VERSION ""

NS_ :

BS_:

BU_: MDC PAS

BO_ 1722 PDCDistance: 20 Vector__XXX
 SG_ PDC_SensorRRSDis : 131|12@0+ (1,0) [0|3276] "cm" Vector__XXX
 SG_ PDC_SensorRRMDis : 107|12@0+ (1,0) [0|3276] "cm" Vector__XXX
 SG_ PDC_SensorRRCDis : 127|12@0+ (1,0) [0|3276] "cm" Vector__XXX
 SG_ PDC_SensorRLSDis : 79|12@0+ (1,0) [0|3276] "cm" Vector__XXX
 SG_ PDC_SensorRLMDis : 103|12@0+ (1,0) [0|3276] "cm" Vector__XXX
 SG_ PDC_SensorRLCDis : 83|12@0+ (1,0) [0|3276] "cm" Vector__XXX
 SG_ PDC_SensorFRSDis : 59|12@0+ (1,0) [0|3276] "cm" Vector__XXX
 SG_ PDC_SensorFRMDis : 35|12@0+ (1,0) [0|3276] "cm" Vector__XXX
 SG_ PDC_SensorFRCDis : 55|12@0+ (1,0) [0|3276] "cm" Vector__XXX
 SG_ PDC_SensorFLSDis : 7|12@0+ (1,0) [0|3276] "cm" Vector__XXX
 SG_ PDC_SensorFLMDis : 31|12@0+ (1,0) [0|3276] "cm" Vector__XXX
 SG_ PDC_SensorFLCDis : 11|12@0+ (1,0) [0|3276] "cm" Vector__XXX

BO_ 1617 PDC: 12 Vector__XXX
 SG_ PDC_RRSSectorWarning : 85|3@0+ (1,0) [0|7] "" Vector__XXX
 SG_ PDC_RRMSectorWarning : 42|3@0+ (1,0) [0|7] "" Vector__XXX
 SG_ PDC_RRCSectorWarning : 45|3@0+ (1,0) [0|7] "" Vector__XXX
 SG_ PDC_RMSSectorWarning : 82|3@0+ (1,0) [0|7] "" Vector__XXX
 SG_ PDC_RLSSectorWarning : 74|3@0+ (1,0) [0|7] "" Vector__XXX
 SG_ PDC_RLMSectorWarning : 37|3@0+ (1,0) [0|7] "" Vector__XXX
 SG_ PDC_RLCSectorWarning : 34|3@0+ (1,0) [0|7] "" Vector__XXX
 SG_ PDC_RearObjNearDis : 51|12@0+ (1,0) [0|3276] "cm" Vector__XXX
 SG_ PDC_LMSSectorWarning : 69|3@0+ (1,0) [0|7] "" Vector__XXX
 SG_ PDC_FRSSectorWarning : 77|3@0+ (1,0) [0|7] "" Vector__XXX
 SG_ PDC_FrontObjNearDis : 19|12@0+ (1,0) [0|3276] "cm" Vector__XXX
 SG_ PDC_FRMSectorWarning : 10|3@0+ (1,0) [0|7] "" Vector__XXX
 SG_ PDC_FRCSectorWarning : 13|3@0+ (1,0) [0|7] "" Vector__XXX
 SG_ PDC_FLSSectorWarning : 66|3@0+ (1,0) [0|7] "" Vector__XXX
 SG_ PDC_FLMSectorWarning : 5|3@0+ (1,0) [0|7] "" Vector__XXX
 SG_ PDC_FLCSectorWarning : 2|3@0+ (1,0) [0|7] "" Vector__XXX

BO_ 1616 SensorInfo_RawDis: 48 Vector__XXX
 SG_ SensorRRS_RawDis_1 : 275|12@0+ (1,0) [0|3276] "cm" Vector__XXX
 SG_ SensorRRM_RawDis_1 : 251|12@0+ (1,0) [0|3276] "cm" Vector__XXX
 SG_ SensorRRC_RawDis_1 : 271|12@0+ (1,0) [0|3276] "cm" Vector__XXX
 SG_ SensorRLS_RawDis_1 : 223|12@0+ (1,0) [0|3276] "cm" Vector__XXX
 SG_ SensorRLM_RawDis_1 : 247|12@0+ (1,0) [0|3276] "cm" Vector__XXX
 SG_ SensorRLC_RawDis_1 : 227|12@0+ (1,0) [0|3276] "cm" Vector__XXX
 SG_ SensorFRM_RawDis_1 : 175|12@0+ (1,0) [0|3276] "cm" Vector__XXX
 SG_ SensorFRC_RawDis_1 : 155|12@0+ (1,0) [0|3276] "cm" Vector__XXX
 SG_ SensorFLS_RawDis_1 : 203|12@0+ (1,0) [0|3276] "cm" Vector__XXX
 SG_ SensorFLM_RawDis_1 : 179|12@0+ (1,0) [0|3276] "cm" Vector__XXX
 SG_ SensorFLC_RawDis_1 : 199|12@0+ (1,0) [0|3276] "cm" Vector__XXX
 SG_ SensorFRS_RawDis_1 : 151|12@0+ (1,0) [0|3276] "cm" Vector__XXX
 SG_ SensorRRS_RawDis : 131|12@0+ (1,0) [0|3276] "cm" Vector__XXX
 SG_ SensorRRC_RawDis : 127|12@0+ (1,0) [0|3276] "cm" Vector__XXX
 SG_ SensorRRM_RawDis : 107|12@0+ (1,0) [0|3276] "cm" Vector__XXX
 SG_ SensorRLM_RawDis : 103|12@0+ (1,0) [0|3276] "cm" Vector__XXX
 SG_ SensorRLC_RawDis : 83|12@0+ (1,0) [0|3276] "cm" Vector__XXX
 SG_ SensorRLS_RawDis : 79|12@0+ (1,0) [0|3276] "cm" Vector__XXX
 SG_ SensorFLS_RawDis : 59|12@0+ (1,0) [0|3276] "cm" Vector__XXX
 SG_ SensorFLC_RawDis : 55|12@0+ (1,0) [0|3276] "cm" Vector__XXX
 SG_ SensorFLM_RawDis : 35|12@0+ (1,0) [0|3276] "cm" Vector__XXX
 SG_ SensorFRM_RawDis : 31|12@0+ (1,0) [0|3276] "cm" Vector__XXX
 SG_ SensorFRC_RawDis : 11|12@0+ (1,0) [0|3276] "cm" Vector__XXX
 SG_ SensorFRS_RawDis : 7|12@0+ (1,0) [0|3276] "cm" Vector__XXX

BO_ 1600 CarInfo: 64 Vector__XXX
 SG_ VehiclePosition_Angle_BeforeRst : 151|16@0+ (0.1,-180) [-180|180] "deg" Vector__XXX
 SG_ VehiclePosition_Y_BeforeRst : 135|16@0+ (1,-3276) [-3276|3276] "cm" Vector__XXX
 SG_ VehiclePosition_X_BeforeRst : 119|16@0+ (1,-3276) [-3276|3276] "cm" Vector__XXX
 SG_ VehiclePosition_Angle_Self : 103|16@0+ (0.1,-180) [-180|180] "deg" Vector__XXX
 SG_ VehiclePosition_Y_Self : 87|16@0+ (1,-3276) [-3276|3276] "cm" Vector__XXX
 SG_ VehiclePosition_X_Self : 71|16@0+ (1,-3276) [-3276|3276] "cm" Vector__XXX
 SG_ VehiclePosition_Y : 23|16@0+ (1,-3276) [-3276|3276] "cm" Vector__XXX
 SG_ VehiclePosition_X : 7|16@0+ (1,-3276) [-3276|3276] "cm" Vector__XXX
 SG_ VehiclePosition_speed : 52|13@0+ (0.05625,0) [0|270] "km/h" Vector__XXX
 SG_ VehiclePosition_Gear : 55|3@0+ (1,0) [0|7] "" Vector__XXX
 SG_ VehiclePosition_Angle : 39|16@0+ (0.1,-180) [-180|180] "deg" Vector__XXX

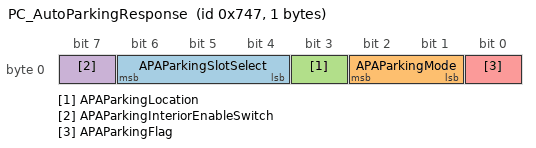
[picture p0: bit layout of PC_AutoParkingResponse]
BO_ 1863 PC_AutoParkingResponse: 1 Vector__XXX
 SG_ APAParkingSlotSelect : 6|3@0+ (1,0) [0|5] "" Vector__XXX
 SG_ APAParkingMode : 2|2@0+ (1,0) [0|3] "" Vector__XXX
 SG_ APAParkingLocation : 3|1@0+ (1,0) [0|1] "" Vector__XXX
 SG_ APAParkingInteriorEnableSwitch : 7|1@0+ (1,0) [0|1] "" Vector__XXX
 SG_ APAParkingFlag : 0|1@0+ (1,0) [0|1] "" Vector__XXX

BO_ 1862 LeftParkingSlot4_5: 48 Vector__XXX
 SG_ Left_ParkingSlot5_PtFY : 283|13@0+ (1,-3276) [-3276|3276] "cm" Vector__XXX
 SG_ Left_ParkingSlot5_PtFX : 264|13@0+ (1,-3276) [-3276|3276] "cm" Vector__XXX
 SG_ Left_ParkingSlot5_PtEY : 261|13@0+ (1,-3276) [-3276|3276] "cm" Vector__XXX
 SG_ Left_ParkingSlot5_PtEX : 242|13@0+ (1,-3276) [-3276|3276] "cm" Vector__XXX
 SG_ Left_ParkingSlot5_PtDY : 239|13@0+ (1,-3276) [-3276|3276] "cm" Vector__XXX
 SG_ Left_ParkingSlot5_PtDX : 220|13@0+ (1,-3276) [-3276|3276] "cm" Vector__XXX
 SG_ Left_ParkingSlot5_PtCY : 201|13@0+ (1,-3276) [-3276|3276] "cm" Vector__XXX
 SG_ Left_ParkingSlot5_PtCX : 198|13@0+ (1,-3276) [-3276|3276] "cm" Vector__XXX
 SG_ Left_ParkingSlot5_PtBY : 179|13@0+ (1,-3276) [-3276|3276] "cm" Vector__XXX
 SG_ Left_ParkingSlot5_PtBX : 160|13@0+ (1,-3276) [-3276|3276] "cm" Vector__XXX
 SG_ Left_ParkingSlot5_PtAY : 157|13@0+ (1,-3276) [-3276|3276] "cm" Vector__XXX
 SG_ Left_ParkingSlot5_PtAX : 138|13@0+ (1,-3276) [-3276|3276] "cm" Vector__XXX
 SG_ Left_ParkingSlot5_Depth : 131|9@0+ (1,0) [0|511] "cm" Vector__XXX
 SG_ Left_ParkingSlot5_Length : 127|12@0+ (1,0) [0|3276] "cm" Vector__XXX
 SG_ LeftParkingSlot5_HeightProperty : 117|3@0+ (1,0) [0|7] "%" Vector__XXX
 SG_ Left_ParkingSlot5_Type : 114|3@0+ (1,0) [0|7] "" Vector__XXX
 SG_ Left_ParkingSlot5_ID : 103|16@0+ (1,0) [0|65535] "" Vector__XXX
 SG_ Left_ParkingSlot4_PtFY : 73|13@0+ (1,-3276) [-3276|3276] "cm" Vector__XXX
 SG_ Left_ParkingSlot4_PtFX : 70|13@0+ (1,-3276) [-3276|3276] "cm" Vector__XXX
 SG_ Left_ParkingSlot4_PtEY : 51|13@0+ (1,-3276) [-3276|3276] "cm" Vector__XXX
 SG_ Left_ParkingSlot4_PtEX : 32|13@0+ (1,-3276) [-3276|3276] "cm" Vector__XXX
 SG_ Left_ParkingSlot4_PtDY : 29|13@0+ (1,-3276) [-3276|3276] "cm" Vector__XXX
 SG_ Left_ParkingSlot4_PtDX : 10|13@0+ (1,-3276) [-3276|3276] "cm" Vector__XXX
 SG_ Left_ParkingSlot4_PtCY : 7|13@0+ (1,-3276) [-3276|3276] "cm" Vector__XXX

BO_ 1721 LeftParkingSlot2_4: 48 Vector__XXX
 SG_ Left_ParkingSlot4_PtCX : 350|13@0+ (1,-3276) [-3276|3276] "cm" Vector__XXX
 SG_ Left_ParkingSlot4_PtBY : 331|13@0+ (1,-3276) [-3276|3276] "cm" Vector__XXX
 SG_ Left_ParkingSlot4_PtBX : 312|13@0+ (1,-3276) [-3276|3276] "cm" Vector__XXX
 SG_ Left_ParkingSlot4_PtAY : 309|13@0+ (1,-3276) [-3276|3276] "cm" Vector__XXX
 SG_ Left_ParkingSlot4_PtAX : 290|13@0+ (1,-3276) [-3276|3276] "cm" Vector__XXX
 SG_ Left_ParkingSlot4_Depth : 283|9@0+ (1,0) [0|511] "cm" Vector__XXX
 SG_ Left_ParkingSlot4_Length : 279|12@0+ (1,0) [0|3276] "cm" Vector__XXX
 SG_ LeftParkingSlot4_HeightProperty : 269|3@0+ (1,0) [0|7] "%" Vector__XXX
 SG_ Left_ParkingSlot4_Type : 266|3@0+ (1,0) [0|7] "" Vector__XXX
 SG_ Left_ParkingSlot4_ID : 255|16@0+ (1,0) [0|65535] "" Vector__XXX
 SG_ Left_ParkingSlot3_PtFY : 227|13@0+ (1,-3276) [-3276|3276] "cm" Vector__XXX
 SG_ Left_ParkingSlot3_PtFX : 208|13@0+ (1,-3276) [-3276|3276] "cm" Vector__XXX
 SG_ Left_ParkingSlot3_PtEY : 205|13@0+ (1,-3276) [-3276|3276] "cm" Vector__XXX
 SG_ Left_ParkingSlot3_PtEX : 186|13@0+ (1,-3276) [-3276|3276] "cm" Vector__XXX
 SG_ Left_ParkingSlot3_PtDY : 183|13@0+ (1,-3276) [-3276|3276] "cm" Vector__XXX
 SG_ Left_ParkingSlot3_PtDX : 164|13@0+ (1,-3276) [-3276|3276] "cm" Vector__XXX
 SG_ Left_ParkingSlot3_PtCY : 145|13@0+ (1,-3276) [-3276|3276] "cm" Vector__XXX
 SG_ Left_ParkingSlot3_PtCX : 142|13@0+ (1,-3276) [-3276|3276] "cm" Vector__XXX
 SG_ Left_ParkingSlot3_PtBY : 123|13@0+ (1,-3276) [-3276|3276] "cm" Vector__XXX
 SG_ Left_ParkingSlot3_PtBX : 104|13@0+ (1,-3276) [-3276|3276] "cm" Vector__XXX
 SG_ Left_ParkingSlot3_PtAY : 101|13@0+ (1,-3276) [-3276|3276] "cm" Vector__XXX
 SG_ Left_ParkingSlot3_PtAX : 82|13@0+ (1,-3276) [-3276|3276] "cm" Vector__XXX
 SG_ Left_ParkingSlot3_Depth : 75|9@0+ (1,0) [0|511] "cm" Vector__XXX
 SG_ Left_ParkingSlot3_Length : 71|12@0+ (1,0) [0|3276] "cm" Vector__XXX
 SG_ LeftParkingSlot3_HeightProperty : 61|3@0+ (1,0) [0|7] "%" Vector__XXX
 SG_ Left_ParkingSlot3_Type : 58|3@0+ (1,0) [0|7] "" Vector__XXX
 SG_ Left_ParkingSlot3_ID : 47|16@0+ (1,0) [0|65535] "" Vector__XXX
 SG_ Left_ParkingSlot2_PtFY : 29|13@0+ (1,-3276) [-3276|3276] "cm" Vector__XXX
 SG_ Left_ParkingSlot2_PtFX : 10|13@0+ (1,-3276) [-3276|3276] "cm" Vector__XXX
 SG_ Left_ParkingSlot2_PtEY : 7|13@0+ (1,-3276) [-3276|3276] "cm" Vector__XXX

BO_ 1720 LeftParkingSlot1_2: 48 PAS
 SG_ Left_ParkingSlot2_PtEX : 354|13@0+ (1,-3276) [-3276|3276] "cm" Vector__XXX
 SG_ Left_ParkingSlot2_PtDY : 351|13@0+ (1,-3276) [-3276|3276] "cm" Vector__XXX
 SG_ Left_ParkingSlot2_PtDX : 332|13@0+ (1,-3276) [-3276|3276] "cm" Vector__XXX
 SG_ Left_ParkingSlot2_PtCY : 313|13@0+ (1,-3276) [-3276|3276] "cm" Vector__XXX
 SG_ Left_ParkingSlot2_PtCX : 310|13@0+ (1,-3276) [-3276|3276] "cm" Vector__XXX
 SG_ Left_ParkingSlot2_PtBY : 291|13@0+ (1,-3276) [-3276|3276] "cm" Vector__XXX
 SG_ Left_ParkingSlot2_PtBX : 272|13@0+ (1,-3276) [-3276|3276] "cm" Vector__XXX
 SG_ Left_ParkingSlot2_PtAY : 269|13@0+ (1,-3276) [-3276|3276] "cm" Vector__XXX
 SG_ Left_ParkingSlot2_PtAX : 250|13@0+ (1,-3276) [-3276|3276] "cm" Vector__XXX
 SG_ Left_ParkingSlot2_Depth : 243|9@0+ (1,0) [0|511] "cm" Vector__XXX
 SG_ Left_ParkingSlot2_Length : 239|12@0+ (1,0) [0|3276] "cm" Vector__XXX
 SG_ LeftParkingSlot2_HeightProperty : 229|3@0+ (1,0) [0|7] "%" Vector__XXX
 SG_ Left_ParkingSlot2_Type : 226|3@0+ (1,0) [0|7] "" Vector__XXX
 SG_ Left_ParkingSlot2_ID : 215|16@0+ (1,0) [0|65535] "" Vector__XXX
 SG_ Left_ParkingSlot1_PtFY : 187|13@0+ (1,-3276) [-3276|3276] "cm" Vector__XXX
 SG_ Left_ParkingSlot1_PtFX : 168|13@0+ (1,-3276) [-3276|3276] "cm" Vector__XXX
 SG_ Left_ParkingSlot1_PtEY : 165|13@0+ (1,-3276) [-3276|3276] "cm" Vector__XXX
 SG_ Left_ParkingSlot1_PtEX : 146|13@0+ (1,-3276) [-3276|3276] "cm" Vector__XXX
 SG_ Left_ParkingSlot1_PtDY : 143|13@0+ (1,-3276) [-3276|3276] "cm" Vector__XXX
 SG_ Left_ParkingSlot1_PtDX : 124|13@0+ (1,-3276) [-3276|3276] "cm" Vector__XXX
 SG_ Left_ParkingSlot1_PtCY : 105|13@0+ (1,-3276) [-3276|3276] "cm" Vector__XXX
 SG_ Left_ParkingSlot1_PtCX : 102|13@0+ (1,-3276) [-3276|3276] "cm" Vector__XXX
 SG_ Left_ParkingSlot1_PtBY : 83|13@0+ (1,-3276) [-3276|3276] "cm" Vector__XXX
 SG_ Left_ParkingSlot1_PtBX : 64|13@0+ (1,-3276) [-3276|3276] "cm" Vector__XXX
 SG_ Left_ParkingSlot1_PtAY : 61|13@0+ (1,-3276) [-3276|3276] "cm" Vector__XXX
 SG_ Left_ParkingSlot1_PtAX : 42|13@0+ (1,-3276) [-3276|3276] "cm" Vector__XXX
 SG_ Left_ParkingSlot1_Depth : 35|9@0+ (1,0) [0|511] "cm" Vector__XXX
 SG_ Left_ParkingSlot1_Length : 31|12@0+ (1,0) [0|3276] "cm" Vector__XXX
 SG_ LeftParkingSlot1_HeightProperty : 21|3@0+ (1,0) [0|7] "%" Vector__XXX
 SG_ Left_ParkingSlot1_Type : 18|3@0+ (1,0) [0|7] "" Vector__XXX
 SG_ Left_ParkingSlot1_ID : 7|16@0+ (1,0) [0|65535] ""  MDC

BO_ 1859 RightParkingSlot4_5: 48 Vector__XXX
 SG_ Right_ParkingSlot5_PtFY : 283|13@0+ (1,-3276) [-3276|3276] "cm" Vector__XXX
 SG_ Right_ParkingSlot5_PtFX : 264|13@0+ (1,-3276) [-3276|3276] "cm" Vector__XXX
 SG_ Right_ParkingSlot5_PtEY : 261|13@0+ (1,-3276) [-3276|3276] "cm" Vector__XXX
 SG_ Right_ParkingSlot5_PtEX : 242|13@0+ (1,-3276) [-3276|3276] "cm" Vector__XXX
 SG_ Right_ParkingSlot5_PtDY : 239|13@0+ (1,-3276) [-3276|3276] "cm" Vector__XXX
 SG_ Right_ParkingSlot5_PtDX : 220|13@0+ (1,-3276) [-3276|3276] "cm" Vector__XXX
 SG_ Right_ParkingSlot5_PtCY : 201|13@0+ (1,-3276) [-3276|3276] "cm" Vector__XXX
 SG_ Right_ParkingSlot5_PtCX : 198|13@0+ (1,-3276) [-3276|3276] "cm" Vector__XXX
 SG_ Right_ParkingSlot5_PtBY : 179|13@0+ (1,-3276) [-3276|3276] "cm" Vector__XXX
 SG_ Right_ParkingSlot5_PtBX : 160|13@0+ (1,-3276) [-3276|3276] "cm" Vector__XXX
 SG_ Right_ParkingSlot5_PtAY : 157|13@0+ (1,-3276) [-3276|3276] "cm" Vector__XXX
 SG_ Right_ParkingSlot5_PtAX : 138|13@0+ (1,-3276) [-3276|3276] "cm" Vector__XXX
 SG_ Right_ParkingSlot5_Depth : 131|9@0+ (1,0) [0|511] "cm" Vector__XXX
 SG_ Right_ParkingSlot5_Length : 127|12@0+ (1,0) [0|3276] "cm" Vector__XXX
 SG_ RightParkingSlot5_HeightProperty : 117|3@0+ (1,0) [0|7] "%" Vector__XXX
 SG_ Right_ParkingSlot5_Type : 114|3@0+ (1,0) [0|7] "" Vector__XXX
 SG_ Right_ParkingSlot5_ID : 103|16@0+ (1,0) [0|65535] "" Vector__XXX
 SG_ Right_ParkingSlot4_PtFY : 73|13@0+ (1,-3276) [-3276|3276] "cm" Vector__XXX
 SG_ Right_ParkingSlot4_PtFX : 70|13@0+ (1,-3276) [-3276|3276] "cm" Vector__XXX
 SG_ Right_ParkingSlot4_PtEY : 51|13@0+ (1,-3276) [-3276|3276] "cm" Vector__XXX
 SG_ Right_ParkingSlot4_PtEX : 32|13@0+ (1,-3276) [-3276|3276] "cm" Vector__XXX
 SG_ Right_ParkingSlot4_PtDY : 29|13@0+ (1,-3276) [-3276|3276] "cm" Vector__XXX
 SG_ Right_ParkingSlot4_PtDX : 10|13@0+ (1,-3276) [-3276|3276] "cm" Vector__XXX
 SG_ Right_ParkingSlot4_PtCY : 7|13@0+ (1,-3276) [-3276|3276] "cm" Vector__XXX

BO_ 1719 RightParkingSlot2_4: 48 Vector__XXX
 SG_ Right_ParkingSlot4_PtCX : 350|13@0+ (1,-3276) [-3276|3276] "cm" Vector__XXX
 SG_ Right_ParkingSlot4_PtBY : 331|13@0+ (1,-3276) [-3276|3276] "cm" Vector__XXX
 SG_ Right_ParkingSlot4_PtBX : 312|13@0+ (1,-3276) [-3276|3276] "cm" Vector__XXX
 SG_ Right_ParkingSlot4_PtAY : 309|13@0+ (1,-3276) [-3276|3276] "cm" Vector__XXX
 SG_ Right_ParkingSlot4_PtAX : 290|13@0+ (1,-3276) [-3276|3276] "cm" Vector__XXX
 SG_ Right_ParkingSlot4_Depth : 283|9@0+ (1,0) [0|511] "cm" Vector__XXX
 SG_ Right_ParkingSlot4_Length : 279|12@0+ (1,0) [0|3276] "cm" Vector__XXX
 SG_ RightParkingSlot4_HeightProperty : 269|3@0+ (1,0) [0|7] "%" Vector__XXX
 SG_ Right_ParkingSlot4_Type : 266|3@0+ (1,0) [0|7] "" Vector__XXX
 SG_ Right_ParkingSlot4_ID : 255|16@0+ (1,0) [0|65535] "" Vector__XXX
 SG_ Right_ParkingSlot3_PtFY : 227|13@0+ (1,-3276) [-3276|3276] "cm" Vector__XXX
 SG_ Right_ParkingSlot3_PtFX : 208|13@0+ (1,-3276) [-3276|3276] "cm" Vector__XXX
 SG_ Right_ParkingSlot3_PtEY : 205|13@0+ (1,-3276) [-3276|3276] "cm" Vector__XXX
 SG_ Right_ParkingSlot3_PtEX : 186|13@0+ (1,-3276) [-3276|3276] "cm" Vector__XXX
 SG_ Right_ParkingSlot3_PtDY : 183|13@0+ (1,-3276) [-3276|3276] "cm" Vector__XXX
 SG_ Right_ParkingSlot3_PtDX : 164|13@0+ (1,-3276) [-3276|3276] "cm" Vector__XXX
 SG_ Right_ParkingSlot3_PtCY : 145|13@0+ (1,-3276) [-3276|3276] "cm" Vector__XXX
 SG_ Right_ParkingSlot3_PtCX : 142|13@0+ (1,-3276) [-3276|3276] "cm" Vector__XXX
 SG_ Right_ParkingSlot3_PtBY : 123|13@0+ (1,-3276) [-3276|3276] "cm" Vector__XXX
 SG_ Right_ParkingSlot3_PtBX : 104|13@0+ (1,-3276) [-3276|3276] "cm" Vector__XXX
 SG_ Right_ParkingSlot3_PtAY : 101|13@0+ (1,-3276) [-3276|3276] "cm" Vector__XXX
 SG_ Right_ParkingSlot3_PtAX : 82|13@0+ (1,-3276) [-3276|3276] "cm" Vector__XXX
 SG_ Right_ParkingSlot3_Depth : 75|9@0+ (1,0) [0|511] "cm" Vector__XXX
 SG_ Right_ParkingSlot3_Length : 71|12@0+ (1,0) [0|3276] "cm" Vector__XXX
 SG_ RightParkingSlot3_HeightProperty : 61|3@0+ (1,0) [0|7] "%" Vector__XXX
 SG_ Right_ParkingSlot3_Type : 58|3@0+ (1,0) [0|7] "" Vector__XXX
 SG_ Right_ParkingSlot3_ID : 47|16@0+ (1,0) [0|65535] "" Vector__XXX
 SG_ Right_ParkingSlot2_PtFY : 29|13@0+ (1,-3276) [-3276|3276] "cm" Vector__XXX
 SG_ Right_ParkingSlot2_PtFX : 10|13@0+ (1,-3276) [-3276|3276] "cm" Vector__XXX
 SG_ Right_ParkingSlot2_PtEY : 7|13@0+ (1,-3276) [-3276|3276] "cm" Vector__XXX

BO_ 1718 RightParkingSlot1_2: 48 PAS
 SG_ Right_ParkingSlot2_PtEX : 354|13@0+ (1,-3276) [-3276|3276] "cm" Vector__XXX
 SG_ Right_ParkingSlot2_PtDY : 351|13@0+ (1,-3276) [-3276|3276] "cm" Vector__XXX
 SG_ Right_ParkingSlot2_PtDX : 332|13@0+ (1,-3276) [-3276|3276] "cm" Vector__XXX
 SG_ Right_ParkingSlot2_PtCY : 313|13@0+ (1,-3276) [-3276|3276] "cm" Vector__XXX
 SG_ Right_ParkingSlot2_PtCX : 310|13@0+ (1,-3276) [-3276|3276] "cm" Vector__XXX
 SG_ Right_ParkingSlot2_PtBY : 291|13@0+ (1,-3276) [-3276|3276] "cm" Vector__XXX
 SG_ Right_ParkingSlot2_PtBX : 272|13@0+ (1,-3276) [-3276|3276] "cm" Vector__XXX
 SG_ Right_ParkingSlot2_PtAY : 269|13@0+ (1,-3276) [-3276|3276] "cm" Vector__XXX
 SG_ Right_ParkingSlot2_PtAX : 250|13@0+ (1,-3276) [-3276|3276] "cm" Vector__XXX
 SG_ Right_ParkingSlot2_Depth : 243|9@0+ (1,0) [0|511] "cm" Vector__XXX
 SG_ Right_ParkingSlot2_Length : 239|12@0+ (1,0) [0|3276] "cm" Vector__XXX
 SG_ RightParkingSlot2_HeightProperty : 229|3@0+ (1,0) [0|7] "%" Vector__XXX
 SG_ Right_ParkingSlot2_Type : 226|3@0+ (1,0) [0|7] "" Vector__XXX
 SG_ Right_ParkingSlot2_ID : 215|16@0+ (1,0) [0|65535] "" Vector__XXX
 SG_ Right_ParkingSlot1_PtFY : 187|13@0+ (1,-3276) [-3276|3276] "cm" Vector__XXX
 SG_ Right_ParkingSlot1_PtFX : 168|13@0+ (1,-3276) [-3276|3276] "cm" Vector__XXX
 SG_ Right_ParkingSlot1_PtEY : 165|13@0+ (1,-3276) [-3276|3276] "cm" Vector__XXX
 SG_ Right_ParkingSlot1_PtEX : 146|13@0+ (1,-3276) [-3276|3276] "cm" Vector__XXX
 SG_ Right_ParkingSlot1_PtDY : 143|13@0+ (1,-3276) [-3276|3276] "cm" Vector__XXX
 SG_ Right_ParkingSlot1_PtDX : 124|13@0+ (1,-3276) [-3276|3276] "cm" Vector__XXX
 SG_ Right_ParkingSlot1_PtCY : 105|13@0+ (1,-3276) [-3276|3276] "cm" Vector__XXX
 SG_ Right_ParkingSlot1_PtCX : 102|13@0+ (1,-3276) [-3276|3276] "cm" Vector__XXX
 SG_ Right_ParkingSlot1_PtBY : 83|13@0+ (1,-3276) [-3276|3276] "cm" Vector__XXX
 SG_ Right_ParkingSlot1_PtBX : 64|13@0+ (1,-3276) [-3276|3276] "cm" Vector__XXX
 SG_ Right_ParkingSlot1_PtAY : 61|13@0+ (1,-3276) [-3276|3276] "cm" Vector__XXX
 SG_ Right_ParkingSlot1_PtAX : 42|13@0+ (1,-3276) [-3276|3276] "cm" Vector__XXX
 SG_ Right_ParkingSlot1_Depth : 35|9@0+ (1,0) [0|511] "cm" Vector__XXX
 SG_ Right_ParkingSlot1_Length : 31|12@0+ (1,0) [0|3276] "cm" Vector__XXX
 SG_ RightParkingSlot1_HeightProperty : 21|3@0+ (1,0) [0|7] "%" Vector__XXX
 SG_ Right_ParkingSlot1_Type : 18|3@0+ (1,0) [0|7] "" Vector__XXX
 SG_ Right_ParkingSlot1_ID : 7|16@0+ (1,0) [0|65535] ""  MDC

BO_ 1622 ObjPointInfo_Probability_108_119: 24 PAS
 SG_ Point_119_ExistProbability : 166|7@0+ (1,0) [0|127] "%" Vector__XXX
 SG_ Point_119_AttributeProbability : 157|7@0+ (1,0) [0|127] "%" Vector__XXX
 SG_ Point_118_ExistProbability : 139|7@0+ (1,0) [0|127] "%" Vector__XXX
 SG_ Point_118_AttributeProbability : 148|7@0+ (1,0) [0|127] "%" Vector__XXX
 SG_ Point_117_ExistProbability : 121|7@0+ (1,0) [0|127] "%" Vector__XXX
 SG_ Point_117_AttributeProbability : 130|7@0+ (1,0) [0|127] "%" Vector__XXX
 SG_ Point_116_ExistProbability : 119|7@0+ (1,0) [0|127] "%" Vector__XXX
 SG_ Point_116_AttributeProbability : 112|7@0+ (1,0) [0|127] "%" Vector__XXX
 SG_ Point_115_ExistProbability : 110|7@0+ (1,0) [0|127] "%" Vector__XXX
 SG_ Point_115_AttributeProbability : 101|7@0+ (1,0) [0|127] "%" Vector__XXX
 SG_ Point_114_ExistProbability : 83|7@0+ (1,0) [0|127] "%" Vector__XXX
 SG_ Point_114_AttributeProbability : 92|7@0+ (1,0) [0|127] "%" Vector__XXX
 SG_ Point_113_ExistProbability : 65|7@0+ (1,0) [0|127] "%" Vector__XXX
 SG_ Point_113_AttributeProbability : 74|7@0+ (1,0) [0|127] "%" Vector__XXX
 SG_ Point_112_ExistProbability : 63|7@0+ (1,0) [0|127] "%" Vector__XXX
 SG_ Point_112_AttributeProbability : 56|7@0+ (1,0) [0|127] "%" Vector__XXX
 SG_ Point_111_ExistProbability : 54|7@0+ (1,0) [0|127] "%" Vector__XXX
 SG_ Point_111_AttributeProbability : 45|7@0+ (1,0) [0|127] "%" Vector__XXX
 SG_ Point_110_ExistProbability : 27|7@0+ (1,0) [0|127] "%" Vector__XXX
 SG_ Point_110_AttributeProbability : 36|7@0+ (1,0) [0|127] "%" Vector__XXX
 SG_ Point_109_ExistProbability : 9|7@0+ (1,0) [0|127] "%" Vector__XXX
 SG_ Point_109_AttributeProbability : 18|7@0+ (1,0) [0|127] "%" Vector__XXX
 SG_ Point_108_ExistProbability : 7|7@0+ (1,0) [0|127] "%" Vector__XXX
 SG_ Point_108_AttributeProbability : 0|7@0+ (1,0) [0|127] "%" Vector__XXX

BO_ 1624 ObjPointInfo_Probability_72_107: 64 PAS
 SG_ Point_107_ExistProbability : 502|7@0+ (1,0) [0|127] "%" Vector__XXX
 SG_ Point_107_AttributeProbability : 493|7@0+ (1,0) [0|127] "%" Vector__XXX
 SG_ Point_106_ExistProbability : 475|7@0+ (1,0) [0|127] "%" Vector__XXX
 SG_ Point_106_AttributeProbability : 484|7@0+ (1,0) [0|127] "%" Vector__XXX
 SG_ Point_105_ExistProbability : 457|7@0+ (1,0) [0|127] "%" Vector__XXX
 SG_ Point_105_AttributeProbability : 466|7@0+ (1,0) [0|127] "%" Vector__XXX
 SG_ Point_104_ExistProbability : 455|7@0+ (1,0) [0|127] "%" Vector__XXX
 SG_ Point_104_AttributeProbability : 448|7@0+ (1,0) [0|127] "%" Vector__XXX
 SG_ Point_103_ExistProbability : 446|7@0+ (1,0) [0|127] "%" Vector__XXX
 SG_ Point_103_AttributeProbability : 437|7@0+ (1,0) [0|127] "%" Vector__XXX
 SG_ Point_102_ExistProbability : 419|7@0+ (1,0) [0|127] "%" Vector__XXX
 SG_ Point_102_AttributeProbability : 428|7@0+ (1,0) [0|127] "%" Vector__XXX
 SG_ Point_101_ExistProbability : 401|7@0+ (1,0) [0|127] "%" Vector__XXX
 SG_ Point_101_AttributeProbability : 410|7@0+ (1,0) [0|127] "%" Vector__XXX
 SG_ Point_100_ExistProbability : 399|7@0+ (1,0) [0|127] "%" Vector__XXX
 SG_ Point_100_AttributeProbability : 392|7@0+ (1,0) [0|127] "%" Vector__XXX
 SG_ Point_99_ExistProbability : 390|7@0+ (1,0) [0|127] "%" Vector__XXX
 SG_ Point_99_AttributeProbability : 381|7@0+ (1,0) [0|127] "%" Vector__XXX
 SG_ Point_98_ExistProbability : 363|7@0+ (1,0) [0|127] "%" Vector__XXX
 SG_ Point_98_AttributeProbability : 372|7@0+ (1,0) [0|127] "%" Vector__XXX
 SG_ Point_97_ExistProbability : 345|7@0+ (1,0) [0|127] "%" Vector__XXX
 SG_ Point_97_AttributeProbability : 354|7@0+ (1,0) [0|127] "%" Vector__XXX
 SG_ Point_96_ExistProbability : 343|7@0+ (1,0) [0|127] "%" Vector__XXX
 SG_ Point_96_AttributeProbability : 336|7@0+ (1,0) [0|127] "%" Vector__XXX
 SG_ Point_95_ExistProbability : 334|7@0+ (1,0) [0|127] "%" Vector__XXX
 SG_ Point_95_AttributeProbability : 325|7@0+ (1,0) [0|127] "%" Vector__XXX
 SG_ Point_94_ExistProbability : 307|7@0+ (1,0) [0|127] "%" Vector__XXX
 SG_ Point_94_AttributeProbability : 316|7@0+ (1,0) [0|127] "%" Vector__XXX
 SG_ Point_93_ExistProbability : 289|7@0+ (1,0) [0|127] "%" Vector__XXX
 SG_ Point_93_AttributeProbability : 298|7@0+ (1,0) [0|127] "%" Vector__XXX
 SG_ Point_92_ExistProbability : 287|7@0+ (1,0) [0|127] "%" Vector__XXX
 SG_ Point_92_AttributeProbability : 280|7@0+ (1,0) [0|127] "%" Vector__XXX
 SG_ Point_91_ExistProbability : 278|7@0+ (1,0) [0|127] "%" Vector__XXX
 SG_ Point_91_AttributeProbability : 269|7@0+ (1,0) [0|127] "%" Vector__XXX
 SG_ Point_90_ExistProbability : 251|7@0+ (1,0) [0|127] "%" Vector__XXX
 SG_ Point_90_AttributeProbability : 260|7@0+ (1,0) [0|127] "%" Vector__XXX
 SG_ Point_89_ExistProbability : 233|7@0+ (1,0) [0|127] "%" Vector__XXX
 SG_ Point_89_AttributeProbability : 242|7@0+ (1,0) [0|127] "%" Vector__XXX
 SG_ Point_88_ExistProbability : 231|7@0+ (1,0) [0|127] "%" Vector__XXX
 SG_ Point_88_AttributeProbability : 224|7@0+ (1,0) [0|127] "%" Vector__XXX
 SG_ Point_87_ExistProbability : 222|7@0+ (1,0) [0|127] "%" Vector__XXX
 SG_ Point_87_AttributeProbability : 213|7@0+ (1,0) [0|127] "%" Vector__XXX
 SG_ Point_86_ExistProbability : 195|7@0+ (1,0) [0|127] "%" Vector__XXX
 SG_ Point_86_AttributeProbability : 204|7@0+ (1,0) [0|127] "%" Vector__XXX
 SG_ Point_85_ExistProbability : 177|7@0+ (1,0) [0|127] "%" Vector__XXX
 SG_ Point_85_AttributeProbability : 186|7@0+ (1,0) [0|127] "%" Vector__XXX
 SG_ Point_84_ExistProbability : 175|7@0+ (1,0) [0|127] "%" Vector__XXX
 SG_ Point_84_AttributeProbability : 168|7@0+ (1,0) [0|127] "%" Vector__XXX
 SG_ Point_83_ExistProbability : 166|7@0+ (1,0) [0|127] "%" Vector__XXX
 SG_ Point_83_AttributeProbability : 157|7@0+ (1,0) [0|127] "%" Vector__XXX
 SG_ Point_82_ExistProbability : 139|7@0+ (1,0) [0|127] "%" Vector__XXX
 SG_ Point_82_AttributeProbability : 148|7@0+ (1,0) [0|127] "%" Vector__XXX
 SG_ Point_81_ExistProbability : 121|7@0+ (1,0) [0|127] "%" Vector__XXX
 SG_ Point_81_AttributeProbability : 130|7@0+ (1,0) [0|127] "%" Vector__XXX
 SG_ Point_80_ExistProbability : 119|7@0+ (1,0) [0|127] "%" Vector__XXX
 SG_ Point_80_AttributeProbability : 112|7@0+ (1,0) [0|127] "%" Vector__XXX
 SG_ Point_79_ExistProbability : 110|7@0+ (1,0) [0|127] "%" Vector__XXX
 SG_ Point_79_AttributeProbability : 101|7@0+ (1,0) [0|127] "%" Vector__XXX
 SG_ Point_78_ExistProbability : 83|7@0+ (1,0) [0|127] "%" Vector__XXX
 SG_ Point_78_AttributeProbability : 92|7@0+ (1,0) [0|127] "%" Vector__XXX
 SG_ Point_77_ExistProbability : 65|7@0+ (1,0) [0|127] "%" Vector__XXX
 SG_ Point_77_AttributeProbability : 74|7@0+ (1,0) [0|127] "%" Vector__XXX
 SG_ Point_76_ExistProbability : 63|7@0+ (1,0) [0|127] "%" Vector__XXX
 SG_ Point_76_AttributeProbability : 56|7@0+ (1,0) [0|127] "%" Vector__XXX
 SG_ Point_75_ExistProbability : 54|7@0+ (1,0) [0|127] "%" Vector__XXX
 SG_ Point_75_AttributeProbability : 45|7@0+ (1,0) [0|127] "%" Vector__XXX
 SG_ Point_74_ExistProbability : 27|7@0+ (1,0) [0|127] "%" Vector__XXX
 SG_ Point_74_AttributeProbability : 36|7@0+ (1,0) [0|127] "%" Vector__XXX
 SG_ Point_73_ExistProbability : 9|7@0+ (1,0) [0|127] "%" Vector__XXX
 SG_ Point_73_AttributeProbability : 18|7@0+ (1,0) [0|127] "%" Vector__XXX
 SG_ Point_72_ExistProbability : 7|7@0+ (1,0) [0|127] "%" Vector__XXX
 SG_ Point_72_AttributeProbability : 0|7@0+ (1,0) [0|127] "%" Vector__XXX

BO_ 1623 ObjPointInfo_Probability_36_71: 64 PAS
 SG_ Point_71_ExistProbability : 502|7@0+ (1,0) [0|127] "%" Vector__XXX
 SG_ Point_71_AttributeProbability : 493|7@0+ (1,0) [0|127] "%" Vector__XXX
 SG_ Point_70_ExistProbability : 475|7@0+ (1,0) [0|127] "%" Vector__XXX
 SG_ Point_70_AttributeProbability : 484|7@0+ (1,0) [0|127] "%" Vector__XXX
 SG_ Point_69_ExistProbability : 457|7@0+ (1,0) [0|127] "%" Vector__XXX
 SG_ Point_69_AttributeProbability : 466|7@0+ (1,0) [0|127] "%" Vector__XXX
 SG_ Point_68_ExistProbability : 455|7@0+ (1,0) [0|127] "%" Vector__XXX
 SG_ Point_68_AttributeProbability : 448|7@0+ (1,0) [0|127] "%" Vector__XXX
 SG_ Point_67_ExistProbability : 446|7@0+ (1,0) [0|127] "%" Vector__XXX
 SG_ Point_67_AttributeProbability : 437|7@0+ (1,0) [0|127] "%" Vector__XXX
 SG_ Point_66_ExistProbability : 419|7@0+ (1,0) [0|127] "%" Vector__XXX
 SG_ Point_66_AttributeProbability : 428|7@0+ (1,0) [0|127] "%" Vector__XXX
 SG_ Point_65_ExistProbability : 401|7@0+ (1,0) [0|127] "%" Vector__XXX
 SG_ Point_65_AttributeProbability : 410|7@0+ (1,0) [0|127] "%" Vector__XXX
 SG_ Point_64_ExistProbability : 399|7@0+ (1,0) [0|127] "%" Vector__XXX
 SG_ Point_64_AttributeProbability : 392|7@0+ (1,0) [0|127] "%" Vector__XXX
 SG_ Point_63_ExistProbability : 390|7@0+ (1,0) [0|127] "%" Vector__XXX
 SG_ Point_63_AttributeProbability : 381|7@0+ (1,0) [0|127] "%" Vector__XXX
 SG_ Point_62_ExistProbability : 363|7@0+ (1,0) [0|127] "%" Vector__XXX
 SG_ Point_62_AttributeProbability : 372|7@0+ (1,0) [0|127] "%" Vector__XXX
 SG_ Point_61_ExistProbability : 345|7@0+ (1,0) [0|127] "%" Vector__XXX
 SG_ Point_61_AttributeProbability : 354|7@0+ (1,0) [0|127] "%" Vector__XXX
 SG_ Point_60_ExistProbability : 343|7@0+ (1,0) [0|127] "%" Vector__XXX
 SG_ Point_60_AttributeProbability : 336|7@0+ (1,0) [0|127] "%" Vector__XXX
 SG_ Point_59_ExistProbability : 334|7@0+ (1,0) [0|127] "%" Vector__XXX
 SG_ Point_59_AttributeProbability : 325|7@0+ (1,0) [0|127] "%" Vector__XXX
 SG_ Point_58_ExistProbability : 307|7@0+ (1,0) [0|127] "%" Vector__XXX
 SG_ Point_58_AttributeProbability : 316|7@0+ (1,0) [0|127] "%" Vector__XXX
 SG_ Point_57_ExistProbability : 289|7@0+ (1,0) [0|127] "%" Vector__XXX
 SG_ Point_57_AttributeProbability : 298|7@0+ (1,0) [0|127] "%" Vector__XXX
 SG_ Point_56_ExistProbability : 287|7@0+ (1,0) [0|127] "%" Vector__XXX
 SG_ Point_56_AttributeProbability : 280|7@0+ (1,0) [0|127] "%" Vector__XXX
 SG_ Point_55_ExistProbability : 278|7@0+ (1,0) [0|127] "%" Vector__XXX
 SG_ Point_55_AttributeProbability : 269|7@0+ (1,0) [0|127] "%" Vector__XXX
 SG_ Point_54_ExistProbability : 251|7@0+ (1,0) [0|127] "%" Vector__XXX
 SG_ Point_54_AttributeProbability : 260|7@0+ (1,0) [0|127] "%" Vector__XXX
 SG_ Point_53_ExistProbability : 233|7@0+ (1,0) [0|127] "%" Vector__XXX
 SG_ Point_53_AttributeProbability : 242|7@0+ (1,0) [0|127] "%" Vector__XXX
 SG_ Point_52_ExistProbability : 231|7@0+ (1,0) [0|127] "%" Vector__XXX
 SG_ Point_52_AttributeProbability : 224|7@0+ (1,0) [0|127] "%" Vector__XXX
 SG_ Point_51_ExistProbability : 222|7@0+ (1,0) [0|127] "%" Vector__XXX
 SG_ Point_51_AttributeProbability : 213|7@0+ (1,0) [0|127] "%" Vector__XXX
 SG_ Point_50_ExistProbability : 195|7@0+ (1,0) [0|127] "%" Vector__XXX
 SG_ Point_50_AttributeProbability : 204|7@0+ (1,0) [0|127] "%" Vector__XXX
 SG_ Point_49_ExistProbability : 177|7@0+ (1,0) [0|127] "%" Vector__XXX
 SG_ Point_49_AttributeProbability : 186|7@0+ (1,0) [0|127] "%" Vector__XXX
 SG_ Point_48_ExistProbability : 175|7@0+ (1,0) [0|127] "%" Vector__XXX
 SG_ Point_48_AttributeProbability : 168|7@0+ (1,0) [0|127] "%" Vector__XXX
 SG_ Point_47_ExistProbability : 166|7@0+ (1,0) [0|127] "%" Vector__XXX
 SG_ Point_47_AttributeProbability : 157|7@0+ (1,0) [0|127] "%" Vector__XXX
 SG_ Point_46_ExistProbability : 139|7@0+ (1,0) [0|127] "%" Vector__XXX
 SG_ Point_46_AttributeProbability : 148|7@0+ (1,0) [0|127] "%" Vector__XXX
 SG_ Point_45_ExistProbability : 121|7@0+ (1,0) [0|127] "%" Vector__XXX
 SG_ Point_45_AttributeProbability : 130|7@0+ (1,0) [0|127] "%" Vector__XXX
 SG_ Point_44_ExistProbability : 119|7@0+ (1,0) [0|127] "%" Vector__XXX
 SG_ Point_44_AttributeProbability : 112|7@0+ (1,0) [0|127] "%" Vector__XXX
 SG_ Point_43_ExistProbability : 110|7@0+ (1,0) [0|127] "%" Vector__XXX
 SG_ Point_43_AttributeProbability : 101|7@0+ (1,0) [0|127] "%" Vector__XXX
 SG_ Point_42_ExistProbability : 83|7@0+ (1,0) [0|127] "%" Vector__XXX
 SG_ Point_42_AttributeProbability : 92|7@0+ (1,0) [0|127] "%" Vector__XXX
 SG_ Point_41_ExistProbability : 65|7@0+ (1,0) [0|127] "%" Vector__XXX
 SG_ Point_41_AttributeProbability : 74|7@0+ (1,0) [0|127] "%" Vector__XXX
 SG_ Point_40_ExistProbability : 63|7@0+ (1,0) [0|127] "%" Vector__XXX
 SG_ Point_40_AttributeProbability : 56|7@0+ (1,0) [0|127] "%" Vector__XXX
 SG_ Point_39_ExistProbability : 54|7@0+ (1,0) [0|127] "%" Vector__XXX
 SG_ Point_39_AttributeProbability : 45|7@0+ (1,0) [0|127] "%" Vector__XXX
 SG_ Point_38_ExistProbability : 27|7@0+ (1,0) [0|127] "%" Vector__XXX
 SG_ Point_38_AttributeProbability : 36|7@0+ (1,0) [0|127] "%" Vector__XXX
 SG_ Point_37_ExistProbability : 9|7@0+ (1,0) [0|127] "%" Vector__XXX
 SG_ Point_37_AttributeProbability : 18|7@0+ (1,0) [0|127] "%" Vector__XXX
 SG_ Point_36_ExistProbability : 7|7@0+ (1,0) [0|127] "%" Vector__XXX
 SG_ Point_36_AttributeProbability : 0|7@0+ (1,0) [0|127] "%" Vector__XXX

BO_ 1621 ObjPointInfo_Probability_0_35: 64 PAS
 SG_ Point_35_ExistProbability : 502|7@0+ (1,0) [0|127] "%" Vector__XXX
 SG_ Point_35_AttributeProbability : 493|7@0+ (1,0) [0|127] "%" Vector__XXX
 SG_ Point_34_ExistProbability : 475|7@0+ (1,0) [0|127] "%" Vector__XXX
 SG_ Point_34_AttributeProbability : 484|7@0+ (1,0) [0|127] "%" Vector__XXX
 SG_ Point_33_ExistProbability : 457|7@0+ (1,0) [0|127] "%" Vector__XXX
 SG_ Point_33_AttributeProbability : 466|7@0+ (1,0) [0|127] "%" Vector__XXX
 SG_ Point_32_ExistProbability : 455|7@0+ (1,0) [0|127] "%" Vector__XXX
 SG_ Point_32_AttributeProbability : 448|7@0+ (1,0) [0|127] "%" Vector__XXX
 SG_ Point_31_ExistProbability : 446|7@0+ (1,0) [0|127] "%" Vector__XXX
 SG_ Point_31_AttributeProbability : 437|7@0+ (1,0) [0|127] "%" Vector__XXX
 SG_ Point_30_ExistProbability : 419|7@0+ (1,0) [0|127] "%" Vector__XXX
 SG_ Point_30_AttributeProbability : 428|7@0+ (1,0) [0|127] "%" Vector__XXX
 SG_ Point_29_ExistProbability : 401|7@0+ (1,0) [0|127] "%" Vector__XXX
 SG_ Point_29_AttributeProbability : 410|7@0+ (1,0) [0|127] "%" Vector__XXX
 SG_ Point_28_ExistProbability : 399|7@0+ (1,0) [0|127] "%" Vector__XXX
 SG_ Point_28_AttributeProbability : 392|7@0+ (1,0) [0|127] "%" Vector__XXX
 SG_ Point_27_ExistProbability : 390|7@0+ (1,0) [0|127] "%" Vector__XXX
 SG_ Point_27_AttributeProbability : 381|7@0+ (1,0) [0|127] "%" Vector__XXX
 SG_ Point_26_ExistProbability : 363|7@0+ (1,0) [0|127] "%" Vector__XXX
 SG_ Point_26_AttributeProbability : 372|7@0+ (1,0) [0|127] "%" Vector__XXX
 SG_ Point_25_ExistProbability : 345|7@0+ (1,0) [0|127] "%" Vector__XXX
 SG_ Point_25_AttributeProbability : 354|7@0+ (1,0) [0|127] "%" Vector__XXX
 SG_ Point_24_ExistProbability : 343|7@0+ (1,0) [0|127] "%" Vector__XXX
 SG_ Point_24_AttributeProbability : 336|7@0+ (1,0) [0|127] "%" Vector__XXX
 SG_ Point_23_ExistProbability : 334|7@0+ (1,0) [0|127] "%" Vector__XXX
 SG_ Point_23_AttributeProbability : 325|7@0+ (1,0) [0|127] "%" Vector__XXX
 SG_ Point_22_ExistProbability : 307|7@0+ (1,0) [0|127] "%" Vector__XXX
 SG_ Point_22_AttributeProbability : 316|7@0+ (1,0) [0|127] "%" Vector__XXX
 SG_ Point_21_ExistProbability : 289|7@0+ (1,0) [0|127] "%" Vector__XXX
 SG_ Point_21_AttributeProbability : 298|7@0+ (1,0) [0|127] "%" Vector__XXX
 SG_ Point_20_ExistProbability : 287|7@0+ (1,0) [0|127] "%" Vector__XXX
 SG_ Point_20_AttributeProbability : 280|7@0+ (1,0) [0|127] "%" Vector__XXX
 SG_ Point_19_ExistProbability : 278|7@0+ (1,0) [0|127] "%" Vector__XXX
 SG_ Point_19_AttributeProbability : 269|7@0+ (1,0) [0|127] "%" Vector__XXX
 SG_ Point_18_ExistProbability : 251|7@0+ (1,0) [0|127] "%" Vector__XXX
 SG_ Point_18_AttributeProbability : 260|7@0+ (1,0) [0|127] "%" Vector__XXX
 SG_ Point_17_ExistProbability : 233|7@0+ (1,0) [0|127] "%" Vector__XXX
 SG_ Point_17_AttributeProbability : 242|7@0+ (1,0) [0|127] "%" Vector__XXX
 SG_ Point_16_ExistProbability : 231|7@0+ (1,0) [0|127] "%" Vector__XXX
 SG_ Point_16_AttributeProbability : 224|7@0+ (1,0) [0|127] "%" Vector__XXX
 SG_ Point_15_ExistProbability : 222|7@0+ (1,0) [0|127] "%" Vector__XXX
 SG_ Point_15_AttributeProbability : 213|7@0+ (1,0) [0|127] "%" Vector__XXX
 SG_ Point_14_ExistProbability : 195|7@0+ (1,0) [0|127] "%" Vector__XXX
 SG_ Point_14_AttributeProbability : 204|7@0+ (1,0) [0|127] "%" Vector__XXX
 SG_ Point_13_ExistProbability : 177|7@0+ (1,0) [0|127] "%" Vector__XXX
 SG_ Point_13_AttributeProbability : 186|7@0+ (1,0) [0|127] "%" Vector__XXX
 SG_ Point_12_ExistProbability : 175|7@0+ (1,0) [0|127] "%" Vector__XXX
 SG_ Point_12_AttributeProbability : 168|7@0+ (1,0) [0|127] "%" Vector__XXX
 SG_ Point_11_ExistProbability : 166|7@0+ (1,0) [0|127] "%" Vector__XXX
 SG_ Point_11_AttributeProbability : 157|7@0+ (1,0) [0|127] "%" Vector__XXX
 SG_ Point_10_ExistProbability : 139|7@0+ (1,0) [0|127] "%" Vector__XXX
 SG_ Point_10_AttributeProbability : 148|7@0+ (1,0) [0|127] "%" Vector__XXX
 SG_ Point_09_ExistProbability : 121|7@0+ (1,0) [0|127] "%" Vector__XXX
 SG_ Point_09_AttributeProbability : 130|7@0+ (1,0) [0|127] "%" Vector__XXX
 SG_ Point_08_ExistProbability : 119|7@0+ (1,0) [0|127] "%" Vector__XXX
 SG_ Point_08_AttributeProbability : 112|7@0+ (1,0) [0|127] "%" Vector__XXX
 SG_ Point_07_ExistProbability : 110|7@0+ (1,0) [0|127] "%" Vector__XXX
 SG_ Point_07_AttributeProbability : 101|7@0+ (1,0) [0|127] "%" Vector__XXX
 SG_ Point_06_ExistProbability : 83|7@0+ (1,0) [0|127] "%" Vector__XXX
 SG_ Point_06_AttributeProbability : 92|7@0+ (1,0) [0|127] "%" Vector__XXX
 SG_ Point_05_ExistProbability : 65|7@0+ (1,0) [0|127] "%" Vector__XXX
 SG_ Point_05_AttributeProbability : 74|7@0+ (1,0) [0|127] "%" Vector__XXX
 SG_ Point_04_ExistProbability : 63|7@0+ (1,0) [0|127] "%" Vector__XXX
 SG_ Point_04_AttributeProbability : 56|7@0+ (1,0) [0|127] "%" Vector__XXX
 SG_ Point_03_ExistProbability : 54|7@0+ (1,0) [0|127] "%" Vector__XXX
 SG_ Point_03_AttributeProbability : 45|7@0+ (1,0) [0|127] "%" Vector__XXX
 SG_ Point_02_ExistProbability : 27|7@0+ (1,0) [0|127] "%" Vector__XXX
 SG_ Point_02_AttributeProbability : 36|7@0+ (1,0) [0|127] "%" Vector__XXX
 SG_ Point_01_ExistProbability : 9|7@0+ (1,0) [0|127] "%" Vector__XXX
 SG_ Point_01_AttributeProbability : 18|7@0+ (1,0) [0|127] "%" Vector__XXX
 SG_ Point_00_ExistProbability : 7|7@0+ (1,0) [0|127] "%" Vector__XXX
 SG_ Point_00_AttributeProbability : 0|7@0+ (1,0) [0|127] "%" Vector__XXX

BO_ 1620 ObjPointInfo_110_119: 64 PAS
 SG_ Point_119_Y : 391|13@0+ (1,-3276) [-3276|3276] "cm" Vector__XXX
 SG_ Point_119_X : 375|13@0+ (1,-3276) [-3276|3276] "cm" Vector__XXX
 SG_ Point_119_ID : 367|8@0+ (1,0) [0|255] "" Vector__XXX
 SG_ Point_119_Attribute : 394|3@0+ (1,0) [0|7] "" Vector__XXX
 SG_ Point_118_Y : 351|13@0+ (1,-3276) [-3276|3276] "cm" Vector__XXX
 SG_ Point_118_X : 335|13@0+ (1,-3276) [-3276|3276] "cm" Vector__XXX
 SG_ Point_118_ID : 327|8@0+ (1,0) [0|255] "" Vector__XXX
 SG_ Point_118_Attribute : 354|3@0+ (1,0) [0|7] "" Vector__XXX
 SG_ Point_117_Y : 311|13@0+ (1,-3276) [-3276|3276] "cm" Vector__XXX
 SG_ Point_117_X : 295|13@0+ (1,-3276) [-3276|3276] "cm" Vector__XXX
 SG_ Point_117_ID : 287|8@0+ (1,0) [0|255] "" Vector__XXX
 SG_ Point_117_Attribute : 314|3@0+ (1,0) [0|7] "" Vector__XXX
 SG_ Point_116_Y : 271|13@0+ (1,-3276) [-3276|3276] "cm" Vector__XXX
 SG_ Point_116_X : 255|13@0+ (1,-3276) [-3276|3276] "cm" Vector__XXX
 SG_ Point_116_ID : 247|8@0+ (1,0) [0|255] "" Vector__XXX
 SG_ Point_116_Attribute : 274|3@0+ (1,0) [0|7] "" Vector__XXX
 SG_ Point_115_Y : 231|13@0+ (1,-3276) [-3276|3276] "cm" Vector__XXX
 SG_ Point_115_X : 215|13@0+ (1,-3276) [-3276|3276] "cm" Vector__XXX
 SG_ Point_115_ID : 207|8@0+ (1,0) [0|255] "" Vector__XXX
 SG_ Point_115_Attribute : 234|3@0+ (1,0) [0|7] "" Vector__XXX
 SG_ Point_114_Y : 191|13@0+ (1,-3276) [-3276|3276] "cm" Vector__XXX
 SG_ Point_114_X : 175|13@0+ (1,-3276) [-3276|3276] "cm" Vector__XXX
 SG_ Point_114_ID : 167|8@0+ (1,0) [0|255] "" Vector__XXX
 SG_ Point_114_Attribute : 194|3@0+ (1,0) [0|7] "" Vector__XXX
 SG_ Point_113_Y : 151|13@0+ (1,-3276) [-3276|3276] "cm" Vector__XXX
 SG_ Point_113_X : 135|13@0+ (1,-3276) [-3276|3276] "cm" Vector__XXX
 SG_ Point_113_ID : 127|8@0+ (1,0) [0|255] "" Vector__XXX
 SG_ Point_113_Attribute : 154|3@0+ (1,0) [0|7] "" Vector__XXX
 SG_ Point_112_Y : 111|13@0+ (1,-3276) [-3276|3276] "cm" Vector__XXX
 SG_ Point_112_X : 95|13@0+ (1,-3276) [-3276|3276] "cm" Vector__XXX
 SG_ Point_112_ID : 87|8@0+ (1,0) [0|255] "" Vector__XXX
 SG_ Point_112_Attribute : 114|3@0+ (1,0) [0|7] "" Vector__XXX
 SG_ Point_111_Y : 71|13@0+ (1,-3276) [-3276|3276] "cm" Vector__XXX
 SG_ Point_111_X : 55|13@0+ (1,-3276) [-3276|3276] "cm" Vector__XXX
 SG_ Point_111_ID : 47|8@0+ (1,0) [0|255] "" Vector__XXX
 SG_ Point_111_Attribute : 74|3@0+ (1,0) [0|7] "" Vector__XXX
 SG_ Point_110_Y : 31|13@0+ (1,-3276) [-3276|3276] "cm" Vector__XXX
 SG_ Point_110_X : 15|13@0+ (1,-3276) [-3276|3276] "cm" Vector__XXX
 SG_ Point_110_ID : 7|8@0+ (1,0) [0|255] "" Vector__XXX
 SG_ Point_110_Attribute : 34|3@0+ (1,0) [0|7] "" Vector__XXX

BO_ 1619 ObjPointInfo_100_109: 64 PAS
 SG_ Point_109_Y : 391|13@0+ (1,-3276) [-3276|3276] "cm" Vector__XXX
 SG_ Point_109_X : 375|13@0+ (1,-3276) [-3276|3276] "cm" Vector__XXX
 SG_ Point_109_ID : 367|8@0+ (1,0) [0|255] "" Vector__XXX
 SG_ Point_109_Attribute : 394|3@0+ (1,0) [0|7] "" Vector__XXX
 SG_ Point_108_Y : 351|13@0+ (1,-3276) [-3276|3276] "cm" Vector__XXX
 SG_ Point_108_X : 335|13@0+ (1,-3276) [-3276|3276] "cm" Vector__XXX
 SG_ Point_108_ID : 327|8@0+ (1,0) [0|255] "" Vector__XXX
 SG_ Point_108_Attribute : 354|3@0+ (1,0) [0|7] "" Vector__XXX
 SG_ Point_107_Y : 311|13@0+ (1,-3276) [-3276|3276] "cm" Vector__XXX
 SG_ Point_107_X : 295|13@0+ (1,-3276) [-3276|3276] "cm" Vector__XXX
 SG_ Point_107_ID : 287|8@0+ (1,0) [0|255] "" Vector__XXX
 SG_ Point_107_Attribute : 314|3@0+ (1,0) [0|7] "" Vector__XXX
 SG_ Point_106_Y : 271|13@0+ (1,-3276) [-3276|3276] "cm" Vector__XXX
 SG_ Point_106_X : 255|13@0+ (1,-3276) [-3276|3276] "cm" Vector__XXX
 SG_ Point_106_ID : 247|8@0+ (1,0) [0|255] "" Vector__XXX
 SG_ Point_106_Attribute : 274|3@0+ (1,0) [0|7] "" Vector__XXX
 SG_ Point_105_Y : 231|13@0+ (1,-3276) [-3276|3276] "cm" Vector__XXX
 SG_ Point_105_X : 215|13@0+ (1,-3276) [-3276|3276] "cm" Vector__XXX
 SG_ Point_105_ID : 207|8@0+ (1,0) [0|255] "" Vector__XXX
 SG_ Point_105_Attribute : 234|3@0+ (1,0) [0|7] "" Vector__XXX
 SG_ Point_104_Y : 191|13@0+ (1,-3276) [-3276|3276] "cm" Vector__XXX
 SG_ Point_104_X : 175|13@0+ (1,-3276) [-3276|3276] "cm" Vector__XXX
 SG_ Point_104_ID : 167|8@0+ (1,0) [0|255] "" Vector__XXX
 SG_ Point_104_Attribute : 194|3@0+ (1,0) [0|7] "" Vector__XXX
 SG_ Point_103_Y : 151|13@0+ (1,-3276) [-3276|3276] "cm" Vector__XXX
 SG_ Point_103_X : 135|13@0+ (1,-3276) [-3276|3276] "cm" Vector__XXX
 SG_ Point_103_ID : 127|8@0+ (1,0) [0|255] "" Vector__XXX
 SG_ Point_103_Attribute : 154|3@0+ (1,0) [0|7] "" Vector__XXX
 SG_ Point_102_Y : 111|13@0+ (1,-3276) [-3276|3276] "cm" Vector__XXX
 SG_ Point_102_X : 95|13@0+ (1,-3276) [-3276|3276] "cm" Vector__XXX
 SG_ Point_102_ID : 87|8@0+ (1,0) [0|255] "" Vector__XXX
 SG_ Point_102_Attribute : 114|3@0+ (1,0) [0|7] "" Vector__XXX
 SG_ Point_101_Y : 71|13@0+ (1,-3276) [-3276|3276] "cm" Vector__XXX
 SG_ Point_101_X : 55|13@0+ (1,-3276) [-3276|3276] "cm" Vector__XXX
 SG_ Point_101_ID : 47|8@0+ (1,0) [0|255] "" Vector__XXX
 SG_ Point_101_Attribute : 74|3@0+ (1,0) [0|7] "" Vector__XXX
 SG_ Point_100_Y : 31|13@0+ (1,-3276) [-3276|3276] "cm" Vector__XXX
 SG_ Point_100_X : 15|13@0+ (1,-3276) [-3276|3276] "cm" Vector__XXX
 SG_ Point_100_ID : 7|8@0+ (1,0) [0|255] "" Vector__XXX
 SG_ Point_100_Attribute : 34|3@0+ (1,0) [0|7] "" Vector__XXX

BO_ 1618 ObjPointInfo_90_99: 64 PAS
 SG_ Point_99_Y : 391|13@0+ (1,-3276) [-3276|3276] "cm" Vector__XXX
 SG_ Point_99_X : 375|13@0+ (1,-3276) [-3276|3276] "cm" Vector__XXX
 SG_ Point_99_ID : 367|8@0+ (1,0) [0|255] "" Vector__XXX
 SG_ Point_99_Attribute : 394|3@0+ (1,0) [0|7] "" Vector__XXX
 SG_ Point_98_Y : 351|13@0+ (1,-3276) [-3276|3276] "cm" Vector__XXX
 SG_ Point_98_X : 335|13@0+ (1,-3276) [-3276|3276] "cm" Vector__XXX
 SG_ Point_98_ID : 327|8@0+ (1,0) [0|255] "" Vector__XXX
 SG_ Point_98_Attribute : 354|3@0+ (1,0) [0|7] "" Vector__XXX
 SG_ Point_97_Y : 311|13@0+ (1,-3276) [-3276|3276] "cm" Vector__XXX
 SG_ Point_97_X : 295|13@0+ (1,-3276) [-3276|3276] "cm" Vector__XXX
 SG_ Point_97_ID : 287|8@0+ (1,0) [0|255] "" Vector__XXX
 SG_ Point_97_Attribute : 314|3@0+ (1,0) [0|7] "" Vector__XXX
 SG_ Point_96_Y : 271|13@0+ (1,-3276) [-3276|3276] "cm" Vector__XXX
 SG_ Point_96_X : 255|13@0+ (1,-3276) [-3276|3276] "cm" Vector__XXX
 SG_ Point_96_ID : 247|8@0+ (1,0) [0|255] "" Vector__XXX
 SG_ Point_96_Attribute : 274|3@0+ (1,0) [0|7] "" Vector__XXX
 SG_ Point_95_Y : 231|13@0+ (1,-3276) [-3276|3276] "cm" Vector__XXX
 SG_ Point_95_X : 215|13@0+ (1,-3276) [-3276|3276] "cm" Vector__XXX
 SG_ Point_95_ID : 207|8@0+ (1,0) [0|255] "" Vector__XXX
 SG_ Point_95_Attribute : 234|3@0+ (1,0) [0|7] "" Vector__XXX
 SG_ Point_94_Y : 191|13@0+ (1,-3276) [-3276|3276] "cm" Vector__XXX
 SG_ Point_94_X : 175|13@0+ (1,-3276) [-3276|3276] "cm" Vector__XXX
 SG_ Point_94_ID : 167|8@0+ (1,0) [0|255] "" Vector__XXX
 SG_ Point_94_Attribute : 194|3@0+ (1,0) [0|7] "" Vector__XXX
 SG_ Point_93_Y : 151|13@0+ (1,-3276) [-3276|3276] "cm" Vector__XXX
 SG_ Point_93_X : 135|13@0+ (1,-3276) [-3276|3276] "cm" Vector__XXX
 SG_ Point_93_ID : 127|8@0+ (1,0) [0|255] "" Vector__XXX
 SG_ Point_93_Attribute : 154|3@0+ (1,0) [0|7] "" Vector__XXX
 SG_ Point_92_Y : 111|13@0+ (1,-3276) [-3276|3276] "cm" Vector__XXX
 SG_ Point_92_X : 95|13@0+ (1,-3276) [-3276|3276] "cm" Vector__XXX
 SG_ Point_92_ID : 87|8@0+ (1,0) [0|255] "" Vector__XXX
 SG_ Point_92_Attribute : 114|3@0+ (1,0) [0|7] "" Vector__XXX
 SG_ Point_91_Y : 71|13@0+ (1,-3276) [-3276|3276] "cm" Vector__XXX
 SG_ Point_91_X : 55|13@0+ (1,-3276) [-3276|3276] "cm" Vector__XXX
 SG_ Point_91_ID : 47|8@0+ (1,0) [0|255] "" Vector__XXX
 SG_ Point_91_Attribute : 74|3@0+ (1,0) [0|7] "" Vector__XXX
 SG_ Point_90_Y : 31|13@0+ (1,-3276) [-3276|3276] "cm" Vector__XXX
 SG_ Point_90_X : 15|13@0+ (1,-3276) [-3276|3276] "cm" Vector__XXX
 SG_ Point_90_ID : 7|8@0+ (1,0) [0|255] "" Vector__XXX
 SG_ Point_90_Attribute : 34|3@0+ (1,0) [0|7] "" Vector__XXX

BO_ 1731 ObjPointInfo_80_89: 64 PAS
 SG_ Point_89_Y : 391|13@0+ (1,-3276) [-3276|3276] "cm" Vector__XXX
 SG_ Point_89_X : 375|13@0+ (1,-3276) [-3276|3276] "cm" Vector__XXX
 SG_ Point_89_ID : 367|8@0+ (1,0) [0|255] "" Vector__XXX
 SG_ Point_89_Attribute : 394|3@0+ (1,0) [0|7] "" Vector__XXX
 SG_ Point_88_Y : 351|13@0+ (1,-3276) [-3276|3276] "cm" Vector__XXX
 SG_ Point_88_X : 335|13@0+ (1,-3276) [-3276|3276] "cm" Vector__XXX
 SG_ Point_88_ID : 327|8@0+ (1,0) [0|255] "" Vector__XXX
 SG_ Point_88_Attribute : 354|3@0+ (1,0) [0|7] "" Vector__XXX
 SG_ Point_87_Y : 311|13@0+ (1,-3276) [-3276|3276] "cm" Vector__XXX
 SG_ Point_87_X : 295|13@0+ (1,-3276) [-3276|3276] "cm" Vector__XXX
 SG_ Point_87_ID : 287|8@0+ (1,0) [0|255] "" Vector__XXX
 SG_ Point_87_Attribute : 314|3@0+ (1,0) [0|7] "" Vector__XXX
 SG_ Point_86_Y : 271|13@0+ (1,-3276) [-3276|3276] "cm" Vector__XXX
 SG_ Point_86_X : 255|13@0+ (1,-3276) [-3276|3276] "cm" Vector__XXX
 SG_ Point_86_ID : 247|8@0+ (1,0) [0|255] "" Vector__XXX
 SG_ Point_86_Attribute : 274|3@0+ (1,0) [0|7] "" Vector__XXX
 SG_ Point_85_Y : 231|13@0+ (1,-3276) [-3276|3276] "cm" Vector__XXX
 SG_ Point_85_X : 215|13@0+ (1,-3276) [-3276|3276] "cm" Vector__XXX
 SG_ Point_85_ID : 207|8@0+ (1,0) [0|255] "" Vector__XXX
 SG_ Point_85_Attribute : 234|3@0+ (1,0) [0|7] "" Vector__XXX
 SG_ Point_84_Y : 191|13@0+ (1,-3276) [-3276|3276] "cm" Vector__XXX
 SG_ Point_84_X : 175|13@0+ (1,-3276) [-3276|3276] "cm" Vector__XXX
 SG_ Point_84_ID : 167|8@0+ (1,0) [0|255] "" Vector__XXX
 SG_ Point_84_Attribute : 194|3@0+ (1,0) [0|7] "" Vector__XXX
 SG_ Point_83_Y : 151|13@0+ (1,-3276) [-3276|3276] "cm" Vector__XXX
 SG_ Point_83_X : 135|13@0+ (1,-3276) [-3276|3276] "cm" Vector__XXX
 SG_ Point_83_ID : 127|8@0+ (1,0) [0|255] "" Vector__XXX
 SG_ Point_83_Attribute : 154|3@0+ (1,0) [0|7] "" Vector__XXX
 SG_ Point_82_Y : 111|13@0+ (1,-3276) [-3276|3276] "cm" Vector__XXX
 SG_ Point_82_X : 95|13@0+ (1,-3276) [-3276|3276] "cm" Vector__XXX
 SG_ Point_82_ID : 87|8@0+ (1,0) [0|255] "" Vector__XXX
 SG_ Point_82_Attribute : 114|3@0+ (1,0) [0|7] "" Vector__XXX
 SG_ Point_81_Y : 71|13@0+ (1,-3276) [-3276|3276] "cm" Vector__XXX
 SG_ Point_81_X : 55|13@0+ (1,-3276) [-3276|3276] "cm" Vector__XXX
 SG_ Point_81_ID : 47|8@0+ (1,0) [0|255] "" Vector__XXX
 SG_ Point_81_Attribute : 74|3@0+ (1,0) [0|7] "" Vector__XXX
 SG_ Point_80_Y : 31|13@0+ (1,-3276) [-3276|3276] "cm" Vector__XXX
 SG_ Point_80_X : 15|13@0+ (1,-3276) [-3276|3276] "cm" Vector__XXX
 SG_ Point_80_ID : 7|8@0+ (1,0) [0|255] "" Vector__XXX
 SG_ Point_80_Attribute : 34|3@0+ (1,0) [0|7] "" Vector__XXX

BO_ 1730 ObjPointInfo_70_79: 64 PAS
 SG_ Point_79_Y : 391|13@0+ (1,-3276) [-3276|3276] "cm" Vector__XXX
 SG_ Point_79_X : 375|13@0+ (1,-3276) [-3276|3276] "cm" Vector__XXX
 SG_ Point_79_ID : 367|8@0+ (1,0) [0|255] "" Vector__XXX
 SG_ Point_79_Attribute : 394|3@0+ (1,0) [0|7] "" Vector__XXX
 SG_ Point_78_Y : 351|13@0+ (1,-3276) [-3276|3276] "cm" Vector__XXX
 SG_ Point_78_X : 335|13@0+ (1,-3276) [-3276|3276] "cm" Vector__XXX
 SG_ Point_78_ID : 327|8@0+ (1,0) [0|255] "" Vector__XXX
 SG_ Point_78_Attribute : 354|3@0+ (1,0) [0|7] "" Vector__XXX
 SG_ Point_77_Y : 311|13@0+ (1,-3276) [-3276|3276] "cm" Vector__XXX
 SG_ Point_77_X : 295|13@0+ (1,-3276) [-3276|3276] "cm" Vector__XXX
 SG_ Point_77_ID : 287|8@0+ (1,0) [0|255] "" Vector__XXX
 SG_ Point_77_Attribute : 314|3@0+ (1,0) [0|7] "" Vector__XXX
 SG_ Point_76_Y : 271|13@0+ (1,-3276) [-3276|3276] "cm" Vector__XXX
 SG_ Point_76_X : 255|13@0+ (1,-3276) [-3276|3276] "cm" Vector__XXX
 SG_ Point_76_ID : 247|8@0+ (1,0) [0|255] "" Vector__XXX
 SG_ Point_76_Attribute : 274|3@0+ (1,0) [0|7] "" Vector__XXX
 SG_ Point_75_Y : 231|13@0+ (1,-3276) [-3276|3276] "cm" Vector__XXX
 SG_ Point_75_X : 215|13@0+ (1,-3276) [-3276|3276] "cm" Vector__XXX
 SG_ Point_75_ID : 207|8@0+ (1,0) [0|255] "" Vector__XXX
 SG_ Point_75_Attribute : 234|3@0+ (1,0) [0|7] "" Vector__XXX
 SG_ Point_74_Y : 191|13@0+ (1,-3276) [-3276|3276] "cm" Vector__XXX
 SG_ Point_74_X : 175|13@0+ (1,-3276) [-3276|3276] "cm" Vector__XXX
 SG_ Point_74_ID : 167|8@0+ (1,0) [0|255] "" Vector__XXX
 SG_ Point_74_Attribute : 194|3@0+ (1,0) [0|7] "" Vector__XXX
 SG_ Point_73_Y : 151|13@0+ (1,-3276) [-3276|3276] "cm" Vector__XXX
 SG_ Point_73_X : 135|13@0+ (1,-3276) [-3276|3276] "cm" Vector__XXX
 SG_ Point_73_ID : 127|8@0+ (1,0) [0|255] "" Vector__XXX
 SG_ Point_73_Attribute : 154|3@0+ (1,0) [0|7] "" Vector__XXX
 SG_ Point_72_Y : 111|13@0+ (1,-3276) [-3276|3276] "cm" Vector__XXX
 SG_ Point_72_X : 95|13@0+ (1,-3276) [-3276|3276] "cm" Vector__XXX
 SG_ Point_72_ID : 87|8@0+ (1,0) [0|255] "" Vector__XXX
 SG_ Point_72_Attribute : 114|3@0+ (1,0) [0|7] "" Vector__XXX
 SG_ Point_71_Y : 71|13@0+ (1,-3276) [-3276|3276] "cm" Vector__XXX
 SG_ Point_71_X : 55|13@0+ (1,-3276) [-3276|3276] "cm" Vector__XXX
 SG_ Point_71_ID : 47|8@0+ (1,0) [0|255] "" Vector__XXX
 SG_ Point_71_Attribute : 74|3@0+ (1,0) [0|7] "" Vector__XXX
 SG_ Point_70_Y : 31|13@0+ (1,-3276) [-3276|3276] "cm" Vector__XXX
 SG_ Point_70_X : 15|13@0+ (1,-3276) [-3276|3276] "cm" Vector__XXX
 SG_ Point_70_ID : 7|8@0+ (1,0) [0|255] "" Vector__XXX
 SG_ Point_70_Attribute : 34|3@0+ (1,0) [0|7] "" Vector__XXX

BO_ 1729 ObjPointInfo_60_69: 64 PAS
 SG_ Point_69_Y : 391|13@0+ (1,-3276) [-3276|3276] "cm" Vector__XXX
 SG_ Point_69_X : 375|13@0+ (1,-3276) [-3276|3276] "cm" Vector__XXX
 SG_ Point_69_ID : 367|8@0+ (1,0) [0|255] "" Vector__XXX
 SG_ Point_69_Attribute : 394|3@0+ (1,0) [0|7] "" Vector__XXX
 SG_ Point_68_Y : 351|13@0+ (1,-3276) [-3276|3276] "cm" Vector__XXX
 SG_ Point_68_X : 335|13@0+ (1,-3276) [-3276|3276] "cm" Vector__XXX
 SG_ Point_68_ID : 327|8@0+ (1,0) [0|255] "" Vector__XXX
 SG_ Point_68_Attribute : 354|3@0+ (1,0) [0|7] "" Vector__XXX
 SG_ Point_67_Y : 311|13@0+ (1,-3276) [-3276|3276] "cm" Vector__XXX
 SG_ Point_67_X : 295|13@0+ (1,-3276) [-3276|3276] "cm" Vector__XXX
 SG_ Point_67_ID : 287|8@0+ (1,0) [0|255] "" Vector__XXX
 SG_ Point_67_Attribute : 314|3@0+ (1,0) [0|7] "" Vector__XXX
 SG_ Point_66_Y : 271|13@0+ (1,-3276) [-3276|3276] "cm" Vector__XXX
 SG_ Point_66_X : 255|13@0+ (1,-3276) [-3276|3276] "cm" Vector__XXX
 SG_ Point_66_ID : 247|8@0+ (1,0) [0|255] "" Vector__XXX
 SG_ Point_66_Attribute : 274|3@0+ (1,0) [0|7] "" Vector__XXX
 SG_ Point_65_Y : 231|13@0+ (1,-3276) [-3276|3276] "cm" Vector__XXX
 SG_ Point_65_X : 215|13@0+ (1,-3276) [-3276|3276] "cm" Vector__XXX
 SG_ Point_65_ID : 207|8@0+ (1,0) [0|255] "" Vector__XXX
 SG_ Point_65_Attribute : 234|3@0+ (1,0) [0|7] "" Vector__XXX
 SG_ Point_64_Y : 191|13@0+ (1,-3276) [-3276|3276] "cm" Vector__XXX
 SG_ Point_64_X : 175|13@0+ (1,-3276) [-3276|3276] "cm" Vector__XXX
 SG_ Point_64_ID : 167|8@0+ (1,0) [0|255] "" Vector__XXX
 SG_ Point_64_Attribute : 194|3@0+ (1,0) [0|7] "" Vector__XXX
 SG_ Point_63_Y : 151|13@0+ (1,-3276) [-3276|3276] "cm" Vector__XXX
 SG_ Point_63_X : 135|13@0+ (1,-3276) [-3276|3276] "cm" Vector__XXX
 SG_ Point_63_ID : 127|8@0+ (1,0) [0|255] "" Vector__XXX
 SG_ Point_63_Attribute : 154|3@0+ (1,0) [0|7] "" Vector__XXX
 SG_ Point_62_Y : 111|13@0+ (1,-3276) [-3276|3276] "cm" Vector__XXX
 SG_ Point_62_X : 95|13@0+ (1,-3276) [-3276|3276] "cm" Vector__XXX
 SG_ Point_62_ID : 87|8@0+ (1,0) [0|255] "" Vector__XXX
 SG_ Point_62_Attribute : 114|3@0+ (1,0) [0|7] "" Vector__XXX
 SG_ Point_61_Y : 71|13@0+ (1,-3276) [-3276|3276] "cm" Vector__XXX
 SG_ Point_61_X : 55|13@0+ (1,-3276) [-3276|3276] "cm" Vector__XXX
 SG_ Point_61_ID : 47|8@0+ (1,0) [0|255] "" Vector__XXX
 SG_ Point_61_Attribute : 74|3@0+ (1,0) [0|7] "" Vector__XXX
 SG_ Point_60_Y : 31|13@0+ (1,-3276) [-3276|3276] "cm" Vector__XXX
 SG_ Point_60_X : 15|13@0+ (1,-3276) [-3276|3276] "cm" Vector__XXX
 SG_ Point_60_ID : 7|8@0+ (1,0) [0|255] "" Vector__XXX
 SG_ Point_60_Attribute : 34|3@0+ (1,0) [0|7] "" Vector__XXX

BO_ 1728 ObjPointInfo_50_59: 64 PAS
 SG_ Point_59_Y : 391|13@0+ (1,-3276) [-3276|3276] "cm" Vector__XXX
 SG_ Point_59_X : 375|13@0+ (1,-3276) [-3276|3276] "cm" Vector__XXX
 SG_ Point_59_ID : 367|8@0+ (1,0) [0|255] "" Vector__XXX
 SG_ Point_59_Attribute : 394|3@0+ (1,0) [0|7] "" Vector__XXX
 SG_ Point_58_Y : 351|13@0+ (1,-3276) [-3276|3276] "cm" Vector__XXX
 SG_ Point_58_X : 335|13@0+ (1,-3276) [-3276|3276] "cm" Vector__XXX
 SG_ Point_58_ID : 327|8@0+ (1,0) [0|255] "" Vector__XXX
 SG_ Point_58_Attribute : 354|3@0+ (1,0) [0|7] "" Vector__XXX
 SG_ Point_57_Y : 311|13@0+ (1,-3276) [-3276|3276] "cm" Vector__XXX
 SG_ Point_57_X : 295|13@0+ (1,-3276) [-3276|3276] "cm" Vector__XXX
 SG_ Point_57_ID : 287|8@0+ (1,0) [0|255] "" Vector__XXX
 SG_ Point_57_Attribute : 314|3@0+ (1,0) [0|7] "" Vector__XXX
 SG_ Point_56_Y : 271|13@0+ (1,-3276) [-3276|3276] "cm" Vector__XXX
 SG_ Point_56_X : 255|13@0+ (1,-3276) [-3276|3276] "cm" Vector__XXX
 SG_ Point_56_ID : 247|8@0+ (1,0) [0|255] "" Vector__XXX
 SG_ Point_56_Attribute : 274|3@0+ (1,0) [0|7] "" Vector__XXX
 SG_ Point_55_Y : 231|13@0+ (1,-3276) [-3276|3276] "cm" Vector__XXX
 SG_ Point_55_X : 215|13@0+ (1,-3276) [-3276|3276] "cm" Vector__XXX
 SG_ Point_55_ID : 207|8@0+ (1,0) [0|255] "" Vector__XXX
 SG_ Point_55_Attribute : 234|3@0+ (1,0) [0|7] "" Vector__XXX
 SG_ Point_54_Y : 191|13@0+ (1,-3276) [-3276|3276] "cm" Vector__XXX
 SG_ Point_54_X : 175|13@0+ (1,-3276) [-3276|3276] "cm" Vector__XXX
 SG_ Point_54_ID : 167|8@0+ (1,0) [0|255] "" Vector__XXX
 SG_ Point_54_Attribute : 194|3@0+ (1,0) [0|7] "" Vector__XXX
 SG_ Point_53_Y : 151|13@0+ (1,-3276) [-3276|3276] "cm" Vector__XXX
 SG_ Point_53_X : 135|13@0+ (1,-3276) [-3276|3276] "cm" Vector__XXX
 SG_ Point_53_ID : 127|8@0+ (1,0) [0|255] "" Vector__XXX
 SG_ Point_53_Attribute : 154|3@0+ (1,0) [0|7] "" Vector__XXX
 SG_ Point_52_Y : 111|13@0+ (1,-3276) [-3276|3276] "cm" Vector__XXX
 SG_ Point_52_X : 95|13@0+ (1,-3276) [-3276|3276] "cm" Vector__XXX
 SG_ Point_52_ID : 87|8@0+ (1,0) [0|255] "" Vector__XXX
 SG_ Point_52_Attribute : 114|3@0+ (1,0) [0|7] "" Vector__XXX
 SG_ Point_51_Y : 71|13@0+ (1,-3276) [-3276|3276] "cm" Vector__XXX
 SG_ Point_51_X : 55|13@0+ (1,-3276) [-3276|3276] "cm" Vector__XXX
 SG_ Point_51_ID : 47|8@0+ (1,0) [0|255] "" Vector__XXX
 SG_ Point_51_Attribute : 74|3@0+ (1,0) [0|7] "" Vector__XXX
 SG_ Point_50_Y : 31|13@0+ (1,-3276) [-3276|3276] "cm" Vector__XXX
 SG_ Point_50_X : 15|13@0+ (1,-3276) [-3276|3276] "cm" Vector__XXX
 SG_ Point_50_ID : 7|8@0+ (1,0) [0|255] "" Vector__XXX
 SG_ Point_50_Attribute : 34|3@0+ (1,0) [0|7] "" Vector__XXX

BO_ 1727 ObjPointInfo_40_49: 64 PAS
 SG_ Point_49_Y : 391|13@0+ (1,-3276) [-3276|3276] "cm" Vector__XXX
 SG_ Point_49_X : 375|13@0+ (1,-3276) [-3276|3276] "cm" Vector__XXX
 SG_ Point_49_ID : 367|8@0+ (1,0) [0|255] "" Vector__XXX
 SG_ Point_49_Attribute : 394|3@0+ (1,0) [0|7] "" Vector__XXX
 SG_ Point_48_Y : 351|13@0+ (1,-3276) [-3276|3276] "cm" Vector__XXX
 SG_ Point_48_X : 335|13@0+ (1,-3276) [-3276|3276] "cm" Vector__XXX
 SG_ Point_48_ID : 327|8@0+ (1,0) [0|255] "" Vector__XXX
 SG_ Point_48_Attribute : 354|3@0+ (1,0) [0|7] "" Vector__XXX
 SG_ Point_47_Y : 311|13@0+ (1,-3276) [-3276|3276] "cm" Vector__XXX
 SG_ Point_47_X : 295|13@0+ (1,-3276) [-3276|3276] "cm" Vector__XXX
 SG_ Point_47_ID : 287|8@0+ (1,0) [0|255] "" Vector__XXX
 SG_ Point_47_Attribute : 314|3@0+ (1,0) [0|7] "" Vector__XXX
 SG_ Point_46_Y : 271|13@0+ (1,-3276) [-3276|3276] "cm" Vector__XXX
 SG_ Point_46_X : 255|13@0+ (1,-3276) [-3276|3276] "cm" Vector__XXX
 SG_ Point_46_ID : 247|8@0+ (1,0) [0|255] "" Vector__XXX
 SG_ Point_46_Attribute : 274|3@0+ (1,0) [0|7] "" Vector__XXX
 SG_ Point_45_Y : 231|13@0+ (1,-3276) [-3276|3276] "cm" Vector__XXX
 SG_ Point_45_X : 215|13@0+ (1,-3276) [-3276|3276] "cm" Vector__XXX
 SG_ Point_45_ID : 207|8@0+ (1,0) [0|255] "" Vector__XXX
 SG_ Point_45_Attribute : 234|3@0+ (1,0) [0|7] "" Vector__XXX
 SG_ Point_44_Y : 191|13@0+ (1,-3276) [-3276|3276] "cm" Vector__XXX
 SG_ Point_44_X : 175|13@0+ (1,-3276) [-3276|3276] "cm" Vector__XXX
 SG_ Point_44_ID : 167|8@0+ (1,0) [0|255] "" Vector__XXX
 SG_ Point_44_Attribute : 194|3@0+ (1,0) [0|7] "" Vector__XXX
 SG_ Point_43_Y : 151|13@0+ (1,-3276) [-3276|3276] "cm" Vector__XXX
 SG_ Point_43_X : 135|13@0+ (1,-3276) [-3276|3276] "cm" Vector__XXX
 SG_ Point_43_ID : 127|8@0+ (1,0) [0|255] "" Vector__XXX
 SG_ Point_43_Attribute : 154|3@0+ (1,0) [0|7] "" Vector__XXX
 SG_ Point_42_Y : 111|13@0+ (1,-3276) [-3276|3276] "cm" Vector__XXX
 SG_ Point_42_X : 95|13@0+ (1,-3276) [-3276|3276] "cm" Vector__XXX
 SG_ Point_42_ID : 87|8@0+ (1,0) [0|255] "" Vector__XXX
 SG_ Point_42_Attribute : 114|3@0+ (1,0) [0|7] "" Vector__XXX
 SG_ Point_41_Y : 71|13@0+ (1,-3276) [-3276|3276] "cm" Vector__XXX
 SG_ Point_41_X : 55|13@0+ (1,-3276) [-3276|3276] "cm" Vector__XXX
 SG_ Point_41_ID : 47|8@0+ (1,0) [0|255] "" Vector__XXX
 SG_ Point_41_Attribute : 74|3@0+ (1,0) [0|7] "" Vector__XXX
 SG_ Point_40_Y : 31|13@0+ (1,-3276) [-3276|3276] "cm" Vector__XXX
 SG_ Point_40_X : 15|13@0+ (1,-3276) [-3276|3276] "cm" Vector__XXX
 SG_ Point_40_ID : 7|8@0+ (1,0) [0|255] "" Vector__XXX
 SG_ Point_40_Attribute : 34|3@0+ (1,0) [0|7] "" Vector__XXX

BO_ 1726 ObjPointInfo_30_39: 64 PAS
 SG_ Point_39_Y : 391|13@0+ (1,-3276) [-3276|3276] "cm" Vector__XXX
 SG_ Point_39_X : 375|13@0+ (1,-3276) [-3276|3276] "cm" Vector__XXX
 SG_ Point_39_ID : 367|8@0+ (1,0) [0|255] "" Vector__XXX
 SG_ Point_39_Attribute : 394|3@0+ (1,0) [0|7] "" Vector__XXX
 SG_ Point_38_Y : 351|13@0+ (1,-3276) [-3276|3276] "cm" Vector__XXX
 SG_ Point_38_X : 335|13@0+ (1,-3276) [-3276|3276] "cm" Vector__XXX
 SG_ Point_38_ID : 327|8@0+ (1,0) [0|255] "" Vector__XXX
 SG_ Point_38_Attribute : 354|3@0+ (1,0) [0|7] "" Vector__XXX
 SG_ Point_37_Y : 311|13@0+ (1,-3276) [-3276|3276] "cm" Vector__XXX
 SG_ Point_37_X : 295|13@0+ (1,-3276) [-3276|3276] "cm" Vector__XXX
 SG_ Point_37_ID : 287|8@0+ (1,0) [0|255] "" Vector__XXX
 SG_ Point_37_Attribute : 314|3@0+ (1,0) [0|7] "" Vector__XXX
 SG_ Point_36_Y : 271|13@0+ (1,-3276) [-3276|3276] "cm" Vector__XXX
 SG_ Point_36_X : 255|13@0+ (1,-3276) [-3276|3276] "cm" Vector__XXX
 SG_ Point_36_ID : 247|8@0+ (1,0) [0|255] "" Vector__XXX
 SG_ Point_36_Attribute : 274|3@0+ (1,0) [0|7] "" Vector__XXX
 SG_ Point_35_Y : 231|13@0+ (1,-3276) [-3276|3276] "cm" Vector__XXX
 SG_ Point_35_X : 215|13@0+ (1,-3276) [-3276|3276] "cm" Vector__XXX
 SG_ Point_35_ID : 207|8@0+ (1,0) [0|255] "" Vector__XXX
 SG_ Point_35_Attribute : 234|3@0+ (1,0) [0|7] "" Vector__XXX
 SG_ Point_34_Y : 191|13@0+ (1,-3276) [-3276|3276] "cm" Vector__XXX
 SG_ Point_34_X : 175|13@0+ (1,-3276) [-3276|3276] "cm" Vector__XXX
 SG_ Point_34_ID : 167|8@0+ (1,0) [0|255] "" Vector__XXX
 SG_ Point_34_Attribute : 194|3@0+ (1,0) [0|7] "" Vector__XXX
 SG_ Point_33_Y : 151|13@0+ (1,-3276) [-3276|3276] "cm" Vector__XXX
 SG_ Point_33_X : 135|13@0+ (1,-3276) [-3276|3276] "cm" Vector__XXX
 SG_ Point_33_ID : 127|8@0+ (1,0) [0|255] "" Vector__XXX
 SG_ Point_33_Attribute : 154|3@0+ (1,0) [0|7] "" Vector__XXX
 SG_ Point_32_Y : 111|13@0+ (1,-3276) [-3276|3276] "cm" Vector__XXX
 SG_ Point_32_X : 95|13@0+ (1,-3276) [-3276|3276] "cm" Vector__XXX
 SG_ Point_32_ID : 87|8@0+ (1,0) [0|255] "" Vector__XXX
 SG_ Point_32_Attribute : 114|3@0+ (1,0) [0|7] "" Vector__XXX
 SG_ Point_31_Y : 71|13@0+ (1,-3276) [-3276|3276] "cm" Vector__XXX
 SG_ Point_31_X : 55|13@0+ (1,-3276) [-3276|3276] "cm" Vector__XXX
 SG_ Point_31_ID : 47|8@0+ (1,0) [0|255] "" Vector__XXX
 SG_ Point_31_Attribute : 74|3@0+ (1,0) [0|7] "" Vector__XXX
 SG_ Point_30_Y : 31|13@0+ (1,-3276) [-3276|3276] "cm" Vector__XXX
 SG_ Point_30_X : 15|13@0+ (1,-3276) [-3276|3276] "cm" Vector__XXX
 SG_ Point_30_ID : 7|8@0+ (1,0) [0|255] "" Vector__XXX
 SG_ Point_30_Attribute : 34|3@0+ (1,0) [0|7] "" Vector__XXX

BO_ 1725 ObjPointInfo_20_29: 64 PAS
 SG_ Point_29_Y : 391|13@0+ (1,-3276) [-3276|3276] "cm" Vector__XXX
 SG_ Point_29_X : 375|13@0+ (1,-3276) [-3276|3276] "cm" Vector__XXX
 SG_ Point_29_ID : 367|8@0+ (1,0) [0|255] "" Vector__XXX
 SG_ Point_29_Attribute : 394|3@0+ (1,0) [0|7] "" Vector__XXX
 SG_ Point_28_Y : 351|13@0+ (1,-3276) [-3276|3276] "cm" Vector__XXX
 SG_ Point_28_X : 335|13@0+ (1,-3276) [-3276|3276] "cm" Vector__XXX
 SG_ Point_28_ID : 327|8@0+ (1,0) [0|255] "" Vector__XXX
 SG_ Point_28_Attribute : 354|3@0+ (1,0) [0|7] "" Vector__XXX
 SG_ Point_27_Y : 311|13@0+ (1,-3276) [-3276|3276] "cm" Vector__XXX
 SG_ Point_27_X : 295|13@0+ (1,-3276) [-3276|3276] "cm" Vector__XXX
 SG_ Point_27_ID : 287|8@0+ (1,0) [0|255] "" Vector__XXX
 SG_ Point_27_Attribute : 314|3@0+ (1,0) [0|7] "" Vector__XXX
 SG_ Point_26_Y : 271|13@0+ (1,-3276) [-3276|3276] "cm" Vector__XXX
 SG_ Point_26_X : 255|13@0+ (1,-3276) [-3276|3276] "cm" Vector__XXX
 SG_ Point_26_ID : 247|8@0+ (1,0) [0|255] "" Vector__XXX
 SG_ Point_26_Attribute : 274|3@0+ (1,0) [0|7] "" Vector__XXX
 SG_ Point_25_Y : 231|13@0+ (1,-3276) [-3276|3276] "cm" Vector__XXX
 SG_ Point_25_X : 215|13@0+ (1,-3276) [-3276|3276] "cm" Vector__XXX
 SG_ Point_25_ID : 207|8@0+ (1,0) [0|255] "" Vector__XXX
 SG_ Point_25_Attribute : 234|3@0+ (1,0) [0|7] "" Vector__XXX
 SG_ Point_24_Y : 191|13@0+ (1,-3276) [-3276|3276] "cm" Vector__XXX
 SG_ Point_24_X : 175|13@0+ (1,-3276) [-3276|3276] "cm" Vector__XXX
 SG_ Point_24_ID : 167|8@0+ (1,0) [0|255] "" Vector__XXX
 SG_ Point_24_Attribute : 194|3@0+ (1,0) [0|7] "" Vector__XXX
 SG_ Point_23_Y : 151|13@0+ (1,-3276) [-3276|3276] "cm" Vector__XXX
 SG_ Point_23_X : 135|13@0+ (1,-3276) [-3276|3276] "cm" Vector__XXX
 SG_ Point_23_ID : 127|8@0+ (1,0) [0|255] "" Vector__XXX
 SG_ Point_23_Attribute : 154|3@0+ (1,0) [0|7] "" Vector__XXX
 SG_ Point_22_Y : 111|13@0+ (1,-3276) [-3276|3276] "cm" Vector__XXX
 SG_ Point_22_X : 95|13@0+ (1,-3276) [-3276|3276] "cm" Vector__XXX
 SG_ Point_22_ID : 87|8@0+ (1,0) [0|255] "" Vector__XXX
 SG_ Point_22_Attribute : 114|3@0+ (1,0) [0|7] "" Vector__XXX
 SG_ Point_21_Y : 71|13@0+ (1,-3276) [-3276|3276] "cm" Vector__XXX
 SG_ Point_21_X : 55|13@0+ (1,-3276) [-3276|3276] "cm" Vector__XXX
 SG_ Point_21_ID : 47|8@0+ (1,0) [0|255] "" Vector__XXX
 SG_ Point_21_Attribute : 74|3@0+ (1,0) [0|7] "" Vector__XXX
 SG_ Point_20_Y : 31|13@0+ (1,-3276) [-3276|3276] "cm" Vector__XXX
 SG_ Point_20_X : 15|13@0+ (1,-3276) [-3276|3276] "cm" Vector__XXX
 SG_ Point_20_ID : 7|8@0+ (1,0) [0|255] "" Vector__XXX
 SG_ Point_20_Attribute : 34|3@0+ (1,0) [0|7] "" Vector__XXX

BO_ 1724 ObjPointInfo_10_19: 64 PAS
 SG_ Point_19_Y : 391|13@0+ (1,-3276) [-3276|3276] "cm" Vector__XXX
 SG_ Point_19_X : 375|13@0+ (1,-3276) [-3276|3276] "cm" Vector__XXX
 SG_ Point_19_ID : 367|8@0+ (1,0) [0|255] "" Vector__XXX
 SG_ Point_19_Attribute : 394|3@0+ (1,0) [0|7] "" Vector__XXX
 SG_ Point_18_Y : 351|13@0+ (1,-3276) [-3276|3276] "cm" Vector__XXX
 SG_ Point_18_X : 335|13@0+ (1,-3276) [-3276|3276] "cm" Vector__XXX
 SG_ Point_18_ID : 327|8@0+ (1,0) [0|255] "" Vector__XXX
 SG_ Point_18_Attribute : 354|3@0+ (1,0) [0|7] "" Vector__XXX
 SG_ Point_17_Y : 311|13@0+ (1,-3276) [-3276|3276] "cm" Vector__XXX
 SG_ Point_17_X : 295|13@0+ (1,-3276) [-3276|3276] "cm" Vector__XXX
 SG_ Point_17_ID : 287|8@0+ (1,0) [0|255] "" Vector__XXX
 SG_ Point_17_Attribute : 314|3@0+ (1,0) [0|7] "" Vector__XXX
 SG_ Point_16_Y : 271|13@0+ (1,-3276) [-3276|3276] "cm" Vector__XXX
 SG_ Point_16_X : 255|13@0+ (1,-3276) [-3276|3276] "cm" Vector__XXX
 SG_ Point_16_ID : 247|8@0+ (1,0) [0|255] "" Vector__XXX
 SG_ Point_16_Attribute : 274|3@0+ (1,0) [0|7] "" Vector__XXX
 SG_ Point_15_Y : 231|13@0+ (1,-3276) [-3276|3276] "cm" Vector__XXX
 SG_ Point_15_X : 215|13@0+ (1,-3276) [-3276|3276] "cm" Vector__XXX
 SG_ Point_15_ID : 207|8@0+ (1,0) [0|255] "" Vector__XXX
 SG_ Point_15_Attribute : 234|3@0+ (1,0) [0|7] "" Vector__XXX
 SG_ Point_14_Y : 191|13@0+ (1,-3276) [-3276|3276] "cm" Vector__XXX
 SG_ Point_14_X : 175|13@0+ (1,-3276) [-3276|3276] "cm" Vector__XXX
 SG_ Point_14_ID : 167|8@0+ (1,0) [0|255] "" Vector__XXX
 SG_ Point_14_Attribute : 194|3@0+ (1,0) [0|7] "" Vector__XXX
 SG_ Point_13_Y : 151|13@0+ (1,-3276) [-3276|3276] "cm" Vector__XXX
 SG_ Point_13_X : 135|13@0+ (1,-3276) [-3276|3276] "cm" Vector__XXX
 SG_ Point_13_ID : 127|8@0+ (1,0) [0|255] "" Vector__XXX
 SG_ Point_13_Attribute : 154|3@0+ (1,0) [0|7] "" Vector__XXX
 SG_ Point_12_Y : 111|13@0+ (1,-3276) [-3276|3276] "cm" Vector__XXX
 SG_ Point_12_X : 95|13@0+ (1,-3276) [-3276|3276] "cm" Vector__XXX
 SG_ Point_12_ID : 87|8@0+ (1,0) [0|255] "" Vector__XXX
 SG_ Point_12_Attribute : 114|3@0+ (1,0) [0|7] "" Vector__XXX
 SG_ Point_11_Y : 71|13@0+ (1,-3276) [-3276|3276] "cm" Vector__XXX
 SG_ Point_11_X : 55|13@0+ (1,-3276) [-3276|3276] "cm" Vector__XXX
 SG_ Point_11_ID : 47|8@0+ (1,0) [0|255] "" Vector__XXX
 SG_ Point_11_Attribute : 74|3@0+ (1,0) [0|7] "" Vector__XXX
 SG_ Point_10_Y : 31|13@0+ (1,-3276) [-3276|3276] "cm" Vector__XXX
 SG_ Point_10_X : 15|13@0+ (1,-3276) [-3276|3276] "cm" Vector__XXX
 SG_ Point_10_ID : 7|8@0+ (1,0) [0|255] "" Vector__XXX
 SG_ Point_10_Attribute : 34|3@0+ (1,0) [0|7] "" Vector__XXX

BO_ 1723 ObjPointInfo_0_9: 64 PAS
 SG_ Point_09_Y : 399|13@0+ (1,-3276) [-3276|3276] "cm" Vector__XXX
 SG_ Point_09_X : 383|13@0+ (1,-3276) [-3276|3276] "cm" Vector__XXX
 SG_ Point_09_ID : 375|8@0+ (1,0) [0|255] "" Vector__XXX
 SG_ Point_09_Attribute : 402|3@0+ (1,0) [0|7] "" Vector__XXX
 SG_ Point_08_Y : 359|13@0+ (1,-3276) [-3276|3276] "cm" Vector__XXX
 SG_ Point_08_X : 343|13@0+ (1,-3276) [-3276|3276] "cm" Vector__XXX
 SG_ Point_08_ID : 335|8@0+ (1,0) [0|255] "" Vector__XXX
 SG_ Point_08_Attribute : 362|3@0+ (1,0) [0|7] "" Vector__XXX
 SG_ Point_07_Y : 319|13@0+ (1,-3276) [-3276|3276] "cm" Vector__XXX
 SG_ Point_07_X : 303|13@0+ (1,-3276) [-3276|3276] "cm" Vector__XXX
 SG_ Point_07_ID : 295|8@0+ (1,0) [0|255] "" Vector__XXX
 SG_ Point_07_Attribute : 322|3@0+ (1,0) [0|7] "" Vector__XXX
 SG_ Point_06_Y : 279|13@0+ (1,-3276) [-3276|3276] "cm" Vector__XXX
 SG_ Point_06_X : 263|13@0+ (1,-3276) [-3276|3276] "cm" Vector__XXX
 SG_ Point_06_ID : 255|8@0+ (1,0) [0|255] "" Vector__XXX
 SG_ Point_06_Attribute : 282|3@0+ (1,0) [0|7] "" Vector__XXX
 SG_ Point_05_Y : 239|13@0+ (1,-3276) [-3276|3276] "cm" Vector__XXX
 SG_ Point_05_X : 223|13@0+ (1,-3276) [-3276|3276] "cm" Vector__XXX
 SG_ Point_05_ID : 215|8@0+ (1,0) [0|255] "" Vector__XXX
 SG_ Point_05_Attribute : 242|3@0+ (1,0) [0|7] "" Vector__XXX
 SG_ Point_04_Y : 199|13@0+ (1,-3276) [-3276|3276] "cm" Vector__XXX
 SG_ Point_04_X : 183|13@0+ (1,-3276) [-3276|3276] "cm" Vector__XXX
 SG_ Point_04_ID : 175|8@0+ (1,0) [0|255] "" Vector__XXX
 SG_ Point_04_Attribute : 202|3@0+ (1,0) [0|7] "" Vector__XXX
 SG_ Point_03_Y : 159|13@0+ (1,-3276) [-3276|3276] "cm" Vector__XXX
 SG_ Point_03_X : 143|13@0+ (1,-3276) [-3276|3276] "cm" Vector__XXX
 SG_ Point_03_ID : 135|8@0+ (1,0) [0|255] "" Vector__XXX
 SG_ Point_03_Attribute : 162|3@0+ (1,0) [0|7] "" Vector__XXX
 SG_ Point_02_Y : 119|13@0+ (1,-3276) [-3276|3276] "cm" Vector__XXX
 SG_ Point_02_X : 103|13@0+ (1,-3276) [-3276|3276] "cm" Vector__XXX
 SG_ Point_02_ID : 95|8@0+ (1,0) [0|255] "" Vector__XXX
 SG_ Point_02_Attribute : 122|3@0+ (1,0) [0|7] "" Vector__XXX
 SG_ Point_01_Y : 79|13@0+ (1,-3276) [-3276|3276] "cm" Vector__XXX
 SG_ Point_01_X : 63|13@0+ (1,-3276) [-3276|3276] "cm" Vector__XXX
 SG_ Point_01_ID : 55|8@0+ (1,0) [0|255] "" Vector__XXX
 SG_ Point_00_Attribute : 42|3@0+ (1,0) [0|7] "" Vector__XXX
 SG_ Point_ValidNum : 7|8@0+ (1,0) [0|120] "" Vector__XXX
 SG_ Point_01_Attribute : 82|3@0+ (1,0) [0|7] "" Vector__XXX
 SG_ Point_00_Y : 39|13@0+ (1,-3276) [-3276|3276] "cm" Vector__XXX
 SG_ Point_00_X : 23|13@0+ (1,-3276) [-3276|3276] "cm" Vector__XXX
 SG_ Point_00_ID : 15|8@0+ (1,0) [0|255] "" Vector__XXX

BO_ 513 PAS_Distance_Front: 64 PAS
 SG_ PAS_sonar1_DISTANCE : 455|10@0+ (1,0) [0|1023] "cm"  MDC
 SG_ PASsonar1DISTANCETime : 263|12@0+ (0.5,0) [0|1000] "ms"  MDC
 SG_ PAS_sonar1_Blind : 35|4@0+ (1,0) [0|1] "bit"  MDC
 SG_ PAS_sonar1_crossDistanceLeft : 3|10@0+ (1,0) [0|1023] "cm"  MDC
 SG_ PAS_sonar1_crossDistanceRight : 9|10@0+ (1,0) [0|1023] "cm"  MDC
 SG_ PASsonar1crossDistanceLeftTime : 267|12@0+ (0.5,0) [0|1000] "ms"  MDC
 SG_ PASsonar1crossDistanceRightTime : 287|12@0+ (0.5,0) [0|1000] "ms"  MDC
 SG_ PAS_sonar1_confidence : 31|8@0+ (1,0) [0|100] "%"  MDC
 SG_ PAS_sonar1_Counter : 39|4@0+ (1,0) [0|15] "bit"  MDC
 SG_ PAS_sonar2_DISTANCE : 461|10@0+ (1,0) [0|1023] "cm"  MDC
 SG_ PASsonar2DISTANCETime : 291|12@0+ (0.5,0) [0|1000] "ms"  MDC
 SG_ PAS_sonar2_Blind : 75|4@0+ (1,0) [0|1] "bit"  MDC
 SG_ PAS_sonar2_crossDistanceLeft : 43|10@0+ (1,0) [0|1023] "cm"  MDC
 SG_ PAS_sonar2_crossDistanceRight : 49|10@0+ (1,0) [0|1023] "cm"  MDC
 SG_ PASsonar2crossDistanceLeftTime : 311|12@0+ (0.5,0) [0|1000] "ms"  MDC
 SG_ PASsonar2crossDistanceRightTime : 315|12@0+ (0.5,0) [0|1000] "ms"  MDC
 SG_ PAS_sonar2_confidence : 71|8@0+ (1,0) [0|100] "%"  MDC
 SG_ PAS_sonar2_Counter : 79|4@0+ (1,0) [0|15] "bit"  MDC
 SG_ PAS_sonar3_DISTANCE : 467|10@0+ (1,0) [0|1023] "cm"  MDC
 SG_ PASsonar3DISTANCETime : 335|12@0+ (0.5,0) [0|1000] "ms"  MDC
 SG_ PAS_sonar3_Blind : 115|4@0+ (1,0) [0|1] "bit"  MDC
 SG_ PAS_sonar3_crossDistanceLeft : 83|10@0+ (1,0) [0|1023] "cm"  MDC
 SG_ PAS_sonar3_crossDistanceRight : 89|10@0+ (1,0) [0|1023] "cm"  MDC
 SG_ PASsonar3crossDistanceLeftTime : 339|12@0+ (0.5,0) [0|1000] "ms"  MDC
 SG_ PASsonar3crossDistanceRightTime : 359|12@0+ (0.5,0) [0|1000] "ms"  MDC
 SG_ PAS_sonar3_confidence : 111|8@0+ (1,0) [0|100] "%"  MDC
 SG_ PAS_sonar3_Counter : 119|4@0+ (1,0) [0|15] "bit"  MDC
 SG_ PAS_sonar4_DISTANCE : 473|10@0+ (1,0) [0|1023] "cm"  MDC
 SG_ PASsonar4DISTANCETime : 363|12@0+ (0.5,0) [0|1000] "ms"  MDC
 SG_ PAS_sonar4_Blind : 155|4@0+ (1,0) [0|1] "bit"  MDC
 SG_ PAS_sonar4_crossDistanceLeft : 123|10@0+ (1,0) [0|1023] "cm"  MDC
 SG_ PAS_sonar4_crossDistanceRight : 129|10@0+ (1,0) [0|1023] "cm"  MDC
 SG_ PASsonar4crossDistanceLeftTime : 383|12@0+ (0.5,0) [0|1000] "ms"  MDC
 SG_ PASsonar4crossDistanceRightTime : 387|12@0+ (0.5,0) [0|1000] "ms"  MDC
 SG_ PAS_sonar4_confidence : 151|8@0+ (1,0) [0|100] "%"  MDC
 SG_ PAS_sonar4_Counter : 159|4@0+ (1,0) [0|15] "bit"  MDC
 SG_ PAS_sonar0_DISTANCE : 167|10@0+ (1,0) [0|1023] "cm"  MDC
 SG_ PASsonar0DISTANCETime : 407|12@0+ (0.5,0) [0|1000] "ms"  MDC
 SG_ PAS_sonar0_Blind : 235|4@0+ (1,0) [0|1] "bit"  MDC
 SG_ PAS_sonar0_crossDistanceLeft : 173|10@0+ (1,0) [0|1023] "cm"  MDC
 SG_ PAS_sonar0_crossDistanceRight : 179|10@0+ (1,0) [0|1023] "cm"  MDC
 SG_ PASsonar0crossDistanceRightTime : 411|12@0+ (0.5,0) [0|1000] "ms"  MDC
 SG_ PAS_sonar0_confidence : 231|8@0+ (1,0) [0|100] "%"  MDC
 SG_ PAS_sonar0_Counter : 239|4@0+ (1,0) [0|15] "bit"  MDC
 SG_ PAS_sonar5_DISTANCE : 185|10@0+ (1,0) [0|1023] "cm"  MDC
 SG_ PASsonar5DISTANCETime : 431|12@0+ (0.5,0) [0|1000] "ms"  MDC
 SG_ PAS_sonar5_Blind : 251|4@0+ (1,0) [0|1] "bit"  MDC
 SG_ PAS_sonar5_crossDistanceLeft : 207|10@0+ (1,0) [0|1023] "cm"  MDC
 SG_ PAS_sonar5_crossDistanceRight : 213|10@0+ (1,0) [0|1023] "cm"  MDC
 SG_ PASsonar5crossDistanceLeftTime : 435|12@0+ (0.5,0) [0|1000] "ms"  MDC
 SG_ PAS_sonar5_confidence : 247|8@0+ (1,0) [0|100] "%"  MDC
 SG_ PAS_sonar5_Counter : 255|4@0+ (1,0) [0|15] "bit"  MDC
 SG_ PASDistanceFrontRollingCounter : 511|4@0+ (1,0) [0|14] "bit"  MDC
 SG_ PAS_Distance_Front_Checksum : 503|8@0+ (1,0) [0|255] "bit"  MDC
 SG_ Fill4bit : 507|4@0+ (1,0) [0|15] "bit"  MDC

BO_ 514 PAS_Distance_Rear: 64 PAS
 SG_ PAS_sonar7_DISTANCE : 455|10@0+ (1,0) [0|1023] "cm"  MDC
 SG_ PASsonar7DISTANCETime : 263|12@0+ (0.5,0) [0|1000] "ms"  MDC
 SG_ PAS_sonar7_Blind : 35|4@0+ (1,0) [0|1] "bit"  MDC
 SG_ PAS_sonar7_crossDistanceLeft : 3|10@0+ (1,0) [0|1023] "cm"  MDC
 SG_ PAS_sonar7_crossDistanceRight : 9|10@0+ (1,0) [0|1023] "cm"  MDC
 SG_ PASsonar7crossDistanceLeftTime : 267|12@0+ (0.5,0) [0|1000] "ms"  MDC
 SG_ PASsonar7crossDistanceRightTime : 287|12@0+ (0.5,0) [0|1000] "ms"  MDC
 SG_ PAS_sonar7_confidence : 31|8@0+ (1,0) [0|100] "%"  MDC
 SG_ PAS_sonar7_Counter : 39|4@0+ (1,0) [0|15] "bit"  MDC
 SG_ PAS_sonar8_DISTANCE : 461|10@0+ (1,0) [0|1023] "cm"  MDC
 SG_ PASsonar8DISTANCETime : 291|12@0+ (0.5,0) [0|1000] "ms"  MDC
 SG_ PAS_sonar8_Blind : 75|4@0+ (1,0) [0|1] "bit"  MDC
 SG_ PAS_sonar8_crossDistanceLeft : 43|10@0+ (1,0) [0|1023] "cm"  MDC
 SG_ PAS_sonar8_crossDistanceRight : 49|10@0+ (1,0) [0|1023] "cm"  MDC
 SG_ PASsonar8crossDistanceLeftTime : 311|12@0+ (0.5,0) [0|1000] "ms"  MDC
 SG_ PASsonar8crossDistanceRightTime : 315|12@0+ (0.5,0) [0|1000] "ms"  MDC
 SG_ PAS_sonar8_confidence : 71|8@0+ (1,0) [0|100] "%"  MDC
 SG_ PAS_sonar8_Counter : 79|4@0+ (1,0) [0|15] "bit"  MDC
 SG_ PAS_sonar9_DISTANCE : 467|10@0+ (1,0) [0|1023] "cm"  MDC
 SG_ PASsonar9DISTANCETime : 335|12@0+ (0.5,0) [0|1000] "ms"  MDC
 SG_ PAS_sonar9_Blind : 115|4@0+ (1,0) [0|1] "bit"  MDC
 SG_ PAS_sonar9_crossDistanceLeft : 83|10@0+ (1,0) [0|1023] "cm"  MDC
 SG_ PAS_sonar9_crossDistanceRight : 89|10@0+ (1,0) [0|1023] "cm"  MDC
 SG_ PASsonar9crossDistanceLeftTime : 339|12@0+ (0.5,0) [0|1000] "ms"  MDC
 SG_ PASsonar9crossDistanceRightTime : 359|12@0+ (0.5,0) [0|1000] "ms"  MDC
 SG_ PAS_sonar9_confidence : 111|8@0+ (1,0) [0|100] "%"  MDC
 SG_ PAS_sonar9_Counter : 119|4@0+ (1,0) [0|15] "bit"  MDC
 SG_ PAS_sonar10_DISTANCE : 473|10@0+ (1,0) [0|1023] "cm"  MDC
 SG_ PASsonar10DISTANCETime : 363|12@0+ (0.5,0) [0|1000] "ms"  MDC
 SG_ PAS_sonar10_Blind : 155|4@0+ (1,0) [0|1] "bit"  MDC
 SG_ PAS_sonar10_crossDistanceLeft : 123|10@0+ (1,0) [0|1023] "cm"  MDC
 SG_ PAS_sonar10_crossDistanceRight : 129|10@0+ (1,0) [0|1023] "cm"  MDC
 SG_ PASsonar10crossDistanceLeftTime : 383|12@0+ (0.5,0) [0|1000] "ms"  MDC
 SG_ PASsonar10crossDistanceRightTime : 387|12@0+ (0.5,0) [0|1000] "ms"  MDC
 SG_ PAS_sonar10_confidence : 151|8@0+ (1,0) [0|100] "%"  MDC
 SG_ PAS_sonar10_Counter : 159|4@0+ (1,0) [0|15] "bit"  MDC
 SG_ PAS_sonar6_DISTANCE : 167|10@0+ (1,0) [0|1023] "cm"  MDC
 SG_ PASsonar6DISTANCETime : 407|12@0+ (0.5,0) [0|1000] "ms"  MDC
 SG_ PAS_sonar6_Blind : 235|4@0+ (1,0) [0|1] "bit"  MDC
 SG_ PAS_sonar6_crossDistanceLeft : 173|10@0+ (1,0) [0|1023] "cm"  MDC
 SG_ PAS_sonar6_crossDistanceRight : 179|10@0+ (1,0) [0|1023] "cm"  MDC
 SG_ PASsonar6crossDistanceRightTime : 411|12@0+ (0.5,0) [0|1000] "ms"  MDC
 SG_ PAS_sonar6_confidence : 231|8@0+ (1,0) [0|100] "%"  MDC
 SG_ PAS_sonar6_Counter : 239|4@0+ (1,0) [0|15] "bit"  MDC
 SG_ PAS_sonar11_DISTANCE : 185|10@0+ (1,0) [0|1023] "cm"  MDC
 SG_ PASsonar11DISTANCETime : 431|12@0+ (0.5,0) [0|1000] "ms"  MDC
 SG_ PAS_sonar11_Blind : 251|4@0+ (1,0) [0|1] "bit"  MDC
 SG_ PAS_sonar11_crossDistanceLeft : 207|10@0+ (1,0) [0|1023] "cm"  MDC
 SG_ PAS_sonar11_crossDistanceRight : 213|10@0+ (1,0) [0|1023] "cm"  MDC
 SG_ PASsonar11crossDistanceLeftTime : 435|12@0+ (0.5,0) [0|1000] "ms"  MDC
 SG_ PAS_sonar11_confidence : 247|8@0+ (1,0) [0|100] "%"  MDC
 SG_ PAS_sonar11_Counter : 255|4@0+ (1,0) [0|15] "bit"  MDC
 SG_ PAS_Distance_Rear_RollingCounter : 511|4@0+ (1,0) [0|14] "bit"  MDC
 SG_ PAS_Distance_Rear_Checksum : 503|8@0+ (1,0) [0|255] "bit"  MDC
 SG_ Fill4bit : 507|4@0+ (1,0) [0|15] "bit"  MDC

BO_ 515 PAS_SonarInfo_Front: 64 PAS
 SG_ PAS_Sonar0_Echo_TOF1 : 7|16@0+ (1,0) [0|65535] "us"  MDC
 SG_ PAS_Sonar0_Echo_Width1 : 23|8@0+ (16,0) [0|4080] "us"  MDC
 SG_ PAS_Sonar0_Echo_TOF2 : 31|16@0+ (1,0) [0|65535] "us"  MDC
 SG_ PAS_Sonar0_Echo_Width2 : 47|8@0+ (16,0) [0|4080] "us"  MDC
 SG_ PAS_Sonar0_Echo_Peak1 : 391|6@0+ (1,0) [0|63] ""  MDC
 SG_ PAS_Sonar0_Echo_Peak2 : 385|6@0+ (1,0) [0|63] ""  MDC
 SG_ PAS_Sonar0_Emit : 457|2@0+ (1,0) [0|2] "bit"  MDC
 SG_ PAS_Sonar0_RingingTime : 55|16@0+ (0.0412,300) [300|3000] "us"  MDC
 SG_ PAS_Sonar0_Counter : 471|4@0+ (1,0) [0|15] "bit"  MDC
 SG_ PAS_Sonar1_Echo_TOF1 : 71|16@0+ (1,0) [0|65535] "us"  MDC
 SG_ PAS_Sonar1_Echo_Width1 : 87|8@0+ (16,0) [0|4080] "us"  MDC
 SG_ PAS_Sonar1_Echo_TOF2 : 95|16@0+ (1,0) [0|65535] "us"  MDC
 SG_ PAS_Sonar1_Echo_Width2 : 111|8@0+ (16,0) [0|4080] "us"  MDC
 SG_ PAS_Sonar1_Echo_Peak1 : 395|6@0+ (1,0) [0|63] ""  MDC
 SG_ PAS_Sonar1_Echo_Peak2 : 405|6@0+ (1,0) [0|63] ""  MDC
 SG_ PAS_Sonar1_Emit : 459|2@0+ (1,0) [0|2] "bit"  MDC
 SG_ PAS_Sonar1_RingingTime : 119|16@0+ (0.0412,300) [300|3000] "us"  MDC
 SG_ PAS_Sonar1_Counter : 475|4@0+ (1,0) [0|15] "bit"  MDC
 SG_ PAS_Sonar2_Echo_TOF1 : 135|16@0+ (1,0) [0|65535] "us"  MDC
 SG_ PAS_Sonar2_Echo_Width1 : 151|8@0+ (16,0) [0|4080] "us"  MDC
 SG_ PAS_Sonar2_Echo_TOF2 : 159|16@0+ (1,0) [0|65535] "us"  MDC
 SG_ PAS_Sonar2_Echo_Width2 : 175|8@0+ (16,0) [0|4080] "us"  MDC
 SG_ PAS_Sonar2_Echo_Peak1 : 415|6@0+ (1,0) [0|63] ""  MDC
 SG_ PAS_Sonar2_Echo_Peak2 : 409|6@0+ (1,0) [0|63] ""  MDC
 SG_ PAS_Sonar2_Emit : 461|2@0+ (1,0) [0|2] "bit"  MDC
 SG_ PAS_Sonar2_RingingTime : 183|16@0+ (0.0412,300) [300|3000] "us"  MDC
 SG_ PAS_Sonar2_Counter : 479|4@0+ (1,0) [0|15] "bit"  MDC
 SG_ PAS_Sonar3_Echo_TOF1 : 199|16@0+ (1,0) [0|65535] "us"  MDC
 SG_ PAS_Sonar3_Echo_Width1 : 215|8@0+ (16,0) [0|4080] "us"  MDC
 SG_ PAS_Sonar3_Echo_TOF2 : 223|16@0+ (1,0) [0|65535] "us"  MDC
 SG_ PAS_Sonar3_Echo_Width2 : 239|8@0+ (16,0) [0|4080] "us"  MDC
 SG_ PAS_Sonar3_Echo_Peak1 : 419|6@0+ (1,0) [0|63] ""  MDC
 SG_ PAS_Sonar3_Echo_Peak2 : 429|6@0+ (1,0) [0|63] ""  MDC
 SG_ PAS_Sonar3_Emit : 463|2@0+ (1,0) [0|2] "bit"  MDC
 SG_ PAS_Sonar3_RingingTime : 247|16@0+ (0.0412,300) [300|3000] "us"  MDC
 SG_ PAS_Sonar3_Counter : 483|4@0+ (1,0) [0|15] "bit"  MDC
 SG_ PAS_Sonar4_Echo_TOF1 : 263|16@0+ (1,0) [0|65535] "us"  MDC
 SG_ PAS_Sonar4_Echo_Width1 : 279|8@0+ (16,0) [0|4080] "us"  MDC
 SG_ PAS_Sonar4_Echo_TOF2 : 287|16@0+ (1,0) [0|65535] "us"  MDC
 SG_ PAS_Sonar4_Echo_Width2 : 303|8@0+ (16,0) [0|4080] "us"  MDC
 SG_ PAS_Sonar4_Echo_Peak1 : 439|6@0+ (1,0) [0|63] ""  MDC
 SG_ PAS_Sonar4_Echo_Peak2 : 433|6@0+ (1,0) [0|63] ""  MDC
 SG_ PAS_Sonar4_Emit : 465|2@0+ (1,0) [0|2] "bit"  MDC
 SG_ PAS_Sonar4_RingingTime : 311|16@0+ (0.0412,300) [300|3000] "us"  MDC
 SG_ PAS_Sonar4_Counter : 487|4@0+ (1,0) [0|15] "bit"  MDC
 SG_ PAS_Sonar5_Echo_TOF1 : 327|16@0+ (1,0) [0|65535] "us"  MDC
 SG_ PAS_Sonar5_Echo_Width1 : 343|8@0+ (16,0) [0|4080] "us"  MDC
 SG_ PAS_Sonar5_Echo_TOF2 : 351|16@0+ (1,0) [0|65535] "us"  MDC
 SG_ PAS_Sonar5_Echo_Width2 : 367|8@0+ (16,0) [0|4080] "us"  MDC
 SG_ PAS_Sonar5_Echo_Peak1 : 443|6@0+ (1,0) [0|63] ""  MDC
 SG_ PAS_Sonar5_Echo_Peak2 : 453|6@0+ (1,0) [0|63] ""  MDC
 SG_ PAS_Sonar5_Emit : 467|2@0+ (1,0) [0|2] "bit"  MDC
 SG_ PAS_Sonar5_RingingTime : 375|16@0+ (0.0412,300) [300|3000] "us"  MDC
 SG_ PAS_Sonar5_Counter : 491|4@0+ (1,0) [0|15] "bit"  MDC
 SG_ PASSonarInfoFrontRollingCounter : 507|4@0+ (1,0) [0|14] "bit"  MDC
 SG_ PAS_SonarInfo_Front_Checksum : 503|8@0+ (1,0) [0|255] "bit"  MDC
 SG_ Fill4bit : 511|4@0+ (1,0) [0|15] "bit"  MDC

CM_ SG_ 1722 PDC_SensorRRSDis "后右侧雷达RRS距离值";
CM_ SG_ 1722 PDC_SensorRRMDis "后右中雷达RRM距离值";
CM_ SG_ 1722 PDC_SensorRRCDis "后右角雷达RRC距离值";
CM_ SG_ 1722 PDC_SensorRLSDis "后左侧雷达RLS距离值";
CM_ SG_ 1722 PDC_SensorRLMDis "后左中雷达RLM距离值";
CM_ SG_ 1722 PDC_SensorRLCDis "后左角雷达RLC距离值";
CM_ SG_ 1722 PDC_SensorFRSDis "前右侧雷达FRS距离值";
CM_ SG_ 1722 PDC_SensorFRMDis "前右中雷达FRM距离值";
CM_ SG_ 1722 PDC_SensorFRCDis "前右角雷达FRC距离值";
CM_ SG_ 1722 PDC_SensorFLSDis "前左侧雷达FLS距离值";
CM_ SG_ 1722 PDC_SensorFLMDis "前左中雷达FLM距离值";
CM_ SG_ 1722 PDC_SensorFLCDis "前左角雷达FLC距离值";
CM_ SG_ 1617 PDC_RRSSectorWarning "后右侧区域图像分段报警";
CM_ SG_ 1617 PDC_RRMSectorWarning "后右中区域图像分段报警";
CM_ SG_ 1617 PDC_RRCSectorWarning "后右角区域图像分段报警";
CM_ SG_ 1617 PDC_RMSSectorWarning "右侧中区域图像分段报警";
CM_ SG_ 1617 PDC_RLSSectorWarning "后左侧区域图像分段报警";
CM_ SG_ 1617 PDC_RLMSectorWarning "后左中区域图像分段报警";
CM_ SG_ 1617 PDC_RLCSectorWarning "后左角区域图像分段报警";
CM_ SG_ 1617 PDC_RearObjNearDis "倒车雷达最近障碍物距离";
CM_ SG_ 1617 PDC_LMSSectorWarning "左侧中区域图像分段报警";
CM_ SG_ 1617 PDC_FRSSectorWarning "前右侧区域图像分段报警";
CM_ SG_ 1617 PDC_FrontObjNearDis "前进雷达最近障碍物距离";
CM_ SG_ 1617 PDC_FRMSectorWarning "前右中区域图像分段报警";
CM_ SG_ 1617 PDC_FRCSectorWarning "前右角区域图像分段报警";
CM_ SG_ 1617 PDC_FLSSectorWarning "前左侧区域图像分段报警";
CM_ SG_ 1617 PDC_FLMSectorWarning "前左中区域图像分段报警";
CM_ SG_ 1617 PDC_FLCSectorWarning "前左角区域图像分段报警";
CM_ SG_ 1616 SensorRRS_RawDis_1 "传感器RRS（A发B收）的原始距离";
CM_ SG_ 1616 SensorRRM_RawDis_1 "传感器RRM（A发B收）的原始距离";
CM_ SG_ 1616 SensorRRC_RawDis_1 "传感器RRC（A发B收）的原始距离";
CM_ SG_ 1616 SensorRLS_RawDis_1 "传感器RLS（A发B收）的原始距离";
CM_ SG_ 1616 SensorRLM_RawDis_1 "传感器RLM（A发B收）的原始距离";
CM_ SG_ 1616 SensorRLC_RawDis_1 "传感器RLC（A发B收）的原始距离";
CM_ SG_ 1616 SensorFRM_RawDis_1 "传感器FRM（A发B收）的原始距离";
CM_ SG_ 1616 SensorFRC_RawDis_1 "传感器FRC（A发B收）的原始距离";
CM_ SG_ 1616 SensorFLS_RawDis_1 "传感器FLS（A发B收）的原始距离";
CM_ SG_ 1616 SensorFLM_RawDis_1 "传感器FLM（A发B收）的原始距离";
CM_ SG_ 1616 SensorFLC_RawDis_1 "传感器FLC（A发B收）的原始距离";
CM_ SG_ 1616 SensorFRS_RawDis_1 "传感器FRS（A发B收）的原始距离";
CM_ SG_ 1616 SensorRRS_RawDis "传感器RRS自发自收的原始距离";
CM_ SG_ 1616 SensorRRC_RawDis "传感器RRC自发自收的原始距离";
CM_ SG_ 1616 SensorRRM_RawDis "传感器RRM自发自收的原始距离";
CM_ SG_ 1616 SensorRLM_RawDis "传感器RLM自发自收的原始距离";
CM_ SG_ 1616 SensorRLC_RawDis "传感器RLC自发自收的原始距离";
CM_ SG_ 1616 SensorRLS_RawDis "传感器RLS自发自收的原始距离";
CM_ SG_ 1616 SensorFLS_RawDis "传感器FLS自发自收的原始距离";
CM_ SG_ 1616 SensorFLC_RawDis "传感器FLC自发自收的原始距离";
CM_ SG_ 1616 SensorFLM_RawDis "传感器FLM自发自收的原始距离";
CM_ SG_ 1616 SensorFRM_RawDis "传感器FRM自发自收的原始距离";
CM_ SG_ 1616 SensorFRC_RawDis "传感器FRC自发自收的原始距离";
CM_ SG_ 1616 SensorFRS_RawDis "传感器FRS自发自收的原始距离";
CM_ SG_ 1600 VehiclePosition_Angle_Self "Vehicle position in Angle
车辆的偏航角";
CM_ SG_ 1600 VehiclePosition_Y_Self "Vehicle position in Y Coordinate
车辆的Y坐标";
CM_ SG_ 1600 VehiclePosition_X_Self "Vehicle position in X Coordinate
车辆的X坐标";
CM_ SG_ 1600 VehiclePosition_Y "Vehicle position in Y Coordinate
车辆的Y坐标";
CM_ SG_ 1600 VehiclePosition_X "Vehicle position in X Coordinate
车辆的X坐标";
CM_ SG_ 1600 VehiclePosition_speed "Vehicle position in Speed
车辆的车速";
CM_ SG_ 1600 VehiclePosition_Gear "Vehicle position in Gear
车辆的挡位";
CM_ SG_ 1600 VehiclePosition_Angle "Vehicle position in Angle
车辆的偏航角";
CM_ SG_ 1863 APAParkingSlotSelect "第几个车位";
CM_ SG_ 1863 APAParkingMode "泊车车位类型";
CM_ SG_ 1863 APAParkingLocation "泊车方位，左侧还是右侧";
CM_ SG_ 1863 APAParkingInteriorEnableSwitch "内部使用的使能开关";
CM_ SG_ 1863 APAParkingFlag "自动泊车开启标志位";
CM_ SG_ 1862 Left_ParkingSlot5_PtFY "F点Y坐标";
CM_ SG_ 1862 Left_ParkingSlot5_PtFX "F点X坐标";
CM_ SG_ 1862 Left_ParkingSlot5_PtEY "E点Y坐标";
CM_ SG_ 1862 Left_ParkingSlot5_PtEX "E点X坐标";
CM_ SG_ 1862 Left_ParkingSlot5_PtDY "D点Y坐标";
CM_ SG_ 1862 Left_ParkingSlot5_PtDX "D点X坐标";
CM_ SG_ 1862 Left_ParkingSlot5_PtCY "C点Y坐标";
CM_ SG_ 1862 Left_ParkingSlot5_PtCX "C点X坐标";
CM_ SG_ 1862 Left_ParkingSlot5_PtBY "B点Y坐标";
CM_ SG_ 1862 Left_ParkingSlot5_PtBX "B点X坐标";
CM_ SG_ 1862 Left_ParkingSlot5_PtAY "A点Y坐标";
CM_ SG_ 1862 Left_ParkingSlot5_PtAX "A点X坐标";
CM_ SG_ 1862 Left_ParkingSlot5_Depth "The depth of the parking slot
车位的深度";
CM_ SG_ 1862 Left_ParkingSlot5_Length "The length of the parking slot
车位的长度";
CM_ SG_ 1862 LeftParkingSlot5_HeightProperty "车位高低属性";
CM_ SG_ 1862 Left_ParkingSlot5_Type "Parking slot type
车位类型";
CM_ SG_ 1862 Left_ParkingSlot5_ID "Parking slot ID
车位ID号";
CM_ SG_ 1862 Left_ParkingSlot4_PtFY "F点Y坐标";
CM_ SG_ 1862 Left_ParkingSlot4_PtFX "F点X坐标";
CM_ SG_ 1862 Left_ParkingSlot4_PtEY "E点Y坐标";
CM_ SG_ 1862 Left_ParkingSlot4_PtEX "E点X坐标";
CM_ SG_ 1862 Left_ParkingSlot4_PtDY "D点Y坐标";
CM_ SG_ 1862 Left_ParkingSlot4_PtDX "D点X坐标";
CM_ SG_ 1862 Left_ParkingSlot4_PtCY "C点Y坐标";
CM_ SG_ 1721 Left_ParkingSlot4_PtCX "C点X坐标";
CM_ SG_ 1721 Left_ParkingSlot4_PtBY "B点Y坐标";
CM_ SG_ 1721 Left_ParkingSlot4_PtBX "B点X坐标";
CM_ SG_ 1721 Left_ParkingSlot4_PtAY "A点Y坐标";
CM_ SG_ 1721 Left_ParkingSlot4_PtAX "A点X坐标";
CM_ SG_ 1721 Left_ParkingSlot4_Depth "The depth of the parking slot
车位的深度";
CM_ SG_ 1721 Left_ParkingSlot4_Length "The length of the parking slot
车位的长度";
CM_ SG_ 1721 LeftParkingSlot4_HeightProperty "车位高低属性";
CM_ SG_ 1721 Left_ParkingSlot4_Type "Parking slot type
车位类型";
CM_ SG_ 1721 Left_ParkingSlot4_ID "Parking slot ID
车位ID号";
CM_ SG_ 1721 Left_ParkingSlot3_PtFY "F点Y坐标";
CM_ SG_ 1721 Left_ParkingSlot3_PtFX "F点X坐标";
CM_ SG_ 1721 Left_ParkingSlot3_PtEY "E点Y坐标";
CM_ SG_ 1721 Left_ParkingSlot3_PtEX "E点X坐标";
CM_ SG_ 1721 Left_ParkingSlot3_PtDY "D点Y坐标";
CM_ SG_ 1721 Left_ParkingSlot3_PtDX "D点X坐标";
CM_ SG_ 1721 Left_ParkingSlot3_PtCY "C点Y坐标";
CM_ SG_ 1721 Left_ParkingSlot3_PtCX "C点X坐标";
CM_ SG_ 1721 Left_ParkingSlot3_PtBY "B点Y坐标";
CM_ SG_ 1721 Left_ParkingSlot3_PtBX "B点X坐标";
CM_ SG_ 1721 Left_ParkingSlot3_PtAY "A点Y坐标";
CM_ SG_ 1721 Left_ParkingSlot3_PtAX "A点X坐标";
CM_ SG_ 1721 Left_ParkingSlot3_Depth "The depth of the parking slot
车位的深度";
CM_ SG_ 1721 Left_ParkingSlot3_Length "The length of the parking slot
车位的长度";
CM_ SG_ 1721 LeftParkingSlot3_HeightProperty "车位高低属性";
CM_ SG_ 1721 Left_ParkingSlot3_Type "Parking slot type
车位类型";
CM_ SG_ 1721 Left_ParkingSlot3_ID "Parking slot ID
车位ID号";
CM_ SG_ 1721 Left_ParkingSlot2_PtFY "F点Y坐标";
CM_ SG_ 1721 Left_ParkingSlot2_PtFX "F点X坐标";
CM_ SG_ 1721 Left_ParkingSlot2_PtEY "E点Y坐标";
CM_ SG_ 1720 Left_ParkingSlot2_PtEX "E点X坐标";
CM_ SG_ 1720 Left_ParkingSlot2_PtDY "D点Y坐标";
CM_ SG_ 1720 Left_ParkingSlot2_PtDX "D点X坐标";
CM_ SG_ 1720 Left_ParkingSlot2_PtCY "C点Y坐标";
CM_ SG_ 1720 Left_ParkingSlot2_PtCX "C点X坐标";
CM_ SG_ 1720 Left_ParkingSlot2_PtBY "B点Y坐标";
CM_ SG_ 1720 Left_ParkingSlot2_PtBX "B点X坐标";
CM_ SG_ 1720 Left_ParkingSlot2_PtAY "A点Y坐标";
CM_ SG_ 1720 Left_ParkingSlot2_PtAX "A点X坐标";
CM_ SG_ 1720 Left_ParkingSlot2_Depth "The depth of the parking slot
车位的深度";
CM_ SG_ 1720 Left_ParkingSlot2_Length "The length of the parking slot
车位的长度";
CM_ SG_ 1720 LeftParkingSlot2_HeightProperty "车位高低属性";
CM_ SG_ 1720 Left_ParkingSlot2_Type "Parking slot type
车位类型";
CM_ SG_ 1720 Left_ParkingSlot2_ID "Parking slot ID
车位ID号";
CM_ SG_ 1720 Left_ParkingSlot1_PtFY "F点Y坐标";
CM_ SG_ 1720 Left_ParkingSlot1_PtFX "F点X坐标";
CM_ SG_ 1720 Left_ParkingSlot1_PtEY "E点Y坐标";
CM_ SG_ 1720 Left_ParkingSlot1_PtEX "E点X坐标";
CM_ SG_ 1720 Left_ParkingSlot1_PtDY "D点Y坐标";
CM_ SG_ 1720 Left_ParkingSlot1_PtDX "D点X坐标";
CM_ SG_ 1720 Left_ParkingSlot1_PtCY "C点Y坐标";
CM_ SG_ 1720 Left_ParkingSlot1_PtCX "C点X坐标";
CM_ SG_ 1720 Left_ParkingSlot1_PtBY "B点Y坐标";
CM_ SG_ 1720 Left_ParkingSlot1_PtBX "B点X坐标";
CM_ SG_ 1720 Left_ParkingSlot1_PtAY "A点Y坐标";
CM_ SG_ 1720 Left_ParkingSlot1_PtAX "A点X坐标";
CM_ SG_ 1720 Left_ParkingSlot1_Depth "The depth of the parking slot
车位的深度";
CM_ SG_ 1720 Left_ParkingSlot1_Length "The length of the parking slot
车位的长度";
CM_ SG_ 1720 LeftParkingSlot1_HeightProperty "车位高低属性";
CM_ SG_ 1720 Left_ParkingSlot1_Type "Parking slot type
车位类型";
CM_ SG_ 1720 Left_ParkingSlot1_ID "Parking slot ID
车位ID号";
CM_ SG_ 1859 Right_ParkingSlot5_PtFY "F点Y坐标";
CM_ SG_ 1859 Right_ParkingSlot5_PtFX "F点X坐标";
CM_ SG_ 1859 Right_ParkingSlot5_PtEY "E点Y坐标";
CM_ SG_ 1859 Right_ParkingSlot5_PtEX "E点X坐标";
CM_ SG_ 1859 Right_ParkingSlot5_PtDY "D点Y坐标";
CM_ SG_ 1859 Right_ParkingSlot5_PtDX "D点X坐标";
CM_ SG_ 1859 Right_ParkingSlot5_PtCY "C点Y坐标";
CM_ SG_ 1859 Right_ParkingSlot5_PtCX "C点X坐标";
CM_ SG_ 1859 Right_ParkingSlot5_PtBY "B点Y坐标";
CM_ SG_ 1859 Right_ParkingSlot5_PtBX "B点X坐标";
CM_ SG_ 1859 Right_ParkingSlot5_PtAY "A点Y坐标";
CM_ SG_ 1859 Right_ParkingSlot5_PtAX "A点X坐标";
CM_ SG_ 1859 Right_ParkingSlot5_Depth "The depth of the parking slot
车位的深度";
CM_ SG_ 1859 Right_ParkingSlot5_Length "The length of the parking slot
车位的长度";
CM_ SG_ 1859 RightParkingSlot5_HeightProperty "车位高低属性";
CM_ SG_ 1859 Right_ParkingSlot5_Type "Parking slot type
车位类型";
CM_ SG_ 1859 Right_ParkingSlot5_ID "Parking slot ID
车位ID号";
CM_ SG_ 1859 Right_ParkingSlot4_PtFY "F点Y坐标";
CM_ SG_ 1859 Right_ParkingSlot4_PtFX "F点X坐标";
CM_ SG_ 1859 Right_ParkingSlot4_PtEY "E点Y坐标";
CM_ SG_ 1859 Right_ParkingSlot4_PtEX "E点X坐标";
CM_ SG_ 1859 Right_ParkingSlot4_PtDY "D点Y坐标";
CM_ SG_ 1859 Right_ParkingSlot4_PtDX "D点X坐标";
CM_ SG_ 1859 Right_ParkingSlot4_PtCY "C点Y坐标";
CM_ SG_ 1719 Right_ParkingSlot4_PtCX "C点X坐标";
CM_ SG_ 1719 Right_ParkingSlot4_PtBY "B点Y坐标";
CM_ SG_ 1719 Right_ParkingSlot4_PtBX "B点X坐标";
CM_ SG_ 1719 Right_ParkingSlot4_PtAY "A点Y坐标";
CM_ SG_ 1719 Right_ParkingSlot4_PtAX "A点X坐标";
CM_ SG_ 1719 Right_ParkingSlot4_Depth "The depth of the parking slot
车位的深度";
CM_ SG_ 1719 Right_ParkingSlot4_Length "The length of the parking slot
车位的长度";
CM_ SG_ 1719 RightParkingSlot4_HeightProperty "车位高低属性";
CM_ SG_ 1719 Right_ParkingSlot4_Type "Parking slot type
车位类型";
CM_ SG_ 1719 Right_ParkingSlot4_ID "Parking slot ID
车位ID号";
CM_ SG_ 1719 Right_ParkingSlot3_PtFY "F点Y坐标";
CM_ SG_ 1719 Right_ParkingSlot3_PtFX "F点X坐标";
CM_ SG_ 1719 Right_ParkingSlot3_PtEY "E点Y坐标";
CM_ SG_ 1719 Right_ParkingSlot3_PtEX "E点X坐标";
CM_ SG_ 1719 Right_ParkingSlot3_PtDY "D点Y坐标";
CM_ SG_ 1719 Right_ParkingSlot3_PtDX "D点X坐标";
CM_ SG_ 1719 Right_ParkingSlot3_PtCY "C点Y坐标";
CM_ SG_ 1719 Right_ParkingSlot3_PtCX "C点X坐标";
CM_ SG_ 1719 Right_ParkingSlot3_PtBY "B点Y坐标";
CM_ SG_ 1719 Right_ParkingSlot3_PtBX "B点X坐标";
CM_ SG_ 1719 Right_ParkingSlot3_PtAY "A点Y坐标";
CM_ SG_ 1719 Right_ParkingSlot3_PtAX "A点X坐标";
CM_ SG_ 1719 Right_ParkingSlot3_Depth "The depth of the parking slot
车位的深度";
CM_ SG_ 1719 Right_ParkingSlot3_Length "The length of the parking slot
车位的长度";
CM_ SG_ 1719 RightParkingSlot3_HeightProperty "车位高低属性";
CM_ SG_ 1719 Right_ParkingSlot3_Type "Parking slot type
车位类型";
CM_ SG_ 1719 Right_ParkingSlot3_ID "Parking slot ID
车位ID号";
CM_ SG_ 1719 Right_ParkingSlot2_PtFY "F点Y坐标";
CM_ SG_ 1719 Right_ParkingSlot2_PtFX "F点X坐标";
CM_ SG_ 1719 Right_ParkingSlot2_PtEY "E点Y坐标";
CM_ SG_ 1718 Right_ParkingSlot2_PtEX "E点X坐标";
CM_ SG_ 1718 Right_ParkingSlot2_PtDY "D点Y坐标";
CM_ SG_ 1718 Right_ParkingSlot2_PtDX "D点X坐标";
CM_ SG_ 1718 Right_ParkingSlot2_PtCY "C点Y坐标";
CM_ SG_ 1718 Right_ParkingSlot2_PtCX "C点X坐标";
CM_ SG_ 1718 Right_ParkingSlot2_PtBY "B点Y坐标";
CM_ SG_ 1718 Right_ParkingSlot2_PtBX "B点X坐标";
CM_ SG_ 1718 Right_ParkingSlot2_PtAY "A点Y坐标";
CM_ SG_ 1718 Right_ParkingSlot2_PtAX "A点X坐标";
CM_ SG_ 1718 Right_ParkingSlot2_Depth "The depth of the parking slot
车位的深度";
CM_ SG_ 1718 Right_ParkingSlot2_Length "The length of the parking slot
车位的长度";
CM_ SG_ 1718 RightParkingSlot2_HeightProperty "车位高低属性";
CM_ SG_ 1718 Right_ParkingSlot2_Type "Parking slot type
车位类型";
CM_ SG_ 1718 Right_ParkingSlot2_ID "Parking slot ID
车位ID号";
CM_ SG_ 1718 Right_ParkingSlot1_PtFY "F点Y坐标";
CM_ SG_ 1718 Right_ParkingSlot1_PtFX "F点X坐标";
CM_ SG_ 1718 Right_ParkingSlot1_PtEY "E点Y坐标";
CM_ SG_ 1718 Right_ParkingSlot1_PtEX "E点X坐标";
CM_ SG_ 1718 Right_ParkingSlot1_PtDY "D点Y坐标";
CM_ SG_ 1718 Right_ParkingSlot1_PtDX "D点X坐标";
CM_ SG_ 1718 Right_ParkingSlot1_PtCY "C点Y坐标";
CM_ SG_ 1718 Right_ParkingSlot1_PtCX "C点X坐标";
CM_ SG_ 1718 Right_ParkingSlot1_PtBY "B点Y坐标";
CM_ SG_ 1718 Right_ParkingSlot1_PtBX "B点X坐标";
CM_ SG_ 1718 Right_ParkingSlot1_PtAY "A点Y坐标";
CM_ SG_ 1718 Right_ParkingSlot1_PtAX "A点X坐标";
CM_ SG_ 1718 Right_ParkingSlot1_Depth "The depth of the parking slot
车位的深度";
CM_ SG_ 1718 Right_ParkingSlot1_Length "The length of the parking slot
车位的长度";
CM_ SG_ 1718 RightParkingSlot1_HeightProperty "车位高低属性";
CM_ SG_ 1718 Right_ParkingSlot1_Type "Parking slot type
车位类型";
CM_ SG_ 1718 Right_ParkingSlot1_ID "Parking slot ID
车位ID号";
CM_ SG_ 1622 Point_119_ExistProbability "点的存在概率";
CM_ SG_ 1622 Point_119_AttributeProbability "点的高低属性概率";
CM_ SG_ 1622 Point_118_ExistProbability "点的存在概率";
CM_ SG_ 1622 Point_118_AttributeProbability "点的高低属性概率";
CM_ SG_ 1622 Point_117_ExistProbability "点的存在概率";
CM_ SG_ 1622 Point_117_AttributeProbability "点的高低属性概率";
CM_ SG_ 1622 Point_116_ExistProbability "点的存在概率";
CM_ SG_ 1622 Point_116_AttributeProbability "点的高低属性概率";
CM_ SG_ 1622 Point_115_ExistProbability "点的存在概率";
CM_ SG_ 1622 Point_115_AttributeProbability "点的高低属性概率";
CM_ SG_ 1622 Point_114_ExistProbability "点的存在概率";
CM_ SG_ 1622 Point_114_AttributeProbability "点的高低属性概率";
CM_ SG_ 1622 Point_113_ExistProbability "点的存在概率";
CM_ SG_ 1622 Point_113_AttributeProbability "点的高低属性概率";
CM_ SG_ 1622 Point_112_ExistProbability "点的存在概率";
CM_ SG_ 1622 Point_112_AttributeProbability "点的高低属性概率";
CM_ SG_ 1622 Point_111_ExistProbability "点的存在概率";
CM_ SG_ 1622 Point_111_AttributeProbability "点的高低属性概率";
CM_ SG_ 1622 Point_110_ExistProbability "点的存在概率";
CM_ SG_ 1622 Point_110_AttributeProbability "点的高低属性概率";
CM_ SG_ 1622 Point_109_ExistProbability "点的存在概率";
CM_ SG_ 1622 Point_109_AttributeProbability "点的高低属性概率";
CM_ SG_ 1622 Point_108_ExistProbability "点的存在概率";
CM_ SG_ 1622 Point_108_AttributeProbability "点的高低属性概率";
CM_ SG_ 1624 Point_107_ExistProbability "点的存在概率";
CM_ SG_ 1624 Point_107_AttributeProbability "点的高低属性概率";
CM_ SG_ 1624 Point_106_ExistProbability "点的存在概率";
CM_ SG_ 1624 Point_106_AttributeProbability "点的高低属性概率";
CM_ SG_ 1624 Point_105_ExistProbability "点的存在概率";
CM_ SG_ 1624 Point_105_AttributeProbability "点的高低属性概率";
CM_ SG_ 1624 Point_104_ExistProbability "点的存在概率";
CM_ SG_ 1624 Point_104_AttributeProbability "点的高低属性概率";
CM_ SG_ 1624 Point_103_ExistProbability "点的存在概率";
CM_ SG_ 1624 Point_103_AttributeProbability "点的高低属性概率";
CM_ SG_ 1624 Point_102_ExistProbability "点的存在概率";
CM_ SG_ 1624 Point_102_AttributeProbability "点的高低属性概率";
CM_ SG_ 1624 Point_101_ExistProbability "点的存在概率";
CM_ SG_ 1624 Point_101_AttributeProbability "点的高低属性概率";
CM_ SG_ 1624 Point_100_ExistProbability "点的存在概率";
CM_ SG_ 1624 Point_100_AttributeProbability "点的高低属性概率";
CM_ SG_ 1624 Point_99_ExistProbability "点的存在概率";
CM_ SG_ 1624 Point_99_AttributeProbability "点的高低属性概率";
CM_ SG_ 1624 Point_98_ExistProbability "点的存在概率";
CM_ SG_ 1624 Point_98_AttributeProbability "点的高低属性概率";
CM_ SG_ 1624 Point_97_ExistProbability "点的存在概率";
CM_ SG_ 1624 Point_97_AttributeProbability "点的高低属性概率";
CM_ SG_ 1624 Point_96_ExistProbability "点的存在概率";
CM_ SG_ 1624 Point_96_AttributeProbability "点的高低属性概率";
CM_ SG_ 1624 Point_95_ExistProbability "点的存在概率";
CM_ SG_ 1624 Point_95_AttributeProbability "点的高低属性概率";
CM_ SG_ 1624 Point_94_ExistProbability "点的存在概率";
CM_ SG_ 1624 Point_94_AttributeProbability "点的高低属性概率";
CM_ SG_ 1624 Point_93_ExistProbability "点的存在概率";
CM_ SG_ 1624 Point_93_AttributeProbability "点的高低属性概率";
CM_ SG_ 1624 Point_92_ExistProbability "点的存在概率";
CM_ SG_ 1624 Point_92_AttributeProbability "点的高低属性概率";
CM_ SG_ 1624 Point_91_ExistProbability "点的存在概率";
CM_ SG_ 1624 Point_91_AttributeProbability "点的高低属性概率";
CM_ SG_ 1624 Point_90_ExistProbability "点的存在概率";
CM_ SG_ 1624 Point_90_AttributeProbability "点的高低属性概率";
CM_ SG_ 1624 Point_89_ExistProbability "点的存在概率";
CM_ SG_ 1624 Point_89_AttributeProbability "点的高低属性概率";
CM_ SG_ 1624 Point_88_ExistProbability "点的存在概率";
CM_ SG_ 1624 Point_88_AttributeProbability "点的高低属性概率";
CM_ SG_ 1624 Point_87_ExistProbability "点的存在概率";
CM_ SG_ 1624 Point_87_AttributeProbability "点的高低属性概率";
CM_ SG_ 1624 Point_86_ExistProbability "点的存在概率";
CM_ SG_ 1624 Point_86_AttributeProbability "点的高低属性概率";
CM_ SG_ 1624 Point_85_ExistProbability "点的存在概率";
CM_ SG_ 1624 Point_85_AttributeProbability "点的高低属性概率";
CM_ SG_ 1624 Point_84_ExistProbability "点的存在概率";
CM_ SG_ 1624 Point_84_AttributeProbability "点的高低属性概率";
CM_ SG_ 1624 Point_83_ExistProbability "点的存在概率";
CM_ SG_ 1624 Point_83_AttributeProbability "点的高低属性概率";
CM_ SG_ 1624 Point_82_ExistProbability "点的存在概率";
CM_ SG_ 1624 Point_82_AttributeProbability "点的高低属性概率";
CM_ SG_ 1624 Point_81_ExistProbability "点的存在概率";
CM_ SG_ 1624 Point_81_AttributeProbability "点的高低属性概率";
CM_ SG_ 1624 Point_80_ExistProbability "点的存在概率";
CM_ SG_ 1624 Point_80_AttributeProbability "点的高低属性概率";
CM_ SG_ 1624 Point_79_ExistProbability "点的存在概率";
CM_ SG_ 1624 Point_79_AttributeProbability "点的高低属性概率";
CM_ SG_ 1624 Point_78_ExistProbability "点的存在概率";
CM_ SG_ 1624 Point_78_AttributeProbability "点的高低属性概率";
CM_ SG_ 1624 Point_77_ExistProbability "点的存在概率";
CM_ SG_ 1624 Point_77_AttributeProbability "点的高低属性概率";
CM_ SG_ 1624 Point_76_ExistProbability "点的存在概率";
CM_ SG_ 1624 Point_76_AttributeProbability "点的高低属性概率";
CM_ SG_ 1624 Point_75_ExistProbability "点的存在概率";
CM_ SG_ 1624 Point_75_AttributeProbability "点的高低属性概率";
CM_ SG_ 1624 Point_74_ExistProbability "点的存在概率";
CM_ SG_ 1624 Point_74_AttributeProbability "点的高低属性概率";
CM_ SG_ 1624 Point_73_ExistProbability "点的存在概率";
CM_ SG_ 1624 Point_73_AttributeProbability "点的高低属性概率";
CM_ SG_ 1624 Point_72_ExistProbability "点的存在概率";
CM_ SG_ 1624 Point_72_AttributeProbability "点的高低属性概率";
CM_ SG_ 1623 Point_71_ExistProbability "点的存在概率";
CM_ SG_ 1623 Point_71_AttributeProbability "点的高低属性概率";
CM_ SG_ 1623 Point_70_ExistProbability "点的存在概率";
CM_ SG_ 1623 Point_70_AttributeProbability "点的高低属性概率";
CM_ SG_ 1623 Point_69_ExistProbability "点的存在概率";
CM_ SG_ 1623 Point_69_AttributeProbability "点的高低属性概率";
CM_ SG_ 1623 Point_68_ExistProbability "点的存在概率";
CM_ SG_ 1623 Point_68_AttributeProbability "点的高低属性概率";
CM_ SG_ 1623 Point_67_ExistProbability "点的存在概率";
CM_ SG_ 1623 Point_67_AttributeProbability "点的高低属性概率";
CM_ SG_ 1623 Point_66_ExistProbability "点的存在概率";
CM_ SG_ 1623 Point_66_AttributeProbability "点的高低属性概率";
CM_ SG_ 1623 Point_65_ExistProbability "点的存在概率";
CM_ SG_ 1623 Point_65_AttributeProbability "点的高低属性概率";
CM_ SG_ 1623 Point_64_ExistProbability "点的存在概率";
CM_ SG_ 1623 Point_64_AttributeProbability "点的高低属性概率";
CM_ SG_ 1623 Point_63_ExistProbability "点的存在概率";
CM_ SG_ 1623 Point_63_AttributeProbability "点的高低属性概率";
CM_ SG_ 1623 Point_62_ExistProbability "点的存在概率";
CM_ SG_ 1623 Point_62_AttributeProbability "点的高低属性概率";
CM_ SG_ 1623 Point_61_ExistProbability "点的存在概率";
CM_ SG_ 1623 Point_61_AttributeProbability "点的高低属性概率";
CM_ SG_ 1623 Point_60_ExistProbability "点的存在概率";
CM_ SG_ 1623 Point_60_AttributeProbability "点的高低属性概率";
CM_ SG_ 1623 Point_59_ExistProbability "点的存在概率";
CM_ SG_ 1623 Point_59_AttributeProbability "点的高低属性概率";
CM_ SG_ 1623 Point_58_ExistProbability "点的存在概率";
CM_ SG_ 1623 Point_58_AttributeProbability "点的高低属性概率";
CM_ SG_ 1623 Point_57_ExistProbability "点的存在概率";
CM_ SG_ 1623 Point_57_AttributeProbability "点的高低属性概率";
CM_ SG_ 1623 Point_56_ExistProbability "点的存在概率";
CM_ SG_ 1623 Point_56_AttributeProbability "点的高低属性概率";
CM_ SG_ 1623 Point_55_ExistProbability "点的存在概率";
CM_ SG_ 1623 Point_55_AttributeProbability "点的高低属性概率";
CM_ SG_ 1623 Point_54_ExistProbability "点的存在概率";
CM_ SG_ 1623 Point_54_AttributeProbability "点的高低属性概率";
CM_ SG_ 1623 Point_53_ExistProbability "点的存在概率";
CM_ SG_ 1623 Point_53_AttributeProbability "点的高低属性概率";
CM_ SG_ 1623 Point_52_ExistProbability "点的存在概率";
CM_ SG_ 1623 Point_52_AttributeProbability "点的高低属性概率";
CM_ SG_ 1623 Point_51_ExistProbability "点的存在概率";
CM_ SG_ 1623 Point_51_AttributeProbability "点的高低属性概率";
CM_ SG_ 1623 Point_50_ExistProbability "点的存在概率";
CM_ SG_ 1623 Point_50_AttributeProbability "点的高低属性概率";
CM_ SG_ 1623 Point_49_ExistProbability "点的存在概率";
CM_ SG_ 1623 Point_49_AttributeProbability "点的高低属性概率";
CM_ SG_ 1623 Point_48_ExistProbability "点的存在概率";
CM_ SG_ 1623 Point_48_AttributeProbability "点的高低属性概率";
CM_ SG_ 1623 Point_47_ExistProbability "点的存在概率";
CM_ SG_ 1623 Point_47_AttributeProbability "点的高低属性概率";
CM_ SG_ 1623 Point_46_ExistProbability "点的存在概率";
CM_ SG_ 1623 Point_46_AttributeProbability "点的高低属性概率";
CM_ SG_ 1623 Point_45_ExistProbability "点的存在概率";
CM_ SG_ 1623 Point_45_AttributeProbability "点的高低属性概率";
CM_ SG_ 1623 Point_44_ExistProbability "点的存在概率";
CM_ SG_ 1623 Point_44_AttributeProbability "点的高低属性概率";
CM_ SG_ 1623 Point_43_ExistProbability "点的存在概率";
CM_ SG_ 1623 Point_43_AttributeProbability "点的高低属性概率";
CM_ SG_ 1623 Point_42_ExistProbability "点的存在概率";
CM_ SG_ 1623 Point_42_AttributeProbability "点的高低属性概率";
CM_ SG_ 1623 Point_41_ExistProbability "点的存在概率";
CM_ SG_ 1623 Point_41_AttributeProbability "点的高低属性概率";
CM_ SG_ 1623 Point_40_ExistProbability "点的存在概率";
CM_ SG_ 1623 Point_40_AttributeProbability "点的高低属性概率";
CM_ SG_ 1623 Point_39_ExistProbability "点的存在概率";
CM_ SG_ 1623 Point_39_AttributeProbability "点的高低属性概率";
CM_ SG_ 1623 Point_38_ExistProbability "点的存在概率";
CM_ SG_ 1623 Point_38_AttributeProbability "点的高低属性概率";
CM_ SG_ 1623 Point_37_ExistProbability "点的存在概率";
CM_ SG_ 1623 Point_37_AttributeProbability "点的高低属性概率";
CM_ SG_ 1623 Point_36_ExistProbability "点的存在概率";
CM_ SG_ 1623 Point_36_AttributeProbability "点的高低属性概率";
CM_ SG_ 1621 Point_35_ExistProbability "点的存在概率";
CM_ SG_ 1621 Point_35_AttributeProbability "点的高低属性概率";
CM_ SG_ 1621 Point_34_ExistProbability "点的存在概率";
CM_ SG_ 1621 Point_34_AttributeProbability "点的高低属性概率";
CM_ SG_ 1621 Point_33_ExistProbability "点的存在概率";
CM_ SG_ 1621 Point_33_AttributeProbability "点的高低属性概率";
CM_ SG_ 1621 Point_32_ExistProbability "点的存在概率";
CM_ SG_ 1621 Point_32_AttributeProbability "点的高低属性概率";
CM_ SG_ 1621 Point_31_ExistProbability "点的存在概率";
CM_ SG_ 1621 Point_31_AttributeProbability "点的高低属性概率";
CM_ SG_ 1621 Point_30_ExistProbability "点的存在概率";
CM_ SG_ 1621 Point_30_AttributeProbability "点的高低属性概率";
CM_ SG_ 1621 Point_29_ExistProbability "点的存在概率";
CM_ SG_ 1621 Point_29_AttributeProbability "点的高低属性概率";
CM_ SG_ 1621 Point_28_ExistProbability "点的存在概率";
CM_ SG_ 1621 Point_28_AttributeProbability "点的高低属性概率";
CM_ SG_ 1621 Point_27_ExistProbability "点的存在概率";
CM_ SG_ 1621 Point_27_AttributeProbability "点的高低属性概率";
CM_ SG_ 1621 Point_26_ExistProbability "点的存在概率";
CM_ SG_ 1621 Point_26_AttributeProbability "点的高低属性概率";
CM_ SG_ 1621 Point_25_ExistProbability "点的存在概率";
CM_ SG_ 1621 Point_25_AttributeProbability "点的高低属性概率";
CM_ SG_ 1621 Point_24_ExistProbability "点的存在概率";
CM_ SG_ 1621 Point_24_AttributeProbability "点的高低属性概率";
CM_ SG_ 1621 Point_23_ExistProbability "点的存在概率";
CM_ SG_ 1621 Point_23_AttributeProbability "点的高低属性概率";
CM_ SG_ 1621 Point_22_ExistProbability "点的存在概率";
CM_ SG_ 1621 Point_22_AttributeProbability "点的高低属性概率";
CM_ SG_ 1621 Point_21_ExistProbability "点的存在概率";
CM_ SG_ 1621 Point_21_AttributeProbability "点的高低属性概率";
CM_ SG_ 1621 Point_20_ExistProbability "点的存在概率";
CM_ SG_ 1621 Point_20_AttributeProbability "点的高低属性概率";
CM_ SG_ 1621 Point_19_ExistProbability "点的存在概率";
CM_ SG_ 1621 Point_19_AttributeProbability "点的高低属性概率";
CM_ SG_ 1621 Point_18_ExistProbability "点的存在概率";
CM_ SG_ 1621 Point_18_AttributeProbability "点的高低属性概率";
CM_ SG_ 1621 Point_17_ExistProbability "点的存在概率";
CM_ SG_ 1621 Point_17_AttributeProbability "点的高低属性概率";
CM_ SG_ 1621 Point_16_ExistProbability "点的存在概率";
CM_ SG_ 1621 Point_16_AttributeProbability "点的高低属性概率";
CM_ SG_ 1621 Point_15_ExistProbability "点的存在概率";
CM_ SG_ 1621 Point_15_AttributeProbability "点的高低属性概率";
CM_ SG_ 1621 Point_14_ExistProbability "点的存在概率";
CM_ SG_ 1621 Point_14_AttributeProbability "点的高低属性概率";
CM_ SG_ 1621 Point_13_ExistProbability "点的存在概率";
CM_ SG_ 1621 Point_13_AttributeProbability "点的高低属性概率";
CM_ SG_ 1621 Point_12_ExistProbability "点的存在概率";
CM_ SG_ 1621 Point_12_AttributeProbability "点的高低属性概率";
CM_ SG_ 1621 Point_11_ExistProbability "点的存在概率";
CM_ SG_ 1621 Point_11_AttributeProbability "点的高低属性概率";
CM_ SG_ 1621 Point_10_ExistProbability "点的存在概率";
CM_ SG_ 1621 Point_10_AttributeProbability "点的高低属性概率";
CM_ SG_ 1621 Point_09_ExistProbability "点的存在概率";
CM_ SG_ 1621 Point_09_AttributeProbability "点的高低属性概率";
CM_ SG_ 1621 Point_08_ExistProbability "点的存在概率";
CM_ SG_ 1621 Point_08_AttributeProbability "点的高低属性概率";
CM_ SG_ 1621 Point_07_ExistProbability "点的存在概率";
CM_ SG_ 1621 Point_07_AttributeProbability "点的高低属性概率";
CM_ SG_ 1621 Point_06_ExistProbability "点的存在概率";
CM_ SG_ 1621 Point_06_AttributeProbability "点的高低属性概率";
CM_ SG_ 1621 Point_05_ExistProbability "点的存在概率";
CM_ SG_ 1621 Point_05_AttributeProbability "点的高低属性概率";
CM_ SG_ 1621 Point_04_ExistProbability "点的存在概率";
CM_ SG_ 1621 Point_04_AttributeProbability "点的高低属性概率";
CM_ SG_ 1621 Point_03_ExistProbability "点的存在概率";
CM_ SG_ 1621 Point_03_AttributeProbability "点的高低属性概率";
CM_ SG_ 1621 Point_02_ExistProbability "点的存在概率";
CM_ SG_ 1621 Point_02_AttributeProbability "点的高低属性概率";
CM_ SG_ 1621 Point_01_ExistProbability "点的存在概率";
CM_ SG_ 1621 Point_01_AttributeProbability "点的高低属性概率";
CM_ SG_ 1621 Point_00_ExistProbability "点的存在概率";
CM_ SG_ 1621 Point_00_AttributeProbability "点的高低属性概率";
CM_ SG_ 1620 Point_119_Y "点的Y坐标";
CM_ SG_ 1620 Point_119_X "点的X坐标";
CM_ SG_ 1620 Point_119_ID "点的ID";
CM_ SG_ 1620 Point_119_Attribute "点的高低";
CM_ SG_ 1620 Point_118_Y "点的Y坐标";
CM_ SG_ 1620 Point_118_X "点的X坐标";
CM_ SG_ 1620 Point_118_ID "点的ID";
CM_ SG_ 1620 Point_118_Attribute "点的高低";
CM_ SG_ 1620 Point_117_Y "点的Y坐标";
CM_ SG_ 1620 Point_117_X "点的X坐标";
CM_ SG_ 1620 Point_117_ID "点的ID";
CM_ SG_ 1620 Point_117_Attribute "点的高低";
CM_ SG_ 1620 Point_116_Y "点的Y坐标";
CM_ SG_ 1620 Point_116_X "点的X坐标";
CM_ SG_ 1620 Point_116_ID "点的ID";
CM_ SG_ 1620 Point_116_Attribute "点的高低";
CM_ SG_ 1620 Point_115_Y "点的Y坐标";
CM_ SG_ 1620 Point_115_X "点的X坐标";
CM_ SG_ 1620 Point_115_ID "点的ID";
CM_ SG_ 1620 Point_115_Attribute "点的高低";
CM_ SG_ 1620 Point_114_Y "点的Y坐标";
CM_ SG_ 1620 Point_114_X "点的X坐标";
CM_ SG_ 1620 Point_114_ID "点的ID";
CM_ SG_ 1620 Point_114_Attribute "点的高低";
CM_ SG_ 1620 Point_113_Y "点的Y坐标";
CM_ SG_ 1620 Point_113_X "点的X坐标";
CM_ SG_ 1620 Point_113_ID "点的ID";
CM_ SG_ 1620 Point_113_Attribute "点的高低";
CM_ SG_ 1620 Point_112_Y "点的Y坐标";
CM_ SG_ 1620 Point_112_X "点的X坐标";
CM_ SG_ 1620 Point_112_ID "点的ID";
CM_ SG_ 1620 Point_112_Attribute "点的高低";
CM_ SG_ 1620 Point_111_Y "点的Y坐标";
CM_ SG_ 1620 Point_111_X "点的X坐标";
CM_ SG_ 1620 Point_111_ID "点的ID";
CM_ SG_ 1620 Point_111_Attribute "点的高低";
CM_ SG_ 1620 Point_110_Y "点的Y坐标";
CM_ SG_ 1620 Point_110_X "点的X坐标";
CM_ SG_ 1620 Point_110_ID "点的ID";
CM_ SG_ 1620 Point_110_Attribute "点的高低";
CM_ SG_ 1619 Point_109_Y "点的Y坐标";
CM_ SG_ 1619 Point_109_X "点的X坐标";
CM_ SG_ 1619 Point_109_ID "点的ID";
CM_ SG_ 1619 Point_109_Attribute "点的高低";
CM_ SG_ 1619 Point_108_Y "点的Y坐标";
CM_ SG_ 1619 Point_108_X "点的X坐标";
CM_ SG_ 1619 Point_108_ID "点的ID";
CM_ SG_ 1619 Point_108_Attribute "点的高低";
CM_ SG_ 1619 Point_107_Y "点的Y坐标";
CM_ SG_ 1619 Point_107_X "点的X坐标";
CM_ SG_ 1619 Point_107_ID "点的ID";
CM_ SG_ 1619 Point_107_Attribute "点的高低";
CM_ SG_ 1619 Point_106_Y "点的Y坐标";
CM_ SG_ 1619 Point_106_X "点的X坐标";
CM_ SG_ 1619 Point_106_ID "点的ID";
CM_ SG_ 1619 Point_106_Attribute "点的高低";
CM_ SG_ 1619 Point_105_Y "点的Y坐标";
CM_ SG_ 1619 Point_105_X "点的X坐标";
CM_ SG_ 1619 Point_105_ID "点的ID";
CM_ SG_ 1619 Point_105_Attribute "点的高低";
CM_ SG_ 1619 Point_104_Y "点的Y坐标";
CM_ SG_ 1619 Point_104_X "点的X坐标";
CM_ SG_ 1619 Point_104_ID "点的ID";
CM_ SG_ 1619 Point_104_Attribute "点的高低";
CM_ SG_ 1619 Point_103_Y "点的Y坐标";
CM_ SG_ 1619 Point_103_X "点的X坐标";
CM_ SG_ 1619 Point_103_ID "点的ID";
CM_ SG_ 1619 Point_103_Attribute "点的高低";
CM_ SG_ 1619 Point_102_Y "点的Y坐标";
CM_ SG_ 1619 Point_102_X "点的X坐标";
CM_ SG_ 1619 Point_102_ID "点的ID";
CM_ SG_ 1619 Point_102_Attribute "点的高低";
CM_ SG_ 1619 Point_101_Y "点的Y坐标";
CM_ SG_ 1619 Point_101_X "点的X坐标";
CM_ SG_ 1619 Point_101_ID "点的ID";
CM_ SG_ 1619 Point_101_Attribute "点的高低";
CM_ SG_ 1619 Point_100_Y "点的Y坐标";
CM_ SG_ 1619 Point_100_X "点的X坐标";
CM_ SG_ 1619 Point_100_ID "点的ID";
CM_ SG_ 1619 Point_100_Attribute "点的高低";
CM_ SG_ 1618 Point_99_Y "点的Y坐标";
CM_ SG_ 1618 Point_99_X "点的X坐标";
CM_ SG_ 1618 Point_99_ID "点的ID";
CM_ SG_ 1618 Point_99_Attribute "点的高低";
CM_ SG_ 1618 Point_98_Y "点的Y坐标";
CM_ SG_ 1618 Point_98_X "点的X坐标";
CM_ SG_ 1618 Point_98_ID "点的ID";
CM_ SG_ 1618 Point_98_Attribute "点的高低";
CM_ SG_ 1618 Point_97_Y "点的Y坐标";
CM_ SG_ 1618 Point_97_X "点的X坐标";
CM_ SG_ 1618 Point_97_ID "点的ID";
CM_ SG_ 1618 Point_97_Attribute "点的高低";
CM_ SG_ 1618 Point_96_Y "点的Y坐标";
CM_ SG_ 1618 Point_96_X "点的X坐标";
CM_ SG_ 1618 Point_96_ID "点的ID";
CM_ SG_ 1618 Point_96_Attribute "点的高低";
CM_ SG_ 1618 Point_95_Y "点的Y坐标";
CM_ SG_ 1618 Point_95_X "点的X坐标";
CM_ SG_ 1618 Point_95_ID "点的ID";
CM_ SG_ 1618 Point_95_Attribute "点的高低";
CM_ SG_ 1618 Point_94_Y "点的Y坐标";
CM_ SG_ 1618 Point_94_X "点的X坐标";
CM_ SG_ 1618 Point_94_ID "点的ID";
CM_ SG_ 1618 Point_94_Attribute "点的高低";
CM_ SG_ 1618 Point_93_Y "点的Y坐标";
CM_ SG_ 1618 Point_93_X "点的X坐标";
CM_ SG_ 1618 Point_93_ID "点的ID";
CM_ SG_ 1618 Point_93_Attribute "点的高低";
CM_ SG_ 1618 Point_92_Y "点的Y坐标";
CM_ SG_ 1618 Point_92_X "点的X坐标";
CM_ SG_ 1618 Point_92_ID "点的ID";
CM_ SG_ 1618 Point_92_Attribute "点的高低";
CM_ SG_ 1618 Point_91_Y "点的Y坐标";
CM_ SG_ 1618 Point_91_X "点的X坐标";
CM_ SG_ 1618 Point_91_ID "点的ID";
CM_ SG_ 1618 Point_91_Attribute "点的高低";
CM_ SG_ 1618 Point_90_Y "点的Y坐标";
CM_ SG_ 1618 Point_90_X "点的X坐标";
CM_ SG_ 1618 Point_90_ID "点的ID";
CM_ SG_ 1618 Point_90_Attribute "点的高低";
CM_ SG_ 1731 Point_89_Y "点的Y坐标";
CM_ SG_ 1731 Point_89_X "点的X坐标";
CM_ SG_ 1731 Point_89_ID "点的ID";
CM_ SG_ 1731 Point_89_Attribute "点的高低";
CM_ SG_ 1731 Point_88_Y "点的Y坐标";
CM_ SG_ 1731 Point_88_X "点的X坐标";
CM_ SG_ 1731 Point_88_ID "点的ID";
CM_ SG_ 1731 Point_88_Attribute "点的高低";
CM_ SG_ 1731 Point_87_Y "点的Y坐标";
CM_ SG_ 1731 Point_87_X "点的X坐标";
CM_ SG_ 1731 Point_87_ID "点的ID";
CM_ SG_ 1731 Point_87_Attribute "点的高低";
CM_ SG_ 1731 Point_86_Y "点的Y坐标";
CM_ SG_ 1731 Point_86_X "点的X坐标";
CM_ SG_ 1731 Point_86_ID "点的ID";
CM_ SG_ 1731 Point_86_Attribute "点的高低";
CM_ SG_ 1731 Point_85_Y "点的Y坐标";
CM_ SG_ 1731 Point_85_X "点的X坐标";
CM_ SG_ 1731 Point_85_ID "点的ID";
CM_ SG_ 1731 Point_85_Attribute "点的高低";
CM_ SG_ 1731 Point_84_Y "点的Y坐标";
CM_ SG_ 1731 Point_84_X "点的X坐标";
CM_ SG_ 1731 Point_84_ID "点的ID";
CM_ SG_ 1731 Point_84_Attribute "点的高低";
CM_ SG_ 1731 Point_83_Y "点的Y坐标";
CM_ SG_ 1731 Point_83_X "点的X坐标";
CM_ SG_ 1731 Point_83_ID "点的ID";
CM_ SG_ 1731 Point_83_Attribute "点的高低";
CM_ SG_ 1731 Point_82_Y "点的Y坐标";
CM_ SG_ 1731 Point_82_X "点的X坐标";
CM_ SG_ 1731 Point_82_ID "点的ID";
CM_ SG_ 1731 Point_82_Attribute "点的高低";
CM_ SG_ 1731 Point_81_Y "点的Y坐标";
CM_ SG_ 1731 Point_81_X "点的X坐标";
CM_ SG_ 1731 Point_81_ID "点的ID";
CM_ SG_ 1731 Point_81_Attribute "点的高低";
CM_ SG_ 1731 Point_80_Y "点的Y坐标";
CM_ SG_ 1731 Point_80_X "点的X坐标";
CM_ SG_ 1731 Point_80_ID "点的ID";
CM_ SG_ 1731 Point_80_Attribute "点的高低";
CM_ SG_ 1730 Point_79_Y "点的Y坐标";
CM_ SG_ 1730 Point_79_X "点的X坐标";
CM_ SG_ 1730 Point_79_ID "点的ID";
CM_ SG_ 1730 Point_79_Attribute "点的高低";
CM_ SG_ 1730 Point_78_Y "点的Y坐标";
CM_ SG_ 1730 Point_78_X "点的X坐标";
CM_ SG_ 1730 Point_78_ID "点的ID";
CM_ SG_ 1730 Point_78_Attribute "点的高低";
CM_ SG_ 1730 Point_77_Y "点的Y坐标";
CM_ SG_ 1730 Point_77_X "点的X坐标";
CM_ SG_ 1730 Point_77_ID "点的ID";
CM_ SG_ 1730 Point_77_Attribute "点的高低";
CM_ SG_ 1730 Point_76_Y "点的Y坐标";
CM_ SG_ 1730 Point_76_X "点的X坐标";
CM_ SG_ 1730 Point_76_ID "点的ID";
CM_ SG_ 1730 Point_76_Attribute "点的高低";
CM_ SG_ 1730 Point_75_Y "点的Y坐标";
CM_ SG_ 1730 Point_75_X "点的X坐标";
CM_ SG_ 1730 Point_75_ID "点的ID";
CM_ SG_ 1730 Point_75_Attribute "点的高低";
CM_ SG_ 1730 Point_74_Y "点的Y坐标";
CM_ SG_ 1730 Point_74_X "点的X坐标";
CM_ SG_ 1730 Point_74_ID "点的ID";
CM_ SG_ 1730 Point_74_Attribute "点的高低";
CM_ SG_ 1730 Point_73_Y "点的Y坐标";
CM_ SG_ 1730 Point_73_X "点的X坐标";
CM_ SG_ 1730 Point_73_ID "点的ID";
CM_ SG_ 1730 Point_73_Attribute "点的高低";
CM_ SG_ 1730 Point_72_Y "点的Y坐标";
CM_ SG_ 1730 Point_72_X "点的X坐标";
CM_ SG_ 1730 Point_72_ID "点的ID";
CM_ SG_ 1730 Point_72_Attribute "点的高低";
CM_ SG_ 1730 Point_71_Y "点的Y坐标";
CM_ SG_ 1730 Point_71_X "点的X坐标";
CM_ SG_ 1730 Point_71_ID "点的ID";
CM_ SG_ 1730 Point_71_Attribute "点的高低";
CM_ SG_ 1730 Point_70_Y "点的Y坐标";
CM_ SG_ 1730 Point_70_X "点的X坐标";
CM_ SG_ 1730 Point_70_ID "点的ID";
CM_ SG_ 1730 Point_70_Attribute "点的高低";
CM_ SG_ 1729 Point_69_Y "点的Y坐标";
CM_ SG_ 1729 Point_69_X "点的X坐标";
CM_ SG_ 1729 Point_69_ID "点的ID";
CM_ SG_ 1729 Point_69_Attribute "点的高低";
CM_ SG_ 1729 Point_68_Y "点的Y坐标";
CM_ SG_ 1729 Point_68_X "点的X坐标";
CM_ SG_ 1729 Point_68_ID "点的ID";
CM_ SG_ 1729 Point_68_Attribute "点的高低";
CM_ SG_ 1729 Point_67_Y "点的Y坐标";
CM_ SG_ 1729 Point_67_X "点的X坐标";
CM_ SG_ 1729 Point_67_ID "点的ID";
CM_ SG_ 1729 Point_67_Attribute "点的高低";
CM_ SG_ 1729 Point_66_Y "点的Y坐标";
CM_ SG_ 1729 Point_66_X "点的X坐标";
CM_ SG_ 1729 Point_66_ID "点的ID";
CM_ SG_ 1729 Point_66_Attribute "点的高低";
CM_ SG_ 1729 Point_65_Y "点的Y坐标";
CM_ SG_ 1729 Point_65_X "点的X坐标";
CM_ SG_ 1729 Point_65_ID "点的ID";
CM_ SG_ 1729 Point_65_Attribute "点的高低";
CM_ SG_ 1729 Point_64_Y "点的Y坐标";
CM_ SG_ 1729 Point_64_X "点的X坐标";
CM_ SG_ 1729 Point_64_ID "点的ID";
CM_ SG_ 1729 Point_64_Attribute "点的高低";
CM_ SG_ 1729 Point_63_Y "点的Y坐标";
CM_ SG_ 1729 Point_63_X "点的X坐标";
CM_ SG_ 1729 Point_63_ID "点的ID";
CM_ SG_ 1729 Point_63_Attribute "点的高低";
CM_ SG_ 1729 Point_62_Y "点的Y坐标";
CM_ SG_ 1729 Point_62_X "点的X坐标";
CM_ SG_ 1729 Point_62_ID "点的ID";
CM_ SG_ 1729 Point_62_Attribute "点的高低";
CM_ SG_ 1729 Point_61_Y "点的Y坐标";
CM_ SG_ 1729 Point_61_X "点的X坐标";
CM_ SG_ 1729 Point_61_ID "点的ID";
CM_ SG_ 1729 Point_61_Attribute "点的高低";
CM_ SG_ 1729 Point_60_Y "点的Y坐标";
CM_ SG_ 1729 Point_60_X "点的X坐标";
CM_ SG_ 1729 Point_60_ID "点的ID";
CM_ SG_ 1729 Point_60_Attribute "点的高低";
CM_ SG_ 1728 Point_59_Y "点的Y坐标";
CM_ SG_ 1728 Point_59_X "点的X坐标";
CM_ SG_ 1728 Point_59_ID "点的ID";
CM_ SG_ 1728 Point_59_Attribute "点的高低";
CM_ SG_ 1728 Point_58_Y "点的Y坐标";
CM_ SG_ 1728 Point_58_X "点的X坐标";
CM_ SG_ 1728 Point_58_ID "点的ID";
CM_ SG_ 1728 Point_58_Attribute "点的高低";
CM_ SG_ 1728 Point_57_Y "点的Y坐标";
CM_ SG_ 1728 Point_57_X "点的X坐标";
CM_ SG_ 1728 Point_57_ID "点的ID";
CM_ SG_ 1728 Point_57_Attribute "点的高低";
CM_ SG_ 1728 Point_56_Y "点的Y坐标";
CM_ SG_ 1728 Point_56_X "点的X坐标";
CM_ SG_ 1728 Point_56_ID "点的ID";
CM_ SG_ 1728 Point_56_Attribute "点的高低";
CM_ SG_ 1728 Point_55_Y "点的Y坐标";
CM_ SG_ 1728 Point_55_X "点的X坐标";
CM_ SG_ 1728 Point_55_ID "点的ID";
CM_ SG_ 1728 Point_55_Attribute "点的高低";
CM_ SG_ 1728 Point_54_Y "点的Y坐标";
CM_ SG_ 1728 Point_54_X "点的X坐标";
CM_ SG_ 1728 Point_54_ID "点的ID";
CM_ SG_ 1728 Point_54_Attribute "点的高低";
CM_ SG_ 1728 Point_53_Y "点的Y坐标";
CM_ SG_ 1728 Point_53_X "点的X坐标";
CM_ SG_ 1728 Point_53_ID "点的ID";
CM_ SG_ 1728 Point_53_Attribute "点的高低";
CM_ SG_ 1728 Point_52_Y "点的Y坐标";
CM_ SG_ 1728 Point_52_X "点的X坐标";
CM_ SG_ 1728 Point_52_ID "点的ID";
CM_ SG_ 1728 Point_52_Attribute "点的高低";
CM_ SG_ 1728 Point_51_Y "点的Y坐标";
CM_ SG_ 1728 Point_51_X "点的X坐标";
CM_ SG_ 1728 Point_51_ID "点的ID";
CM_ SG_ 1728 Point_51_Attribute "点的高低";
CM_ SG_ 1728 Point_50_Y "点的Y坐标";
CM_ SG_ 1728 Point_50_X "点的X坐标";
CM_ SG_ 1728 Point_50_ID "点的ID";
CM_ SG_ 1728 Point_50_Attribute "点的高低";
CM_ SG_ 1727 Point_49_Y "点的Y坐标";
CM_ SG_ 1727 Point_49_X "点的X坐标";
CM_ SG_ 1727 Point_49_ID "点的ID";
CM_ SG_ 1727 Point_49_Attribute "点的高低";
CM_ SG_ 1727 Point_48_Y "点的Y坐标";
CM_ SG_ 1727 Point_48_X "点的X坐标";
CM_ SG_ 1727 Point_48_ID "点的ID";
CM_ SG_ 1727 Point_48_Attribute "点的高低";
CM_ SG_ 1727 Point_47_Y "点的Y坐标";
CM_ SG_ 1727 Point_47_X "点的X坐标";
CM_ SG_ 1727 Point_47_ID "点的ID";
CM_ SG_ 1727 Point_47_Attribute "点的高低";
CM_ SG_ 1727 Point_46_Y "点的Y坐标";
CM_ SG_ 1727 Point_46_X "点的X坐标";
CM_ SG_ 1727 Point_46_ID "点的ID";
CM_ SG_ 1727 Point_46_Attribute "点的高低";
CM_ SG_ 1727 Point_45_Y "点的Y坐标";
CM_ SG_ 1727 Point_45_X "点的X坐标";
CM_ SG_ 1727 Point_45_ID "点的ID";
CM_ SG_ 1727 Point_45_Attribute "点的高低";
CM_ SG_ 1727 Point_44_Y "点的Y坐标";
CM_ SG_ 1727 Point_44_X "点的X坐标";
CM_ SG_ 1727 Point_44_ID "点的ID";
CM_ SG_ 1727 Point_44_Attribute "点的高低";
CM_ SG_ 1727 Point_43_Y "点的Y坐标";
CM_ SG_ 1727 Point_43_X "点的X坐标";
CM_ SG_ 1727 Point_43_ID "点的ID";
CM_ SG_ 1727 Point_43_Attribute "点的高低";
CM_ SG_ 1727 Point_42_Y "点的Y坐标";
CM_ SG_ 1727 Point_42_X "点的X坐标";
CM_ SG_ 1727 Point_42_ID "点的ID";
CM_ SG_ 1727 Point_42_Attribute "点的高低";
CM_ SG_ 1727 Point_41_Y "点的Y坐标";
CM_ SG_ 1727 Point_41_X "点的X坐标";
CM_ SG_ 1727 Point_41_ID "点的ID";
CM_ SG_ 1727 Point_41_Attribute "点的高低";
CM_ SG_ 1727 Point_40_Y "点的Y坐标";
CM_ SG_ 1727 Point_40_X "点的X坐标";
CM_ SG_ 1727 Point_40_ID "点的ID";
CM_ SG_ 1727 Point_40_Attribute "点的高低";
CM_ SG_ 1726 Point_39_Y "点的Y坐标";
CM_ SG_ 1726 Point_39_X "点的X坐标";
CM_ SG_ 1726 Point_39_ID "点的ID";
CM_ SG_ 1726 Point_39_Attribute "点的高低";
CM_ SG_ 1726 Point_38_Y "点的Y坐标";
CM_ SG_ 1726 Point_38_X "点的X坐标";
CM_ SG_ 1726 Point_38_ID "点的ID";
CM_ SG_ 1726 Point_38_Attribute "点的高低";
CM_ SG_ 1726 Point_37_Y "点的Y坐标";
CM_ SG_ 1726 Point_37_X "点的X坐标";
CM_ SG_ 1726 Point_37_ID "点的ID";
CM_ SG_ 1726 Point_37_Attribute "点的高低";
CM_ SG_ 1726 Point_36_Y "点的Y坐标";
CM_ SG_ 1726 Point_36_X "点的X坐标";
CM_ SG_ 1726 Point_36_ID "点的ID";
CM_ SG_ 1726 Point_36_Attribute "点的高低";
CM_ SG_ 1726 Point_35_Y "点的Y坐标";
CM_ SG_ 1726 Point_35_X "点的X坐标";
CM_ SG_ 1726 Point_35_ID "点的ID";
CM_ SG_ 1726 Point_35_Attribute "点的高低";
CM_ SG_ 1726 Point_34_Y "点的Y坐标";
CM_ SG_ 1726 Point_34_X "点的X坐标";
CM_ SG_ 1726 Point_34_ID "点的ID";
CM_ SG_ 1726 Point_34_Attribute "点的高低";
CM_ SG_ 1726 Point_33_Y "点的Y坐标";
CM_ SG_ 1726 Point_33_X "点的X坐标";
CM_ SG_ 1726 Point_33_ID "点的ID";
CM_ SG_ 1726 Point_33_Attribute "点的高低";
CM_ SG_ 1726 Point_32_Y "点的Y坐标";
CM_ SG_ 1726 Point_32_X "点的X坐标";
CM_ SG_ 1726 Point_32_ID "点的ID";
CM_ SG_ 1726 Point_32_Attribute "点的高低";
CM_ SG_ 1726 Point_31_Y "点的Y坐标";
CM_ SG_ 1726 Point_31_X "点的X坐标";
CM_ SG_ 1726 Point_31_ID "点的ID";
CM_ SG_ 1726 Point_31_Attribute "点的高低";
CM_ SG_ 1726 Point_30_Y "点的Y坐标";
CM_ SG_ 1726 Point_30_X "点的X坐标";
CM_ SG_ 1726 Point_30_ID "点的ID";
CM_ SG_ 1726 Point_30_Attribute "点的高低";
CM_ SG_ 1725 Point_29_Y "点的Y坐标";
CM_ SG_ 1725 Point_29_X "点的X坐标";
CM_ SG_ 1725 Point_29_ID "点的ID";
CM_ SG_ 1725 Point_29_Attribute "点的高低";
CM_ SG_ 1725 Point_28_Y "点的Y坐标";
CM_ SG_ 1725 Point_28_X "点的X坐标";
CM_ SG_ 1725 Point_28_ID "点的ID";
CM_ SG_ 1725 Point_28_Attribute "点的高低";
CM_ SG_ 1725 Point_27_Y "点的Y坐标";
CM_ SG_ 1725 Point_27_X "点的X坐标";
CM_ SG_ 1725 Point_27_ID "点的ID";
CM_ SG_ 1725 Point_27_Attribute "点的高低";
CM_ SG_ 1725 Point_26_Y "点的Y坐标";
CM_ SG_ 1725 Point_26_X "点的X坐标";
CM_ SG_ 1725 Point_26_ID "点的ID";
CM_ SG_ 1725 Point_26_Attribute "点的高低";
CM_ SG_ 1725 Point_25_Y "点的Y坐标";
CM_ SG_ 1725 Point_25_X "点的X坐标";
CM_ SG_ 1725 Point_25_ID "点的ID";
CM_ SG_ 1725 Point_25_Attribute "点的高低";
CM_ SG_ 1725 Point_24_Y "点的Y坐标";
CM_ SG_ 1725 Point_24_X "点的X坐标";
CM_ SG_ 1725 Point_24_ID "点的ID";
CM_ SG_ 1725 Point_24_Attribute "点的高低";
CM_ SG_ 1725 Point_23_Y "点的Y坐标";
CM_ SG_ 1725 Point_23_X "点的X坐标";
CM_ SG_ 1725 Point_23_ID "点的ID";
CM_ SG_ 1725 Point_23_Attribute "点的高低";
CM_ SG_ 1725 Point_22_Y "点的Y坐标";
CM_ SG_ 1725 Point_22_X "点的X坐标";
CM_ SG_ 1725 Point_22_ID "点的ID";
CM_ SG_ 1725 Point_22_Attribute "点的高低";
CM_ SG_ 1725 Point_21_Y "点的Y坐标";
CM_ SG_ 1725 Point_21_X "点的X坐标";
CM_ SG_ 1725 Point_21_ID "点的ID";
CM_ SG_ 1725 Point_21_Attribute "点的高低";
CM_ SG_ 1725 Point_20_Y "点的Y坐标";
CM_ SG_ 1725 Point_20_X "点的X坐标";
CM_ SG_ 1725 Point_20_ID "点的ID";
CM_ SG_ 1725 Point_20_Attribute "点的高低";
CM_ SG_ 1724 Point_19_Y "点的Y坐标";
CM_ SG_ 1724 Point_19_X "点的X坐标";
CM_ SG_ 1724 Point_19_ID "点的ID";
CM_ SG_ 1724 Point_19_Attribute "点的高低";
CM_ SG_ 1724 Point_18_Y "点的Y坐标";
CM_ SG_ 1724 Point_18_X "点的X坐标";
CM_ SG_ 1724 Point_18_ID "点的ID";
CM_ SG_ 1724 Point_18_Attribute "点的高低";
CM_ SG_ 1724 Point_17_Y "点的Y坐标";
CM_ SG_ 1724 Point_17_X "点的X坐标";
CM_ SG_ 1724 Point_17_ID "点的ID";
CM_ SG_ 1724 Point_17_Attribute "点的高低";
CM_ SG_ 1724 Point_16_Y "点的Y坐标";
CM_ SG_ 1724 Point_16_X "点的X坐标";
CM_ SG_ 1724 Point_16_ID "点的ID";
CM_ SG_ 1724 Point_16_Attribute "点的高低";
CM_ SG_ 1724 Point_15_Y "点的Y坐标";
CM_ SG_ 1724 Point_15_X "点的X坐标";
CM_ SG_ 1724 Point_15_ID "点的ID";
CM_ SG_ 1724 Point_15_Attribute "点的高低";
CM_ SG_ 1724 Point_14_Y "点的Y坐标";
CM_ SG_ 1724 Point_14_X "点的X坐标";
CM_ SG_ 1724 Point_14_ID "点的ID";
CM_ SG_ 1724 Point_14_Attribute "点的高低";
CM_ SG_ 1724 Point_13_Y "点的Y坐标";
CM_ SG_ 1724 Point_13_X "点的X坐标";
CM_ SG_ 1724 Point_13_ID "点的ID";
CM_ SG_ 1724 Point_13_Attribute "点的高低";
CM_ SG_ 1724 Point_12_Y "点的Y坐标";
CM_ SG_ 1724 Point_12_X "点的X坐标";
CM_ SG_ 1724 Point_12_ID "点的ID";
CM_ SG_ 1724 Point_12_Attribute "点的高低";
CM_ SG_ 1724 Point_11_Y "点的Y坐标";
CM_ SG_ 1724 Point_11_X "点的X坐标";
CM_ SG_ 1724 Point_11_ID "点的ID";
CM_ SG_ 1724 Point_11_Attribute "点的高低";
CM_ SG_ 1724 Point_10_Y "点的Y坐标";
CM_ SG_ 1724 Point_10_X "点的X坐标";
CM_ SG_ 1724 Point_10_ID "点的ID";
CM_ SG_ 1724 Point_10_Attribute "点的高低";
CM_ SG_ 1723 Point_09_Y "点的Y坐标";
CM_ SG_ 1723 Point_09_X "点的X坐标";
CM_ SG_ 1723 Point_09_ID "点的ID";
CM_ SG_ 1723 Point_09_Attribute "点的高低";
CM_ SG_ 1723 Point_08_Y "点的Y坐标";
CM_ SG_ 1723 Point_08_X "点的X坐标";
CM_ SG_ 1723 Point_08_ID "点的ID";
CM_ SG_ 1723 Point_08_Attribute "点的高低";
CM_ SG_ 1723 Point_07_Y "点的Y坐标";
CM_ SG_ 1723 Point_07_X "点的X坐标";
CM_ SG_ 1723 Point_07_ID "点的ID";
CM_ SG_ 1723 Point_07_Attribute "点的高低";
CM_ SG_ 1723 Point_06_Y "点的Y坐标";
CM_ SG_ 1723 Point_06_X "点的X坐标";
CM_ SG_ 1723 Point_06_ID "点的ID";
CM_ SG_ 1723 Point_06_Attribute "点的高低";
CM_ SG_ 1723 Point_05_Y "点的Y坐标";
CM_ SG_ 1723 Point_05_X "点的X坐标";
CM_ SG_ 1723 Point_05_ID "点的ID";
CM_ SG_ 1723 Point_05_Attribute "点的高低";
CM_ SG_ 1723 Point_04_Y "点的Y坐标";
CM_ SG_ 1723 Point_04_X "点的X坐标";
CM_ SG_ 1723 Point_04_ID "点的ID";
CM_ SG_ 1723 Point_04_Attribute "点的高低";
CM_ SG_ 1723 Point_03_Y "点的Y坐标";
CM_ SG_ 1723 Point_03_X "点的X坐标";
CM_ SG_ 1723 Point_03_ID "点的ID";
CM_ SG_ 1723 Point_03_Attribute "点的高低";
CM_ SG_ 1723 Point_02_Y "点的Y坐标";
CM_ SG_ 1723 Point_02_X "点的X坐标";
CM_ SG_ 1723 Point_02_ID "点的ID";
CM_ SG_ 1723 Point_02_Attribute "点的高低";
CM_ SG_ 1723 Point_01_Y "点的Y坐标";
CM_ SG_ 1723 Point_01_X "点的X坐标";
CM_ SG_ 1723 Point_01_ID "点的ID";
CM_ SG_ 1723 Point_00_Attribute "点的高低";
CM_ SG_ 1723 Point_ValidNum "障碍物点当前有效个数";
CM_ SG_ 1723 Point_01_Attribute "点的高低";
CM_ SG_ 1723 Point_00_Y "点的Y坐标";
CM_ SG_ 1723 Point_00_X "点的X坐标";
CM_ SG_ 1723 Point_00_ID "点的ID";
CM_ SG_ 513 PAS_sonar1_DISTANCE "距离";
CM_ SG_ 513 PASsonar1DISTANCETime "1号雷达发波时间戳";
CM_ SG_ 513 PAS_sonar1_Blind "盲区";
CM_ SG_ 513 PAS_sonar1_crossDistanceLeft "1号雷达发、0号雷达收的间接回波的距离";
CM_ SG_ 513 PAS_sonar1_crossDistanceRight "1号雷达发、2号雷达收的间接回波的距离";
CM_ SG_ 513 PASsonar1crossDistanceLeftTime "1号雷达发、0号雷达收的间接回波的距离时间戳——发波时间戳";
CM_ SG_ 513 PASsonar1crossDistanceRightTime "1号雷达发、2号雷达收的间接回波的距离时间戳——发波时间戳";
CM_ SG_ 513 PAS_sonar1_confidence "置信度";
CM_ SG_ 513 PAS_sonar1_Counter "探头发波计数器";
CM_ SG_ 513 PAS_sonar2_DISTANCE "距离";
CM_ SG_ 513 PASsonar2DISTANCETime "2号雷达收到直接回波的时间戳发波时间戳";
CM_ SG_ 513 PAS_sonar2_Blind "盲区";
CM_ SG_ 513 PAS_sonar2_crossDistanceLeft "2号雷达发、1号雷达收的间接回波的距离";
CM_ SG_ 513 PAS_sonar2_crossDistanceRight "2号雷达发、3号雷达收的间接回波的距离";
CM_ SG_ 513 PASsonar2crossDistanceLeftTime "2号雷达发、1号雷达收的间接回波的距离时间戳——发波时间戳";
CM_ SG_ 513 PASsonar2crossDistanceRightTime "2号雷达发、3号雷达收的间接回波的距离时间戳——发波时间戳";
CM_ SG_ 513 PAS_sonar2_confidence "置信度";
CM_ SG_ 513 PAS_sonar2_Counter "探头发波计数器";
CM_ SG_ 513 PAS_sonar3_DISTANCE "距离";
CM_ SG_ 513 PASsonar3DISTANCETime "3号雷达收到直接回波的时间戳——发波时间戳";
CM_ SG_ 513 PAS_sonar3_Blind "盲区";
CM_ SG_ 513 PAS_sonar3_crossDistanceLeft "3号雷达发、2号雷达收的间接回波的距离";
CM_ SG_ 513 PAS_sonar3_crossDistanceRight "3号雷达发、4号雷达收的间接回波的距离";
CM_ SG_ 513 PASsonar3crossDistanceLeftTime "3号雷达发、2号雷达收的间接回波的距离时间戳——发波时间戳";
CM_ SG_ 513 PASsonar3crossDistanceRightTime "3号雷达发、4号雷达收的间接回波的距离时间戳——发波时间戳";
CM_ SG_ 513 PAS_sonar3_confidence "置信度";
CM_ SG_ 513 PAS_sonar3_Counter "探头发波计数器";
CM_ SG_ 513 PAS_sonar4_DISTANCE "距离";
CM_ SG_ 513 PASsonar4DISTANCETime "4号雷达收到直接回波的时间戳——发波时间戳";
CM_ SG_ 513 PAS_sonar4_Blind "盲区";
CM_ SG_ 513 PAS_sonar4_crossDistanceLeft "4号雷达发、3号雷达收的间接回波的距离";
CM_ SG_ 513 PAS_sonar4_crossDistanceRight "4号雷达发、5号雷达收的间接回波的距离";
CM_ SG_ 513 PASsonar4crossDistanceLeftTime "4号雷达发、3号雷达收的间接回波的距离时间戳——发波时间戳";
CM_ SG_ 513 PASsonar4crossDistanceRightTime "4号雷达发、5号雷达收的间接回波的距离时间戳——发波时间戳";
CM_ SG_ 513 PAS_sonar4_confidence "置信度";
CM_ SG_ 513 PAS_sonar4_Counter "探头发波计数器";
CM_ SG_ 513 PAS_sonar0_DISTANCE "距离";
CM_ SG_ 513 PASsonar0DISTANCETime "0号雷达收到直接回波的时间戳——发波时间戳";
CM_ SG_ 513 PAS_sonar0_Blind "盲区";
CM_ SG_ 513 PAS_sonar0_crossDistanceLeft "左侧交叉距离";
CM_ SG_ 513 PAS_sonar0_crossDistanceRight "0号雷达发、1号雷达收的间接回波的距离——发波时间戳";
CM_ SG_ 513 PASsonar0crossDistanceRightTime "0号雷达发、1号雷达收的间接回波的距离时间戳——发波时间戳";
CM_ SG_ 513 PAS_sonar0_confidence "置信度";
CM_ SG_ 513 PAS_sonar0_Counter "探头发波计数器";
CM_ SG_ 513 PAS_sonar5_DISTANCE "距离";
CM_ SG_ 513 PASsonar5DISTANCETime "5号雷达收到直接回波的时间戳——发波时间戳";
CM_ SG_ 513 PAS_sonar5_Blind "盲区";
CM_ SG_ 513 PAS_sonar5_crossDistanceLeft "左侧交叉距离";
CM_ SG_ 513 PAS_sonar5_crossDistanceRight "右侧交叉距离";
CM_ SG_ 513 PASsonar5crossDistanceLeftTime "5号雷达发、4号雷达收的间接回波的距离时间戳——发波时间戳";
CM_ SG_ 513 PAS_sonar5_confidence "置信度";
CM_ SG_ 513 PAS_sonar5_Counter "探头发波计数器";
CM_ SG_ 513 PASDistanceFrontRollingCounter "消息计数器";
CM_ SG_ 513 PAS_Distance_Front_Checksum "校验码";
CM_ SG_ 513 Fill4bit "填充位";
CM_ SG_ 514 PAS_sonar7_DISTANCE "距离";
CM_ SG_ 514 PASsonar7DISTANCETime "7号雷达收到直接回波的时间戳——发波时间戳";
CM_ SG_ 514 PAS_sonar7_Blind "盲区";
CM_ SG_ 514 PAS_sonar7_crossDistanceLeft "7号雷达发、6号雷达收的间接回波的距离";
CM_ SG_ 514 PAS_sonar7_crossDistanceRight "7号雷达发、8号雷达收的间接回波的距离";
CM_ SG_ 514 PASsonar7crossDistanceLeftTime "7号雷达发、6号雷达收的间接回波的距离时间戳——发波时间戳";
CM_ SG_ 514 PASsonar7crossDistanceRightTime "7号雷达发、8号雷达收的间接回波的距离时间戳——发波时间戳";
CM_ SG_ 514 PAS_sonar7_confidence "置信度";
CM_ SG_ 514 PAS_sonar7_Counter "探头发波计数器";
CM_ SG_ 514 PAS_sonar8_DISTANCE "距离";
CM_ SG_ 514 PASsonar8DISTANCETime "8号雷达收到直接回波的时间戳——发波时间戳";
CM_ SG_ 514 PAS_sonar8_Blind "盲区";
CM_ SG_ 514 PAS_sonar8_crossDistanceLeft "8号雷达发、7号雷达收的间接回波的距离";
CM_ SG_ 514 PAS_sonar8_crossDistanceRight "8号雷达发、9号雷达收的间接回波的距离";
CM_ SG_ 514 PASsonar8crossDistanceLeftTime "8号雷达发、7号雷达收的间接回波的距离时间戳——发波时间戳";
CM_ SG_ 514 PASsonar8crossDistanceRightTime "8号雷达发、9号雷达收的间接回波的距离时间戳——发波时间戳";
CM_ SG_ 514 PAS_sonar8_confidence "置信度";
CM_ SG_ 514 PAS_sonar8_Counter "探头发波计数器";
CM_ SG_ 514 PAS_sonar9_DISTANCE "距离";
CM_ SG_ 514 PASsonar9DISTANCETime "9号雷达收到直接回波的时间戳——发波时间戳";
CM_ SG_ 514 PAS_sonar9_Blind "盲区";
CM_ SG_ 514 PAS_sonar9_crossDistanceLeft "9号雷达发、8号雷达收的间接回波的距离";
CM_ SG_ 514 PAS_sonar9_crossDistanceRight "9号雷达发、10号雷达收的间接回波的距离";
CM_ SG_ 514 PASsonar9crossDistanceLeftTime "9号雷达发、8号雷达收的间接回波的距离时间戳——发波时间戳";
CM_ SG_ 514 PASsonar9crossDistanceRightTime "9号雷达发、10号雷达收的间接回波的距离时间戳——发波时间戳";
CM_ SG_ 514 PAS_sonar9_confidence "置信度";
CM_ SG_ 514 PAS_sonar9_Counter "探头发波计数器";
CM_ SG_ 514 PAS_sonar10_DISTANCE "距离";
CM_ SG_ 514 PASsonar10DISTANCETime "10号雷达收到直接回波的时间戳——发波时间戳";
CM_ SG_ 514 PAS_sonar10_Blind "盲区";
CM_ SG_ 514 PAS_sonar10_crossDistanceLeft "10号雷达发、9号雷达收的间接回波的距离";
CM_ SG_ 514 PAS_sonar10_crossDistanceRight "10号雷达发、11号雷达收的间接回波的距离";
CM_ SG_ 514 PASsonar10crossDistanceLeftTime "10号雷达发、9号雷达收的间接回波的距离时间戳——发波时间戳";
CM_ SG_ 514 PASsonar10crossDistanceRightTime "10号雷达发、11号雷达收的间接回波的距离时间戳——发波时间戳";
CM_ SG_ 514 PAS_sonar10_confidence "置信度";
CM_ SG_ 514 PAS_sonar10_Counter "探头发波计数器";
CM_ SG_ 514 PAS_sonar6_DISTANCE "距离";
CM_ SG_ 514 PASsonar6DISTANCETime "6号雷达收到直接回波的时间戳——发波时间戳";
CM_ SG_ 514 PAS_sonar6_Blind "盲区";
CM_ SG_ 514 PAS_sonar6_crossDistanceLeft "左侧交叉距离";
CM_ SG_ 514 PAS_sonar6_crossDistanceRight "6号雷达发、7号雷达收的间接回波的距离——发波时间戳";
CM_ SG_ 514 PASsonar6crossDistanceRightTime "6号雷达发、7号雷达收的间接回波的距离时间戳——发波时间戳";
CM_ SG_ 514 PAS_sonar6_confidence "置信度";
CM_ SG_ 514 PAS_sonar6_Counter "探头发波计数器";
CM_ SG_ 514 PAS_sonar11_DISTANCE "距离";
CM_ SG_ 514 PASsonar11DISTANCETime "11号雷达收到直接回波的时间戳——发波时间戳";
CM_ SG_ 514 PAS_sonar11_Blind "盲区";
CM_ SG_ 514 PAS_sonar11_crossDistanceLeft "11号雷达发、10号雷达收的间接回波的距离";
CM_ SG_ 514 PAS_sonar11_crossDistanceRight "右侧交叉距离";
CM_ SG_ 514 PASsonar11crossDistanceLeftTime "11号雷达发、10号雷达收的间接回波的距离时间戳——发波时间戳";
CM_ SG_ 514 PAS_sonar11_confidence "置信度";
CM_ SG_ 514 PAS_sonar11_Counter "探头发波计数器";
CM_ SG_ 514 PAS_Distance_Rear_RollingCounter "消息计数器";
CM_ SG_ 514 PAS_Distance_Rear_Checksum "校验码";
CM_ SG_ 514 Fill4bit "填充位";
CM_ SG_ 515 PAS_Sonar0_Echo_TOF1 "第一次回波时间";
CM_ SG_ 515 PAS_Sonar0_Echo_Width1 "第一次回波宽度";
CM_ SG_ 515 PAS_Sonar0_Echo_TOF2 "第二次回波时间";
CM_ SG_ 515 PAS_Sonar0_Echo_Width2 "第二次回波宽度";
CM_ SG_ 515 PAS_Sonar0_Echo_Peak1 "第一次回波高度";
CM_ SG_ 515 PAS_Sonar0_Echo_Peak2 "第二次回波高度";
CM_ SG_ 515 PAS_Sonar0_Emit "对应探头是否发波";
CM_ SG_ 515 PAS_Sonar0_RingingTime "余振时间";
CM_ SG_ 515 PAS_Sonar0_Counter "探头工作计数器";
CM_ SG_ 515 PAS_Sonar1_Echo_TOF1 "第一次回波时间";
CM_ SG_ 515 PAS_Sonar1_Echo_Width1 "第一次回波宽度";
CM_ SG_ 515 PAS_Sonar1_Echo_TOF2 "第二次回波时间";
CM_ SG_ 515 PAS_Sonar1_Echo_Width2 "第二次回波宽度";
CM_ SG_ 515 PAS_Sonar1_Echo_Peak1 "第一次回波高度";
CM_ SG_ 515 PAS_Sonar1_Echo_Peak2 "第二次回波高度";
CM_ SG_ 515 PAS_Sonar1_Emit "对应探头是否发波";
CM_ SG_ 515 PAS_Sonar1_RingingTime "余振时间";
CM_ SG_ 515 PAS_Sonar1_Counter "探头工作计数器";
CM_ SG_ 515 PAS_Sonar2_Echo_TOF1 "第一次回波时间";
CM_ SG_ 515 PAS_Sonar2_Echo_Width1 "第一次回波宽度";
CM_ SG_ 515 PAS_Sonar2_Echo_TOF2 "第二次回波时间";
CM_ SG_ 515 PAS_Sonar2_Echo_Width2 "第二次回波宽度";
CM_ SG_ 515 PAS_Sonar2_Echo_Peak1 "第一次回波高度";
CM_ SG_ 515 PAS_Sonar2_Echo_Peak2 "第二次回波高度";
CM_ SG_ 515 PAS_Sonar2_Emit "对应探头是否发波";
CM_ SG_ 515 PAS_Sonar2_RingingTime "余振时间";
CM_ SG_ 515 PAS_Sonar2_Counter "探头工作计数器";
CM_ SG_ 515 PAS_Sonar3_Echo_TOF1 "第一次回波时间";
CM_ SG_ 515 PAS_Sonar3_Echo_Width1 "第一次回波宽度";
CM_ SG_ 515 PAS_Sonar3_Echo_TOF2 "第二次回波时间";
CM_ SG_ 515 PAS_Sonar3_Echo_Width2 "第二次回波宽度";
CM_ SG_ 515 PAS_Sonar3_Echo_Peak1 "第一次回波高度";
CM_ SG_ 515 PAS_Sonar3_Echo_Peak2 "第二次回波高度";
CM_ SG_ 515 PAS_Sonar3_Emit "对应探头是否发波";
CM_ SG_ 515 PAS_Sonar3_RingingTime "余振时间";
CM_ SG_ 515 PAS_Sonar3_Counter "探头工作计数器";
CM_ SG_ 515 PAS_Sonar4_Echo_TOF1 "第一次回波时间";
CM_ SG_ 515 PAS_Sonar4_Echo_Width1 "第一次回波宽度";
CM_ SG_ 515 PAS_Sonar4_Echo_TOF2 "第二次回波时间";
CM_ SG_ 515 PAS_Sonar4_Echo_Width2 "第二次回波宽度";
CM_ SG_ 515 PAS_Sonar4_Echo_Peak1 "第一次回波高度";
CM_ SG_ 515 PAS_Sonar4_Echo_Peak2 "第二次回波高度";
CM_ SG_ 515 PAS_Sonar4_Emit "对应探头是否发波";
CM_ SG_ 515 PAS_Sonar4_RingingTime "余振时间";
CM_ SG_ 515 PAS_Sonar4_Counter "探头工作计数器";
CM_ SG_ 515 PAS_Sonar5_Echo_TOF1 "第一次回波时间";
CM_ SG_ 515 PAS_Sonar5_Echo_Width1 "第一次回波宽度";
CM_ SG_ 515 PAS_Sonar5_Echo_TOF2 "第二次回波时间";
CM_ SG_ 515 PAS_Sonar5_Echo_Width2 "第二次回波宽度";
CM_ SG_ 515 PAS_Sonar5_Echo_Peak1 "第一次回波高度";
CM_ SG_ 515 PAS_Sonar5_Echo_Peak2 "第二次回波高度";
CM_ SG_ 515 PAS_Sonar5_Emit "对应探头是否发波";
CM_ SG_ 515 PAS_Sonar5_RingingTime "余振时间";
CM_ SG_ 515 PAS_Sonar5_Counter "探头工作计数器";
CM_ SG_ 515 PASSonarInfoFrontRollingCounter "消息计数器";
CM_ SG_ 515 PAS_SonarInfo_Front_Checksum "校验码";
CM_ SG_ 515 Fill4bit "填充位";
BA_DEF_ BO_  "GenMsgSendType" ENUM  "Cycle","Event","CE";
BA_DEF_ BO_  "GenMsgCycleTime" INT 0 0;
BA_DEF_ SG_  "GenSigSendType" ENUM  "Cycle","OnChange","OnWrite","IfActive","OnChangeWithRepetition","OnWriteWithRepetition","IfActiveWithRepetition";
BA_DEF_ SG_  "GenSigStartValue" INT 0 0;
BA_DEF_  "BusType" STRING ;
BA_DEF_ BO_  "VFrameFormat" ENUM  "StandardCAN","ExtendedCAN","reserved","reserved","reserved","reserved","reserved","reserved","reserved","reserved","reserved","reserved","reserved","reserved","StandardCAN_FD","ExtendedCAN_FD";
BA_DEF_DEF_  "GenMsgSendType" "Cycle";
BA_DEF_DEF_  "GenMsgCycleTime" 0;
BA_DEF_DEF_  "GenSigSendType" "Cycle";
BA_DEF_DEF_  "GenSigStartValue" 0;
BA_DEF_DEF_  "BusType" "";
BA_DEF_DEF_  "VFrameFormat" "";
BA_ "BusType" "CAN FD";
BA_ "GenMsgCycleTime" BO_ 1722 10;
BA_ "VFrameFormat" BO_ 1722 14;
BA_ "GenMsgCycleTime" BO_ 1617 100;
BA_ "VFrameFormat" BO_ 1617 14;
BA_ "VFrameFormat" BO_ 1616 14;
BA_ "GenMsgCycleTime" BO_ 1600 20;
BA_ "VFrameFormat" BO_ 1600 14;
BA_ "VFrameFormat" BO_ 1863 14;
BA_ "GenMsgCycleTime" BO_ 1862 40;
BA_ "VFrameFormat" BO_ 1862 14;
BA_ "GenMsgCycleTime" BO_ 1721 40;
BA_ "VFrameFormat" BO_ 1721 14;
BA_ "GenMsgCycleTime" BO_ 1720 40;
BA_ "VFrameFormat" BO_ 1720 14;
BA_ "GenMsgCycleTime" BO_ 1859 40;
BA_ "VFrameFormat" BO_ 1859 14;
BA_ "GenMsgCycleTime" BO_ 1719 40;
BA_ "VFrameFormat" BO_ 1719 14;
BA_ "GenMsgCycleTime" BO_ 1718 20;
BA_ "VFrameFormat" BO_ 1718 14;
BA_ "GenMsgCycleTime" BO_ 1622 40;
BA_ "VFrameFormat" BO_ 1622 14;
BA_ "GenMsgCycleTime" BO_ 1624 40;
BA_ "VFrameFormat" BO_ 1624 14;
BA_ "GenMsgCycleTime" BO_ 1623 40;
BA_ "VFrameFormat" BO_ 1623 14;
BA_ "GenMsgCycleTime" BO_ 1621 40;
BA_ "VFrameFormat" BO_ 1621 14;
BA_ "VFrameFormat" BO_ 1620 14;
BA_ "GenMsgCycleTime" BO_ 1619 40;
BA_ "VFrameFormat" BO_ 1619 14;
BA_ "GenMsgCycleTime" BO_ 1618 40;
BA_ "VFrameFormat" BO_ 1618 14;
BA_ "GenMsgCycleTime" BO_ 1731 40;
BA_ "VFrameFormat" BO_ 1731 14;
BA_ "GenMsgCycleTime" BO_ 1730 40;
BA_ "VFrameFormat" BO_ 1730 14;
BA_ "GenMsgCycleTime" BO_ 1729 40;
BA_ "VFrameFormat" BO_ 1729 14;
BA_ "GenMsgCycleTime" BO_ 1728 40;
BA_ "VFrameFormat" BO_ 1728 14;
BA_ "GenMsgCycleTime" BO_ 1727 40;
BA_ "VFrameFormat" BO_ 1727 14;
BA_ "GenMsgCycleTime" BO_ 1726 40;
BA_ "VFrameFormat" BO_ 1726 14;
BA_ "GenMsgCycleTime" BO_ 1725 40;
BA_ "VFrameFormat" BO_ 1725 14;
BA_ "GenMsgCycleTime" BO_ 1724 40;
BA_ "VFrameFormat" BO_ 1724 14;
BA_ "GenMsgCycleTime" BO_ 1723 40;
BA_ "VFrameFormat" BO_ 1723 14;
BA_ "GenMsgCycleTime" BO_ 513 20;
BA_ "VFrameFormat" BO_ 513 14;
BA_ "GenMsgCycleTime" BO_ 514 20;
BA_ "VFrameFormat" BO_ 514 14;
BA_ "GenMsgCycleTime" BO_ 515 20;
BA_ "VFrameFormat" BO_ 515 14;
BA_ "GenSigStartValue" SG_ 1600 VehiclePosition_Angle_BeforeRst 1800;
BA_ "GenSigStartValue" SG_ 1600 VehiclePosition_Y_BeforeRst 3276;
BA_ "GenSigStartValue" SG_ 1600 VehiclePosition_X_BeforeRst 3276;
BA_ "GenSigStartValue" SG_ 1600 VehiclePosition_Angle_Self 1800;
BA_ "GenSigStartValue" SG_ 1600 VehiclePosition_Y_Self 3276;
BA_ "GenSigStartValue" SG_ 1600 VehiclePosition_X_Self 3276;
BA_ "GenSigStartValue" SG_ 1600 VehiclePosition_Y 3276;
BA_ "GenSigStartValue" SG_ 1600 VehiclePosition_X 3276;
BA_ "GenSigStartValue" SG_ 1600 VehiclePosition_Angle 1800;
BA_ "GenSigStartValue" SG_ 1862 Left_ParkingSlot5_PtFY 3276;
BA_ "GenSigStartValue" SG_ 1862 Left_ParkingSlot5_PtFX 3276;
BA_ "GenSigStartValue" SG_ 1862 Left_ParkingSlot5_PtEY 3276;
BA_ "GenSigStartValue" SG_ 1862 Left_ParkingSlot5_PtEX 3276;
BA_ "GenSigStartValue" SG_ 1862 Left_ParkingSlot5_PtDY 3276;
BA_ "GenSigStartValue" SG_ 1862 Left_ParkingSlot5_PtDX 3276;
BA_ "GenSigStartValue" SG_ 1862 Left_ParkingSlot5_PtCY 3276;
BA_ "GenSigStartValue" SG_ 1862 Left_ParkingSlot5_PtCX 3276;
BA_ "GenSigStartValue" SG_ 1862 Left_ParkingSlot5_PtBY 3276;
BA_ "GenSigStartValue" SG_ 1862 Left_ParkingSlot5_PtBX 3276;
BA_ "GenSigStartValue" SG_ 1862 Left_ParkingSlot5_PtAY 3276;
BA_ "GenSigStartValue" SG_ 1862 Left_ParkingSlot5_PtAX 3276;
BA_ "GenSigStartValue" SG_ 1862 Left_ParkingSlot4_PtFY 3276;
BA_ "GenSigStartValue" SG_ 1862 Left_ParkingSlot4_PtFX 3276;
BA_ "GenSigStartValue" SG_ 1862 Left_ParkingSlot4_PtEY 3276;
BA_ "GenSigStartValue" SG_ 1862 Left_ParkingSlot4_PtEX 3276;
BA_ "GenSigStartValue" SG_ 1862 Left_ParkingSlot4_PtDY 3276;
BA_ "GenSigStartValue" SG_ 1862 Left_ParkingSlot4_PtDX 3276;
BA_ "GenSigStartValue" SG_ 1862 Left_ParkingSlot4_PtCY 3276;
BA_ "GenSigStartValue" SG_ 1721 Left_ParkingSlot4_PtCX 3276;
BA_ "GenSigStartValue" SG_ 1721 Left_ParkingSlot4_PtBY 3276;
BA_ "GenSigStartValue" SG_ 1721 Left_ParkingSlot4_PtBX 3276;
BA_ "GenSigStartValue" SG_ 1721 Left_ParkingSlot4_PtAY 3276;
BA_ "GenSigStartValue" SG_ 1721 Left_ParkingSlot4_PtAX 3276;
BA_ "GenSigStartValue" SG_ 1721 Left_ParkingSlot3_PtFY 3276;
BA_ "GenSigStartValue" SG_ 1721 Left_ParkingSlot3_PtFX 3276;
BA_ "GenSigStartValue" SG_ 1721 Left_ParkingSlot3_PtEY 3276;
BA_ "GenSigStartValue" SG_ 1721 Left_ParkingSlot3_PtEX 3276;
BA_ "GenSigStartValue" SG_ 1721 Left_ParkingSlot3_PtDY 3276;
BA_ "GenSigStartValue" SG_ 1721 Left_ParkingSlot3_PtDX 3276;
BA_ "GenSigStartValue" SG_ 1721 Left_ParkingSlot3_PtCY 3276;
BA_ "GenSigStartValue" SG_ 1721 Left_ParkingSlot3_PtCX 3276;
BA_ "GenSigStartValue" SG_ 1721 Left_ParkingSlot3_PtBY 3276;
BA_ "GenSigStartValue" SG_ 1721 Left_ParkingSlot3_PtBX 3276;
BA_ "GenSigStartValue" SG_ 1721 Left_ParkingSlot3_PtAY 3276;
BA_ "GenSigStartValue" SG_ 1721 Left_ParkingSlot3_PtAX 3276;
BA_ "GenSigStartValue" SG_ 1721 Left_ParkingSlot2_PtFY 3276;
BA_ "GenSigStartValue" SG_ 1721 Left_ParkingSlot2_PtFX 3276;
BA_ "GenSigStartValue" SG_ 1721 Left_ParkingSlot2_PtEY 3276;
BA_ "GenSigStartValue" SG_ 1720 Left_ParkingSlot2_PtEX 3276;
BA_ "GenSigStartValue" SG_ 1720 Left_ParkingSlot2_PtDY 3276;
BA_ "GenSigStartValue" SG_ 1720 Left_ParkingSlot2_PtDX 3276;
BA_ "GenSigStartValue" SG_ 1720 Left_ParkingSlot2_PtCY 3276;
BA_ "GenSigStartValue" SG_ 1720 Left_ParkingSlot2_PtCX 3276;
BA_ "GenSigStartValue" SG_ 1720 Left_ParkingSlot2_PtBY 3276;
BA_ "GenSigStartValue" SG_ 1720 Left_ParkingSlot2_PtBX 3276;
BA_ "GenSigStartValue" SG_ 1720 Left_ParkingSlot2_PtAY 3276;
BA_ "GenSigStartValue" SG_ 1720 Left_ParkingSlot2_PtAX 3276;
BA_ "GenSigStartValue" SG_ 1720 Left_ParkingSlot1_PtFY 3276;
BA_ "GenSigStartValue" SG_ 1720 Left_ParkingSlot1_PtFX 3276;
BA_ "GenSigStartValue" SG_ 1720 Left_ParkingSlot1_PtEY 3276;
BA_ "GenSigStartValue" SG_ 1720 Left_ParkingSlot1_PtEX 3276;
BA_ "GenSigStartValue" SG_ 1720 Left_ParkingSlot1_PtDY 3276;
BA_ "GenSigStartValue" SG_ 1720 Left_ParkingSlot1_PtDX 3276;
BA_ "GenSigStartValue" SG_ 1720 Left_ParkingSlot1_PtCY 3276;
BA_ "GenSigStartValue" SG_ 1720 Left_ParkingSlot1_PtCX 3276;
BA_ "GenSigStartValue" SG_ 1720 Left_ParkingSlot1_PtBY 3276;
BA_ "GenSigStartValue" SG_ 1720 Left_ParkingSlot1_PtBX 3276;
BA_ "GenSigStartValue" SG_ 1720 Left_ParkingSlot1_PtAY 3276;
BA_ "GenSigStartValue" SG_ 1720 Left_ParkingSlot1_PtAX 3276;
BA_ "GenSigStartValue" SG_ 1859 Right_ParkingSlot5_PtFY 3276;
BA_ "GenSigStartValue" SG_ 1859 Right_ParkingSlot5_PtFX 3276;
BA_ "GenSigStartValue" SG_ 1859 Right_ParkingSlot5_PtEY 3276;
BA_ "GenSigStartValue" SG_ 1859 Right_ParkingSlot5_PtEX 3276;
BA_ "GenSigStartValue" SG_ 1859 Right_ParkingSlot5_PtDY 3276;
BA_ "GenSigStartValue" SG_ 1859 Right_ParkingSlot5_PtDX 3276;
BA_ "GenSigStartValue" SG_ 1859 Right_ParkingSlot5_PtCY 3276;
BA_ "GenSigStartValue" SG_ 1859 Right_ParkingSlot5_PtCX 3276;
BA_ "GenSigStartValue" SG_ 1859 Right_ParkingSlot5_PtBY 3276;
BA_ "GenSigStartValue" SG_ 1859 Right_ParkingSlot5_PtBX 3276;
BA_ "GenSigStartValue" SG_ 1859 Right_ParkingSlot5_PtAY 3276;
BA_ "GenSigStartValue" SG_ 1859 Right_ParkingSlot5_PtAX 3276;
BA_ "GenSigStartValue" SG_ 1859 Right_ParkingSlot4_PtFY 3276;
BA_ "GenSigStartValue" SG_ 1859 Right_ParkingSlot4_PtFX 3276;
BA_ "GenSigStartValue" SG_ 1859 Right_ParkingSlot4_PtEY 3276;
BA_ "GenSigStartValue" SG_ 1859 Right_ParkingSlot4_PtEX 3276;
BA_ "GenSigStartValue" SG_ 1859 Right_ParkingSlot4_PtDY 3276;
BA_ "GenSigStartValue" SG_ 1859 Right_ParkingSlot4_PtDX 3276;
BA_ "GenSigStartValue" SG_ 1859 Right_ParkingSlot4_PtCY 3276;
BA_ "GenSigStartValue" SG_ 1719 Right_ParkingSlot4_PtCX 3276;
BA_ "GenSigStartValue" SG_ 1719 Right_ParkingSlot4_PtBY 3276;
BA_ "GenSigStartValue" SG_ 1719 Right_ParkingSlot4_PtBX 3276;
BA_ "GenSigStartValue" SG_ 1719 Right_ParkingSlot4_PtAY 3276;
BA_ "GenSigStartValue" SG_ 1719 Right_ParkingSlot4_PtAX 3276;
BA_ "GenSigStartValue" SG_ 1719 Right_ParkingSlot3_PtFY 3276;
BA_ "GenSigStartValue" SG_ 1719 Right_ParkingSlot3_PtFX 3276;
BA_ "GenSigStartValue" SG_ 1719 Right_ParkingSlot3_PtEY 3276;
BA_ "GenSigStartValue" SG_ 1719 Right_ParkingSlot3_PtEX 3276;
BA_ "GenSigStartValue" SG_ 1719 Right_ParkingSlot3_PtDY 3276;
BA_ "GenSigStartValue" SG_ 1719 Right_ParkingSlot3_PtDX 3276;
BA_ "GenSigStartValue" SG_ 1719 Right_ParkingSlot3_PtCY 3276;
BA_ "GenSigStartValue" SG_ 1719 Right_ParkingSlot3_PtCX 3276;
BA_ "GenSigStartValue" SG_ 1719 Right_ParkingSlot3_PtBY 3276;
BA_ "GenSigStartValue" SG_ 1719 Right_ParkingSlot3_PtBX 3276;
BA_ "GenSigStartValue" SG_ 1719 Right_ParkingSlot3_PtAY 3276;
BA_ "GenSigStartValue" SG_ 1719 Right_ParkingSlot3_PtAX 3276;
BA_ "GenSigStartValue" SG_ 1719 Right_ParkingSlot2_PtFY 3276;
BA_ "GenSigStartValue" SG_ 1719 Right_ParkingSlot2_PtFX 3276;
BA_ "GenSigStartValue" SG_ 1719 Right_ParkingSlot2_PtEY 3276;
BA_ "GenSigStartValue" SG_ 1718 Right_ParkingSlot2_PtEX 3276;
BA_ "GenSigStartValue" SG_ 1718 Right_ParkingSlot2_PtDY 3276;
BA_ "GenSigStartValue" SG_ 1718 Right_ParkingSlot2_PtDX 3276;
BA_ "GenSigStartValue" SG_ 1718 Right_ParkingSlot2_PtCY 3276;
BA_ "GenSigStartValue" SG_ 1718 Right_ParkingSlot2_PtCX 3276;
BA_ "GenSigStartValue" SG_ 1718 Right_ParkingSlot2_PtBY 3276;
BA_ "GenSigStartValue" SG_ 1718 Right_ParkingSlot2_PtBX 3276;
BA_ "GenSigStartValue" SG_ 1718 Right_ParkingSlot2_PtAY 3276;
BA_ "GenSigStartValue" SG_ 1718 Right_ParkingSlot2_PtAX 3276;
BA_ "GenSigStartValue" SG_ 1718 Right_ParkingSlot1_PtFY 3276;
BA_ "GenSigStartValue" SG_ 1718 Right_ParkingSlot1_PtFX 3276;
BA_ "GenSigStartValue" SG_ 1718 Right_ParkingSlot1_PtEY 3276;
BA_ "GenSigStartValue" SG_ 1718 Right_ParkingSlot1_PtEX 3276;
BA_ "GenSigStartValue" SG_ 1718 Right_ParkingSlot1_PtDY 3276;
BA_ "GenSigStartValue" SG_ 1718 Right_ParkingSlot1_PtDX 3276;
BA_ "GenSigStartValue" SG_ 1718 Right_ParkingSlot1_PtCY 3276;
BA_ "GenSigStartValue" SG_ 1718 Right_ParkingSlot1_PtCX 3276;
BA_ "GenSigStartValue" SG_ 1718 Right_ParkingSlot1_PtBY 3276;
BA_ "GenSigStartValue" SG_ 1718 Right_ParkingSlot1_PtBX 3276;
BA_ "GenSigStartValue" SG_ 1718 Right_ParkingSlot1_PtAY 3276;
BA_ "GenSigStartValue" SG_ 1718 Right_ParkingSlot1_PtAX 3276;
BA_ "GenSigStartValue" SG_ 1620 Point_119_Y 3276;
BA_ "GenSigStartValue" SG_ 1620 Point_119_X 3276;
BA_ "GenSigStartValue" SG_ 1620 Point_118_Y 3276;
BA_ "GenSigStartValue" SG_ 1620 Point_118_X 3276;
BA_ "GenSigStartValue" SG_ 1620 Point_117_Y 3276;
BA_ "GenSigStartValue" SG_ 1620 Point_117_X 3276;
BA_ "GenSigStartValue" SG_ 1620 Point_116_Y 3276;
BA_ "GenSigStartValue" SG_ 1620 Point_116_X 3276;
BA_ "GenSigStartValue" SG_ 1620 Point_115_Y 3276;
BA_ "GenSigStartValue" SG_ 1620 Point_115_X 3276;
BA_ "GenSigStartValue" SG_ 1620 Point_114_Y 3276;
BA_ "GenSigStartValue" SG_ 1620 Point_114_X 3276;
BA_ "GenSigStartValue" SG_ 1620 Point_113_Y 3276;
BA_ "GenSigStartValue" SG_ 1620 Point_113_X 3276;
BA_ "GenSigStartValue" SG_ 1620 Point_112_Y 3276;
BA_ "GenSigStartValue" SG_ 1620 Point_112_X 3276;
BA_ "GenSigStartValue" SG_ 1620 Point_111_Y 3276;
BA_ "GenSigStartValue" SG_ 1620 Point_111_X 3276;
BA_ "GenSigStartValue" SG_ 1620 Point_110_Y 3276;
BA_ "GenSigStartValue" SG_ 1620 Point_110_X 3276;
BA_ "GenSigStartValue" SG_ 1619 Point_109_Y 3276;
BA_ "GenSigStartValue" SG_ 1619 Point_109_X 3276;
BA_ "GenSigStartValue" SG_ 1619 Point_108_Y 3276;
BA_ "GenSigStartValue" SG_ 1619 Point_108_X 3276;
BA_ "GenSigStartValue" SG_ 1619 Point_107_Y 3276;
BA_ "GenSigStartValue" SG_ 1619 Point_107_X 3276;
BA_ "GenSigStartValue" SG_ 1619 Point_106_Y 3276;
BA_ "GenSigStartValue" SG_ 1619 Point_106_X 3276;
BA_ "GenSigStartValue" SG_ 1619 Point_105_Y 3276;
BA_ "GenSigStartValue" SG_ 1619 Point_105_X 3276;
BA_ "GenSigStartValue" SG_ 1619 Point_104_Y 3276;
BA_ "GenSigStartValue" SG_ 1619 Point_104_X 3276;
BA_ "GenSigStartValue" SG_ 1619 Point_103_Y 3276;
BA_ "GenSigStartValue" SG_ 1619 Point_103_X 3276;
BA_ "GenSigStartValue" SG_ 1619 Point_102_Y 3276;
BA_ "GenSigStartValue" SG_ 1619 Point_102_X 3276;
BA_ "GenSigStartValue" SG_ 1619 Point_101_Y 3276;
BA_ "GenSigStartValue" SG_ 1619 Point_101_X 3276;
BA_ "GenSigStartValue" SG_ 1619 Point_100_Y 3276;
BA_ "GenSigStartValue" SG_ 1619 Point_100_X 3276;
BA_ "GenSigStartValue" SG_ 1618 Point_99_Y 3276;
BA_ "GenSigStartValue" SG_ 1618 Point_99_X 3276;
BA_ "GenSigStartValue" SG_ 1618 Point_98_Y 3276;
BA_ "GenSigStartValue" SG_ 1618 Point_98_X 3276;
BA_ "GenSigStartValue" SG_ 1618 Point_97_Y 3276;
BA_ "GenSigStartValue" SG_ 1618 Point_97_X 3276;
BA_ "GenSigStartValue" SG_ 1618 Point_96_Y 3276;
BA_ "GenSigStartValue" SG_ 1618 Point_96_X 3276;
BA_ "GenSigStartValue" SG_ 1618 Point_95_Y 3276;
BA_ "GenSigStartValue" SG_ 1618 Point_95_X 3276;
BA_ "GenSigStartValue" SG_ 1618 Point_94_Y 3276;
BA_ "GenSigStartValue" SG_ 1618 Point_94_X 3276;
BA_ "GenSigStartValue" SG_ 1618 Point_93_Y 3276;
BA_ "GenSigStartValue" SG_ 1618 Point_93_X 3276;
BA_ "GenSigStartValue" SG_ 1618 Point_92_Y 3276;
BA_ "GenSigStartValue" SG_ 1618 Point_92_X 3276;
BA_ "GenSigStartValue" SG_ 1618 Point_91_Y 3276;
BA_ "GenSigStartValue" SG_ 1618 Point_91_X 3276;
BA_ "GenSigStartValue" SG_ 1618 Point_90_Y 3276;
BA_ "GenSigStartValue" SG_ 1618 Point_90_X 3276;
BA_ "GenSigStartValue" SG_ 1731 Point_89_Y 3276;
BA_ "GenSigStartValue" SG_ 1731 Point_89_X 3276;
BA_ "GenSigStartValue" SG_ 1731 Point_88_Y 3276;
BA_ "GenSigStartValue" SG_ 1731 Point_88_X 3276;
BA_ "GenSigStartValue" SG_ 1731 Point_87_Y 3276;
BA_ "GenSigStartValue" SG_ 1731 Point_87_X 3276;
BA_ "GenSigStartValue" SG_ 1731 Point_86_Y 3276;
BA_ "GenSigStartValue" SG_ 1731 Point_86_X 3276;
BA_ "GenSigStartValue" SG_ 1731 Point_85_Y 3276;
BA_ "GenSigStartValue" SG_ 1731 Point_85_X 3276;
BA_ "GenSigStartValue" SG_ 1731 Point_84_Y 3276;
BA_ "GenSigStartValue" SG_ 1731 Point_84_X 3276;
BA_ "GenSigStartValue" SG_ 1731 Point_83_Y 3276;
BA_ "GenSigStartValue" SG_ 1731 Point_83_X 3276;
BA_ "GenSigStartValue" SG_ 1731 Point_82_Y 3276;
BA_ "GenSigStartValue" SG_ 1731 Point_82_X 3276;
BA_ "GenSigStartValue" SG_ 1731 Point_81_Y 3276;
BA_ "GenSigStartValue" SG_ 1731 Point_81_X 3276;
BA_ "GenSigStartValue" SG_ 1731 Point_80_Y 3276;
BA_ "GenSigStartValue" SG_ 1731 Point_80_X 3276;
BA_ "GenSigStartValue" SG_ 1730 Point_79_Y 3276;
BA_ "GenSigStartValue" SG_ 1730 Point_79_X 3276;
BA_ "GenSigStartValue" SG_ 1730 Point_78_Y 3276;
BA_ "GenSigStartValue" SG_ 1730 Point_78_X 3276;
BA_ "GenSigStartValue" SG_ 1730 Point_77_Y 3276;
BA_ "GenSigStartValue" SG_ 1730 Point_77_X 3276;
BA_ "GenSigStartValue" SG_ 1730 Point_76_Y 3276;
BA_ "GenSigStartValue" SG_ 1730 Point_76_X 3276;
BA_ "GenSigStartValue" SG_ 1730 Point_75_Y 3276;
BA_ "GenSigStartValue" SG_ 1730 Point_75_X 3276;
BA_ "GenSigStartValue" SG_ 1730 Point_74_Y 3276;
BA_ "GenSigStartValue" SG_ 1730 Point_74_X 3276;
BA_ "GenSigStartValue" SG_ 1730 Point_73_Y 3276;
BA_ "GenSigStartValue" SG_ 1730 Point_73_X 3276;
BA_ "GenSigStartValue" SG_ 1730 Point_72_Y 3276;
BA_ "GenSigStartValue" SG_ 1730 Point_72_X 3276;
BA_ "GenSigStartValue" SG_ 1730 Point_71_Y 3276;
BA_ "GenSigStartValue" SG_ 1730 Point_71_X 3276;
BA_ "GenSigStartValue" SG_ 1730 Point_70_Y 3276;
BA_ "GenSigStartValue" SG_ 1730 Point_70_X 3276;
BA_ "GenSigStartValue" SG_ 1729 Point_69_Y 3276;
BA_ "GenSigStartValue" SG_ 1729 Point_69_X 3276;
BA_ "GenSigStartValue" SG_ 1729 Point_68_Y 3276;
BA_ "GenSigStartValue" SG_ 1729 Point_68_X 3276;
BA_ "GenSigStartValue" SG_ 1729 Point_67_Y 3276;
BA_ "GenSigStartValue" SG_ 1729 Point_67_X 3276;
BA_ "GenSigStartValue" SG_ 1729 Point_66_Y 3276;
BA_ "GenSigStartValue" SG_ 1729 Point_66_X 3276;
BA_ "GenSigStartValue" SG_ 1729 Point_65_Y 3276;
BA_ "GenSigStartValue" SG_ 1729 Point_65_X 3276;
BA_ "GenSigStartValue" SG_ 1729 Point_64_Y 3276;
BA_ "GenSigStartValue" SG_ 1729 Point_64_X 3276;
BA_ "GenSigStartValue" SG_ 1729 Point_63_Y 3276;
BA_ "GenSigStartValue" SG_ 1729 Point_63_X 3276;
BA_ "GenSigStartValue" SG_ 1729 Point_62_Y 3276;
BA_ "GenSigStartValue" SG_ 1729 Point_62_X 3276;
BA_ "GenSigStartValue" SG_ 1729 Point_61_Y 3276;
BA_ "GenSigStartValue" SG_ 1729 Point_61_X 3276;
BA_ "GenSigStartValue" SG_ 1729 Point_60_Y 3276;
BA_ "GenSigStartValue" SG_ 1729 Point_60_X 3276;
BA_ "GenSigStartValue" SG_ 1728 Point_59_Y 3276;
BA_ "GenSigStartValue" SG_ 1728 Point_59_X 3276;
BA_ "GenSigStartValue" SG_ 1728 Point_58_Y 3276;
BA_ "GenSigStartValue" SG_ 1728 Point_58_X 3276;
BA_ "GenSigStartValue" SG_ 1728 Point_57_Y 3276;
BA_ "GenSigStartValue" SG_ 1728 Point_57_X 3276;
BA_ "GenSigStartValue" SG_ 1728 Point_56_Y 3276;
BA_ "GenSigStartValue" SG_ 1728 Point_56_X 3276;
BA_ "GenSigStartValue" SG_ 1728 Point_55_Y 3276;
BA_ "GenSigStartValue" SG_ 1728 Point_55_X 3276;
BA_ "GenSigStartValue" SG_ 1728 Point_54_Y 3276;
BA_ "GenSigStartValue" SG_ 1728 Point_54_X 3276;
BA_ "GenSigStartValue" SG_ 1728 Point_53_Y 3276;
BA_ "GenSigStartValue" SG_ 1728 Point_53_X 3276;
BA_ "GenSigStartValue" SG_ 1728 Point_52_Y 3276;
BA_ "GenSigStartValue" SG_ 1728 Point_52_X 3276;
BA_ "GenSigStartValue" SG_ 1728 Point_51_Y 3276;
BA_ "GenSigStartValue" SG_ 1728 Point_51_X 3276;
BA_ "GenSigStartValue" SG_ 1728 Point_50_Y 3276;
BA_ "GenSigStartValue" SG_ 1728 Point_50_X 3276;
BA_ "GenSigStartValue" SG_ 1727 Point_49_Y 3276;
BA_ "GenSigStartValue" SG_ 1727 Point_49_X 3276;
BA_ "GenSigStartValue" SG_ 1727 Point_48_Y 3276;
BA_ "GenSigStartValue" SG_ 1727 Point_48_X 3276;
BA_ "GenSigStartValue" SG_ 1727 Point_47_Y 3276;
BA_ "GenSigStartValue" SG_ 1727 Point_47_X 3276;
BA_ "GenSigStartValue" SG_ 1727 Point_46_Y 3276;
BA_ "GenSigStartValue" SG_ 1727 Point_46_X 3276;
BA_ "GenSigStartValue" SG_ 1727 Point_45_Y 3276;
BA_ "GenSigStartValue" SG_ 1727 Point_45_X 3276;
BA_ "GenSigStartValue" SG_ 1727 Point_44_Y 3276;
BA_ "GenSigStartValue" SG_ 1727 Point_44_X 3276;
BA_ "GenSigStartValue" SG_ 1727 Point_43_Y 3276;
BA_ "GenSigStartValue" SG_ 1727 Point_43_X 3276;
BA_ "GenSigStartValue" SG_ 1727 Point_42_Y 3276;
BA_ "GenSigStartValue" SG_ 1727 Point_42_X 3276;
BA_ "GenSigStartValue" SG_ 1727 Point_41_Y 3276;
BA_ "GenSigStartValue" SG_ 1727 Point_41_X 3276;
BA_ "GenSigStartValue" SG_ 1727 Point_40_Y 3276;
BA_ "GenSigStartValue" SG_ 1727 Point_40_X 3276;
BA_ "GenSigStartValue" SG_ 1726 Point_39_Y 3276;
BA_ "GenSigStartValue" SG_ 1726 Point_39_X 3276;
BA_ "GenSigStartValue" SG_ 1726 Point_38_Y 3276;
BA_ "GenSigStartValue" SG_ 1726 Point_38_X 3276;
BA_ "GenSigStartValue" SG_ 1726 Point_37_Y 3276;
BA_ "GenSigStartValue" SG_ 1726 Point_37_X 3276;
BA_ "GenSigStartValue" SG_ 1726 Point_36_Y 3276;
BA_ "GenSigStartValue" SG_ 1726 Point_36_X 3276;
BA_ "GenSigStartValue" SG_ 1726 Point_35_Y 3276;
BA_ "GenSigStartValue" SG_ 1726 Point_35_X 3276;
BA_ "GenSigStartValue" SG_ 1726 Point_34_Y 3276;
BA_ "GenSigStartValue" SG_ 1726 Point_34_X 3276;
BA_ "GenSigStartValue" SG_ 1726 Point_33_Y 3276;
BA_ "GenSigStartValue" SG_ 1726 Point_33_X 3276;
BA_ "GenSigStartValue" SG_ 1726 Point_32_Y 3276;
BA_ "GenSigStartValue" SG_ 1726 Point_32_X 3276;
BA_ "GenSigStartValue" SG_ 1726 Point_31_Y 3276;
BA_ "GenSigStartValue" SG_ 1726 Point_31_X 3276;
BA_ "GenSigStartValue" SG_ 1726 Point_30_Y 3276;
BA_ "GenSigStartValue" SG_ 1726 Point_30_X 3276;
BA_ "GenSigStartValue" SG_ 1725 Point_29_Y 3276;
BA_ "GenSigStartValue" SG_ 1725 Point_29_X 3276;
BA_ "GenSigStartValue" SG_ 1725 Point_28_Y 3276;
BA_ "GenSigStartValue" SG_ 1725 Point_28_X 3276;
BA_ "GenSigStartValue" SG_ 1725 Point_27_Y 3276;
BA_ "GenSigStartValue" SG_ 1725 Point_27_X 3276;
BA_ "GenSigStartValue" SG_ 1725 Point_26_Y 3276;
BA_ "GenSigStartValue" SG_ 1725 Point_26_X 3276;
BA_ "GenSigStartValue" SG_ 1725 Point_25_Y 3276;
BA_ "GenSigStartValue" SG_ 1725 Point_25_X 3276;
BA_ "GenSigStartValue" SG_ 1725 Point_24_Y 3276;
BA_ "GenSigStartValue" SG_ 1725 Point_24_X 3276;
BA_ "GenSigStartValue" SG_ 1725 Point_23_Y 3276;
BA_ "GenSigStartValue" SG_ 1725 Point_23_X 3276;
BA_ "GenSigStartValue" SG_ 1725 Point_22_Y 3276;
BA_ "GenSigStartValue" SG_ 1725 Point_22_X 3276;
BA_ "GenSigStartValue" SG_ 1725 Point_21_Y 3276;
BA_ "GenSigStartValue" SG_ 1725 Point_21_X 3276;
BA_ "GenSigStartValue" SG_ 1725 Point_20_Y 3276;
BA_ "GenSigStartValue" SG_ 1725 Point_20_X 3276;
BA_ "GenSigStartValue" SG_ 1724 Point_19_Y 3276;
BA_ "GenSigStartValue" SG_ 1724 Point_19_X 3276;
BA_ "GenSigStartValue" SG_ 1724 Point_18_Y 3276;
BA_ "GenSigStartValue" SG_ 1724 Point_18_X 3276;
BA_ "GenSigStartValue" SG_ 1724 Point_17_Y 3276;
BA_ "GenSigStartValue" SG_ 1724 Point_17_X 3276;
BA_ "GenSigStartValue" SG_ 1724 Point_16_Y 3276;
BA_ "GenSigStartValue" SG_ 1724 Point_16_X 3276;
BA_ "GenSigStartValue" SG_ 1724 Point_15_Y 3276;
BA_ "GenSigStartValue" SG_ 1724 Point_15_X 3276;
BA_ "GenSigStartValue" SG_ 1724 Point_14_Y 3276;
BA_ "GenSigStartValue" SG_ 1724 Point_14_X 3276;
BA_ "GenSigStartValue" SG_ 1724 Point_13_Y 3276;
BA_ "GenSigStartValue" SG_ 1724 Point_13_X 3276;
BA_ "GenSigStartValue" SG_ 1724 Point_12_Y 3276;
BA_ "GenSigStartValue" SG_ 1724 Point_12_X 3276;
BA_ "GenSigStartValue" SG_ 1724 Point_11_Y 3276;
BA_ "GenSigStartValue" SG_ 1724 Point_11_X 3276;
BA_ "GenSigStartValue" SG_ 1724 Point_10_Y 3276;
BA_ "GenSigStartValue" SG_ 1724 Point_10_X 3276;
BA_ "GenSigStartValue" SG_ 1723 Point_09_Y 3276;
BA_ "GenSigStartValue" SG_ 1723 Point_09_X 3276;
BA_ "GenSigStartValue" SG_ 1723 Point_08_Y 3276;
BA_ "GenSigStartValue" SG_ 1723 Point_08_X 3276;
BA_ "GenSigStartValue" SG_ 1723 Point_07_Y 3276;
BA_ "GenSigStartValue" SG_ 1723 Point_07_X 3276;
BA_ "GenSigStartValue" SG_ 1723 Point_06_Y 3276;
BA_ "GenSigStartValue" SG_ 1723 Point_06_X 3276;
BA_ "GenSigStartValue" SG_ 1723 Point_05_Y 3276;
BA_ "GenSigStartValue" SG_ 1723 Point_05_X 3276;
BA_ "GenSigStartValue" SG_ 1723 Point_04_Y 3276;
BA_ "GenSigStartValue" SG_ 1723 Point_04_X 3276;
BA_ "GenSigStartValue" SG_ 1723 Point_03_Y 3276;
BA_ "GenSigStartValue" SG_ 1723 Point_03_X 3276;
BA_ "GenSigStartValue" SG_ 1723 Point_02_Y 3276;
BA_ "GenSigStartValue" SG_ 1723 Point_02_X 3276;
BA_ "GenSigStartValue" SG_ 1723 Point_01_Y 3276;
BA_ "GenSigStartValue" SG_ 1723 Point_01_X 3276;
BA_ "GenSigStartValue" SG_ 1723 Point_00_Y 3276;
BA_ "GenSigStartValue" SG_ 1723 Point_00_X 3276;
VAL_ 1617 PDC_RRSSectorWarning 4 "Zone4" 3 "Zone3" 2 "Zone2" 1 "Zone1" 0 "无障碍物" ;
VAL_ 1617 PDC_RRMSectorWarning 4 "Zone4" 3 "Zone3" 2 "Zone2" 1 "Zone1" 0 "无障碍物" ;
VAL_ 1617 PDC_RRCSectorWarning 4 "Zone4" 3 "Zone3" 2 "Zone2" 1 "Zone1" 0 "无障碍物" ;
VAL_ 1617 PDC_RMSSectorWarning 4 "Zone4" 3 "Zone3" 2 "Zone2" 1 "Zone1" 0 "无障碍物" ;
VAL_ 1617 PDC_RLSSectorWarning 4 "Zone4" 3 "Zone3" 2 "Zone2" 1 "Zone1" 0 "无障碍物" ;
VAL_ 1617 PDC_RLMSectorWarning 4 "Zone4" 3 "Zone3" 2 "Zone2" 1 "Zone1" 0 "无障碍物" ;
VAL_ 1617 PDC_RLCSectorWarning 4 "Zone4" 3 "Zone3" 2 "Zone2" 1 "Zone1" 0 "无障碍物" ;
VAL_ 1617 PDC_LMSSectorWarning 4 "Zone4" 3 "Zone3" 2 "Zone2" 1 "Zone1" 0 "无障碍物" ;
VAL_ 1617 PDC_FRSSectorWarning 4 "Zone4" 3 "Zone3" 2 "Zone2" 1 "Zone1" 0 "无障碍物" ;
VAL_ 1617 PDC_FRMSectorWarning 4 "Zone4" 3 "Zone3" 2 "Zone2" 1 "Zone1" 0 "无障碍物" ;
VAL_ 1617 PDC_FRCSectorWarning 4 "Zone4" 3 "Zone3" 2 "Zone2" 1 "Zone1" 0 "无障碍物" ;
VAL_ 1617 PDC_FLSSectorWarning 4 "Zone4" 3 "Zone3" 2 "Zone2" 1 "Zone1" 0 "无障碍物" ;
VAL_ 1617 PDC_FLMSectorWarning 4 "Zone4" 3 "Zone3" 2 "Zone2" 1 "Zone1" 0 "无障碍物" ;
VAL_ 1617 PDC_FLCSectorWarning 4 "Zone4" 3 "Zone3" 2 "Zone2" 1 "Zone1" 0 "无障碍物" ;
VAL_ 1600 VehiclePosition_Gear 3 "R" 2 "P" 1 "D" 0 "N" ;
VAL_ 1863 APAParkingMode 1 "Vertical" 0 "Horizontal" ;
VAL_ 1863 APAParkingLocation 1 "Left" 0 "Right" ;
VAL_ 1863 APAParkingInteriorEnableSwitch 1 "Open" 0 "Close" ;
VAL_ 1863 APAParkingFlag 1 "AutoParkingEnabled" 0 "AutoParkingFinish" ;
VAL_ 1862 Left_ParkingSlot5_Depth 1022 "No Space" 1023 " Invalid" ;
VAL_ 1862 Left_ParkingSlot5_Length 2046 "No Space" 2047 " Invalid" ;
VAL_ 1862 LeftParkingSlot5_HeightProperty 2 "TALL" 1 "LOW" ;
VAL_ 1862 Left_ParkingSlot5_Type 0 "None" 1 "LeftParallel" 2 "RightParallel" 3 "LeftCross" 4 "RightCross" 5 "Reserved" 7 " Invalid" ;
VAL_ 1862 Left_ParkingSlot5_ID 0 "No Space" 255 " Invalid" ;
VAL_ 1721 Left_ParkingSlot4_Depth 1022 "No Space" 1023 " Invalid" ;
VAL_ 1721 Left_ParkingSlot4_Length 2046 "No Space" 2047 " Invalid" ;
VAL_ 1721 LeftParkingSlot4_HeightProperty 2 "TALL" 1 "LOW" ;
VAL_ 1721 Left_ParkingSlot4_Type 0 "None" 1 "LeftParallel" 2 "RightParallel" 3 "LeftCross" 4 "RightCross" 5 "Reserved" 7 " Invalid" ;
VAL_ 1721 Left_ParkingSlot4_ID 0 "No Space" 255 " Invalid" ;
VAL_ 1721 Left_ParkingSlot3_Depth 1022 "No Space" 1023 " Invalid" ;
VAL_ 1721 Left_ParkingSlot3_Length 2046 "No Space" 2047 " Invalid" ;
VAL_ 1721 LeftParkingSlot3_HeightProperty 2 "TALL" 1 "LOW" ;
VAL_ 1721 Left_ParkingSlot3_Type 0 "None" 1 "LeftParallel" 2 "RightParallel" 3 "LeftCross" 4 "RightCross" 5 "Reserved" 7 " Invalid" ;
VAL_ 1721 Left_ParkingSlot3_ID 0 "No Space" 255 " Invalid" ;
VAL_ 1720 Left_ParkingSlot2_Depth 1022 "No Space" 1023 " Invalid" ;
VAL_ 1720 Left_ParkingSlot2_Length 2046 "No Space" 2047 " Invalid" ;
VAL_ 1720 LeftParkingSlot2_HeightProperty 2 "TALL" 1 "LOW" ;
VAL_ 1720 Left_ParkingSlot2_Type 0 "None" 1 "LeftParallel" 2 "RightParallel" 3 "LeftCross" 4 "RightCross" 5 "Reserved" 7 " Invalid" ;
VAL_ 1720 Left_ParkingSlot2_ID 0 "No Space" 255 " Invalid" ;
VAL_ 1720 Left_ParkingSlot1_Depth 1022 "No Space" 1023 " Invalid" ;
VAL_ 1720 Left_ParkingSlot1_Length 2046 "No Space" 2047 " Invalid" ;
VAL_ 1720 LeftParkingSlot1_HeightProperty 2 "TALL" 1 "LOW" ;
VAL_ 1720 Left_ParkingSlot1_Type 0 "None" 1 "LeftParallel" 2 "RightParallel" 3 "LeftCross" 4 "RightCross" 5 "Reserved" 7 " Invalid" ;
VAL_ 1720 Left_ParkingSlot1_ID 0 "No Space" 255 " Invalid" ;
VAL_ 1859 Right_ParkingSlot5_Depth 1022 "No Space" 1023 " Invalid" ;
VAL_ 1859 Right_ParkingSlot5_Length 2046 "No Space" 2047 " Invalid" ;
VAL_ 1859 RightParkingSlot5_HeightProperty 2 "TALL" 1 "LOW" ;
VAL_ 1859 Right_ParkingSlot5_Type 0 "None" 1 "LeftParallel" 2 "RightParallel" 3 "LeftCross" 4 "RightCross" 5 "Reserved" 7 " Invalid" ;
VAL_ 1859 Right_ParkingSlot5_ID 0 "No Space" 255 " Invalid" ;
VAL_ 1719 Right_ParkingSlot4_Depth 1022 "No Space" 1023 " Invalid" ;
VAL_ 1719 Right_ParkingSlot4_Length 2046 "No Space" 2047 " Invalid" ;
VAL_ 1719 RightParkingSlot4_HeightProperty 2 "TALL" 1 "LOW" ;
VAL_ 1719 Right_ParkingSlot4_Type 0 "None" 1 "LeftParallel" 2 "RightParallel" 3 "LeftCross" 4 "RightCross" 5 "Reserved" 7 " Invalid" ;
VAL_ 1719 Right_ParkingSlot4_ID 0 "No Space" 255 " Invalid" ;
VAL_ 1719 Right_ParkingSlot3_Depth 1022 "No Space" 1023 " Invalid" ;
VAL_ 1719 Right_ParkingSlot3_Length 2046 "No Space" 2047 " Invalid" ;
VAL_ 1719 RightParkingSlot3_HeightProperty 2 "TALL" 1 "LOW" ;
VAL_ 1719 Right_ParkingSlot3_Type 0 "None" 1 "LeftParallel" 2 "RightParallel" 3 "LeftCross" 4 "RightCross" 5 "Reserved" 7 " Invalid" ;
VAL_ 1719 Right_ParkingSlot3_ID 0 "No Space" 255 " Invalid" ;
VAL_ 1718 Right_ParkingSlot2_Depth 1022 "No Space" 1023 " Invalid" ;
VAL_ 1718 Right_ParkingSlot2_Length 2046 "No Space" 2047 " Invalid" ;
VAL_ 1718 RightParkingSlot2_HeightProperty 2 "TALL" 1 "LOW" ;
VAL_ 1718 Right_ParkingSlot2_Type 0 "None" 1 "LeftParallel" 2 "RightParallel" 3 "LeftCross" 4 "RightCross" 5 "Reserved" 7 " Invalid" ;
VAL_ 1718 Right_ParkingSlot2_ID 0 "No Space" 255 " Invalid" ;
VAL_ 1718 Right_ParkingSlot1_Depth 1022 "No Space" 1023 " Invalid" ;
VAL_ 1718 Right_ParkingSlot1_Length 2046 "No Space" 2047 " Invalid" ;
VAL_ 1718 RightParkingSlot1_HeightProperty 2 "TALL" 1 "LOW" ;
VAL_ 1718 Right_ParkingSlot1_Type 0 "None" 1 "LeftParallel" 2 "RightParallel" 3 "LeftCross" 4 "RightCross" 5 "Reserved" 7 " Invalid" ;
VAL_ 1718 Right_ParkingSlot1_ID 0 "No Space" 255 " Invalid" ;
VAL_ 1620 Point_119_Attribute 2 "High" 1 "Low" 0 "None" ;
VAL_ 1620 Point_118_Attribute 2 "High" 1 "Low" 0 "None" ;
VAL_ 1620 Point_117_Attribute 2 "High" 1 "Low" 0 "None" ;
VAL_ 1620 Point_116_Attribute 2 "High" 1 "Low" 0 "None" ;
VAL_ 1620 Point_115_Attribute 2 "High" 1 "Low" 0 "None" ;
VAL_ 1620 Point_114_Attribute 2 "High" 1 "Low" 0 "None" ;
VAL_ 1620 Point_113_Attribute 2 "High" 1 "Low" 0 "None" ;
VAL_ 1620 Point_112_Attribute 2 "High" 1 "Low" 0 "None" ;
VAL_ 1620 Point_111_Attribute 2 "High" 1 "Low" 0 "None" ;
VAL_ 1620 Point_110_Attribute 2 "High" 1 "Low" 0 "None" ;
VAL_ 1619 Point_109_Attribute 2 "High" 1 "Low" 0 "None" ;
VAL_ 1619 Point_108_Attribute 2 "High" 1 "Low" 0 "None" ;
VAL_ 1619 Point_107_Attribute 2 "High" 1 "Low" 0 "None" ;
VAL_ 1619 Point_106_Attribute 2 "High" 1 "Low" 0 "None" ;
VAL_ 1619 Point_105_Attribute 2 "High" 1 "Low" 0 "None" ;
VAL_ 1619 Point_104_Attribute 2 "High" 1 "Low" 0 "None" ;
VAL_ 1619 Point_103_Attribute 2 "High" 1 "Low" 0 "None" ;
VAL_ 1619 Point_102_Attribute 2 "High" 1 "Low" 0 "None" ;
VAL_ 1619 Point_101_Attribute 2 "High" 1 "Low" 0 "None" ;
VAL_ 1619 Point_100_Attribute 2 "High" 1 "Low" 0 "None" ;
VAL_ 1618 Point_99_Attribute 2 "High" 1 "Low" 0 "None" ;
VAL_ 1618 Point_98_Attribute 2 "High" 1 "Low" 0 "None" ;
VAL_ 1618 Point_97_Attribute 2 "High" 1 "Low" 0 "None" ;
VAL_ 1618 Point_96_Attribute 2 "High" 1 "Low" 0 "None" ;
VAL_ 1618 Point_95_Attribute 2 "High" 1 "Low" 0 "None" ;
VAL_ 1618 Point_94_Attribute 2 "High" 1 "Low" 0 "None" ;
VAL_ 1618 Point_93_Attribute 2 "High" 1 "Low" 0 "None" ;
VAL_ 1618 Point_92_Attribute 2 "High" 1 "Low" 0 "None" ;
VAL_ 1618 Point_91_Attribute 2 "High" 1 "Low" 0 "None" ;
VAL_ 1618 Point_90_Attribute 2 "High" 1 "Low" 0 "None" ;
VAL_ 1731 Point_89_Attribute 2 "High" 1 "Low" 0 "None" ;
VAL_ 1731 Point_88_Attribute 2 "High" 1 "Low" 0 "None" ;
VAL_ 1731 Point_87_Attribute 2 "High" 1 "Low" 0 "None" ;
VAL_ 1731 Point_86_Attribute 2 "High" 1 "Low" 0 "None" ;
VAL_ 1731 Point_85_Attribute 2 "High" 1 "Low" 0 "None" ;
VAL_ 1731 Point_84_Attribute 2 "High" 1 "Low" 0 "None" ;
VAL_ 1731 Point_83_Attribute 2 "High" 1 "Low" 0 "None" ;
VAL_ 1731 Point_82_Attribute 2 "High" 1 "Low" 0 "None" ;
VAL_ 1731 Point_81_Attribute 2 "High" 1 "Low" 0 "None" ;
VAL_ 1731 Point_80_Attribute 2 "High" 1 "Low" 0 "None" ;
VAL_ 1730 Point_79_Attribute 2 "High" 1 "Low" 0 "None" ;
VAL_ 1730 Point_78_Attribute 2 "High" 1 "Low" 0 "None" ;
VAL_ 1730 Point_77_Attribute 2 "High" 1 "Low" 0 "None" ;
VAL_ 1730 Point_76_Attribute 2 "High" 1 "Low" 0 "None" ;
VAL_ 1730 Point_75_Attribute 2 "High" 1 "Low" 0 "None" ;
VAL_ 1730 Point_74_Attribute 2 "High" 1 "Low" 0 "None" ;
VAL_ 1730 Point_73_Attribute 2 "High" 1 "Low" 0 "None" ;
VAL_ 1730 Point_72_Attribute 2 "High" 1 "Low" 0 "None" ;
VAL_ 1730 Point_71_Attribute 2 "High" 1 "Low" 0 "None" ;
VAL_ 1730 Point_70_Attribute 2 "High" 1 "Low" 0 "None" ;
VAL_ 1729 Point_69_Attribute 2 "High" 1 "Low" 0 "None" ;
VAL_ 1729 Point_68_Attribute 2 "High" 1 "Low" 0 "None" ;
VAL_ 1729 Point_67_Attribute 2 "High" 1 "Low" 0 "None" ;
VAL_ 1729 Point_66_Attribute 2 "High" 1 "Low" 0 "None" ;
VAL_ 1729 Point_65_Attribute 2 "High" 1 "Low" 0 "None" ;
VAL_ 1729 Point_64_Attribute 2 "High" 1 "Low" 0 "None" ;
VAL_ 1729 Point_63_Attribute 2 "High" 1 "Low" 0 "None" ;
VAL_ 1729 Point_62_Attribute 2 "High" 1 "Low" 0 "None" ;
VAL_ 1729 Point_61_Attribute 2 "High" 1 "Low" 0 "None" ;
VAL_ 1729 Point_60_Attribute 2 "High" 1 "Low" 0 "None" ;
VAL_ 1728 Point_59_Attribute 2 "High" 1 "Low" 0 "None" ;
VAL_ 1728 Point_58_Attribute 2 "High" 1 "Low" 0 "None" ;
VAL_ 1728 Point_57_Attribute 2 "High" 1 "Low" 0 "None" ;
VAL_ 1728 Point_56_Attribute 2 "High" 1 "Low" 0 "None" ;
VAL_ 1728 Point_55_Attribute 2 "High" 1 "Low" 0 "None" ;
VAL_ 1728 Point_54_Attribute 2 "High" 1 "Low" 0 "None" ;
VAL_ 1728 Point_53_Attribute 2 "High" 1 "Low" 0 "None" ;
VAL_ 1728 Point_52_Attribute 2 "High" 1 "Low" 0 "None" ;
VAL_ 1728 Point_51_Attribute 2 "High" 1 "Low" 0 "None" ;
VAL_ 1728 Point_50_Attribute 2 "High" 1 "Low" 0 "None" ;
VAL_ 1727 Point_49_Attribute 2 "High" 1 "Low" 0 "None" ;
VAL_ 1727 Point_48_Attribute 2 "High" 1 "Low" 0 "None" ;
VAL_ 1727 Point_47_Attribute 2 "High" 1 "Low" 0 "None" ;
VAL_ 1727 Point_46_Attribute 2 "High" 1 "Low" 0 "None" ;
VAL_ 1727 Point_45_Attribute 2 "High" 1 "Low" 0 "None" ;
VAL_ 1727 Point_44_Attribute 2 "High" 1 "Low" 0 "None" ;
VAL_ 1727 Point_43_Attribute 2 "High" 1 "Low" 0 "None" ;
VAL_ 1727 Point_42_Attribute 2 "High" 1 "Low" 0 "None" ;
VAL_ 1727 Point_41_Attribute 2 "High" 1 "Low" 0 "None" ;
VAL_ 1727 Point_40_Attribute 2 "High" 1 "Low" 0 "None" ;
VAL_ 1726 Point_39_Attribute 2 "High" 1 "Low" 0 "None" ;
VAL_ 1726 Point_38_Attribute 2 "High" 1 "Low" 0 "None" ;
VAL_ 1726 Point_37_Attribute 2 "High" 1 "Low" 0 "None" ;
VAL_ 1726 Point_36_Attribute 2 "High" 1 "Low" 0 "None" ;
VAL_ 1726 Point_35_Attribute 2 "High" 1 "Low" 0 "None" ;
VAL_ 1726 Point_34_Attribute 2 "High" 1 "Low" 0 "None" ;
VAL_ 1726 Point_33_Attribute 2 "High" 1 "Low" 0 "None" ;
VAL_ 1726 Point_32_Attribute 2 "High" 1 "Low" 0 "None" ;
VAL_ 1726 Point_31_Attribute 2 "High" 1 "Low" 0 "None" ;
VAL_ 1726 Point_30_Attribute 2 "High" 1 "Low" 0 "None" ;
VAL_ 1725 Point_29_Attribute 2 "High" 1 "Low" 0 "None" ;
VAL_ 1725 Point_28_Attribute 2 "High" 1 "Low" 0 "None" ;
VAL_ 1725 Point_27_Attribute 2 "High" 1 "Low" 0 "None" ;
VAL_ 1725 Point_26_Attribute 2 "High" 1 "Low" 0 "None" ;
VAL_ 1725 Point_25_Attribute 2 "High" 1 "Low" 0 "None" ;
VAL_ 1725 Point_24_Attribute 2 "High" 1 "Low" 0 "None" ;
VAL_ 1725 Point_23_Attribute 2 "High" 1 "Low" 0 "None" ;
VAL_ 1725 Point_22_Attribute 2 "High" 1 "Low" 0 "None" ;
VAL_ 1725 Point_21_Attribute 2 "High" 1 "Low" 0 "None" ;
VAL_ 1725 Point_20_Attribute 2 "High" 1 "Low" 0 "None" ;
VAL_ 1724 Point_19_Attribute 2 "High" 1 "Low" 0 "None" ;
VAL_ 1724 Point_18_Attribute 2 "High" 1 "Low" 0 "None" ;
VAL_ 1724 Point_17_Attribute 2 "High" 1 "Low" 0 "None" ;
VAL_ 1724 Point_16_Attribute 2 "High" 1 "Low" 0 "None" ;
VAL_ 1724 Point_15_Attribute 2 "High" 1 "Low" 0 "None" ;
VAL_ 1724 Point_14_Attribute 2 "High" 1 "Low" 0 "None" ;
VAL_ 1724 Point_13_Attribute 2 "High" 1 "Low" 0 "None" ;
VAL_ 1724 Point_12_Attribute 2 "High" 1 "Low" 0 "None" ;
VAL_ 1724 Point_11_Attribute 2 "High" 1 "Low" 0 "None" ;
VAL_ 1724 Point_10_Attribute 2 "High" 1 "Low" 0 "None" ;
VAL_ 1723 Point_09_Attribute 2 "High" 1 "Low" 0 "None" ;
VAL_ 1723 Point_08_Attribute 2 "High" 1 "Low" 0 "None" ;
VAL_ 1723 Point_07_Attribute 2 "High" 1 "Low" 0 "None" ;
VAL_ 1723 Point_06_Attribute 2 "High" 1 "Low" 0 "None" ;
VAL_ 1723 Point_05_Attribute 2 "High" 1 "Low" 0 "None" ;
VAL_ 1723 Point_04_Attribute 2 "High" 1 "Low" 0 "None" ;
VAL_ 1723 Point_03_Attribute 2 "High" 1 "Low" 0 "None" ;
VAL_ 1723 Point_02_Attribute 2 "High" 1 "Low" 0 "None" ;
VAL_ 1723 Point_00_Attribute 2 "High" 1 "Low" 0 "None" ;
VAL_ 1723 Point_01_Attribute 2 "High" 1 "Low" 0 "None" ;
VAL_ 513 PAS_sonar1_Blind 0 "False" 1 "Ture" ;
VAL_ 513 PAS_sonar2_Blind 0 "False" 1 "Ture" ;
VAL_ 513 PAS_sonar3_Blind 0 "False" 1 "Ture" ;
VAL_ 513 PAS_sonar4_Blind 0 "False" 1 "Ture" ;
VAL_ 513 PAS_sonar0_Blind 0 "False" 1 "Ture" ;
VAL_ 513 PAS_sonar5_Blind 0 "False" 1 "Ture" ;
VAL_ 513 PASDistanceFrontRollingCounter 15 "Invalid" ;
VAL_ 513 Fill4bit 15 "填充位" ;
VAL_ 514 PAS_sonar7_Blind 0 "False" 1 "Ture" ;
VAL_ 514 PAS_sonar8_Blind 0 "False" 1 "Ture" ;
VAL_ 514 PAS_sonar9_Blind 0 "False" 1 "Ture" ;
VAL_ 514 PAS_sonar10_Blind 0 "False" 1 "Ture" ;
VAL_ 514 PAS_sonar6_Blind 0 "False" 1 "Ture" ;
VAL_ 514 PAS_sonar11_Blind 0 "False" 1 "Ture" ;
VAL_ 514 PAS_Distance_Rear_RollingCounter 15 "Invalid" ;
VAL_ 514 Fill4bit 15 "填充位" ;
VAL_ 515 PAS_Sonar0_Emit 0 "off" 1 "receive only" 2 "emit and receive" ;
VAL_ 515 PAS_Sonar1_Emit 0 "off" 1 "receive only" 2 "emit and receive" ;
VAL_ 515 PAS_Sonar2_Emit 0 "off" 1 "receive only" 2 "emit and receive" ;
VAL_ 515 PAS_Sonar3_Emit 0 "off" 1 "receive only" 2 "emit and receive" ;
VAL_ 515 PAS_Sonar4_Emit 0 "off" 1 "receive only" 2 "emit and receive" ;
VAL_ 515 PAS_Sonar5_Emit 0 "off" 1 "receive only" 2 "emit and receive" ;
VAL_ 515 PASSonarInfoFrontRollingCounter 15 "Invalid" ;
VAL_ 515 Fill4bit 15 "填充位" ;
